VERSION ""

NS_ :

BS_:

BU_: BCM_PB ECM_PB TCM_PB Router_PB APA_PB SBSA_PB EBCM_PB IPC_PB SDM_PB EPS_PB AHL_AFL_PB ECC_PB ESCL_PB Firewall_PB CGM_PB PFAF_PB IBOOST_PB

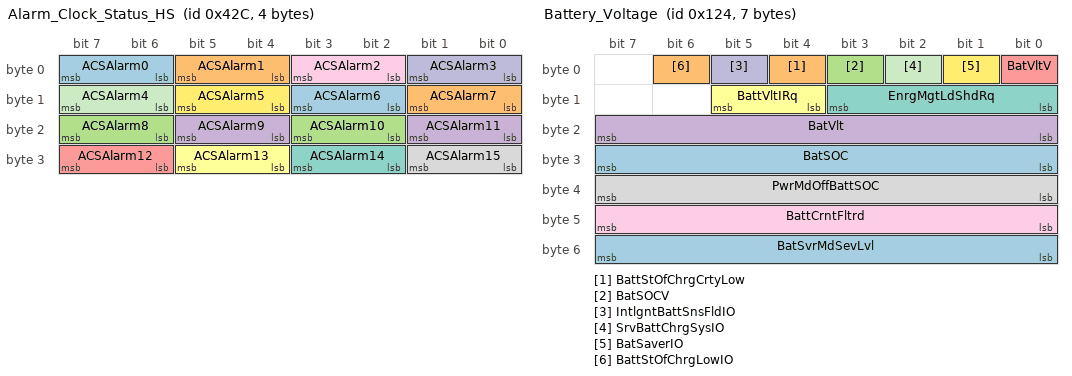
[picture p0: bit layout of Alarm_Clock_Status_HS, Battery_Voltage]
BO_ 1068 Alarm_Clock_Status_HS: 4 BCM_PB
 SG_ ACSAlarm0 : 7|2@0+ (1,0) [0|3] ""  ECC_PB
 SG_ ACSAlarm1 : 5|2@0+ (1,0) [0|3] ""  ECC_PB
 SG_ ACSAlarm10 : 19|2@0+ (1,0) [0|3] ""  ECC_PB
 SG_ ACSAlarm11 : 17|2@0+ (1,0) [0|3] ""  ECC_PB
 SG_ ACSAlarm12 : 31|2@0+ (1,0) [0|3] ""  ECC_PB
 SG_ ACSAlarm13 : 29|2@0+ (1,0) [0|3] ""  ECC_PB
 SG_ ACSAlarm14 : 27|2@0+ (1,0) [0|3] ""  ECC_PB
 SG_ ACSAlarm15 : 25|2@0+ (1,0) [0|3] ""  ECC_PB
 SG_ ACSAlarm2 : 3|2@0+ (1,0) [0|3] ""  ECC_PB
 SG_ ACSAlarm3 : 1|2@0+ (1,0) [0|3] ""  ECC_PB
 SG_ ACSAlarm4 : 15|2@0+ (1,0) [0|3] ""  ECC_PB
 SG_ ACSAlarm5 : 13|2@0+ (1,0) [0|3] ""  ECC_PB
 SG_ ACSAlarm6 : 11|2@0+ (1,0) [0|3] ""  ECC_PB
 SG_ ACSAlarm7 : 9|2@0+ (1,0) [0|3] ""  ECC_PB
 SG_ ACSAlarm8 : 23|2@0+ (1,0) [0|3] ""  ECC_PB
 SG_ ACSAlarm9 : 21|2@0+ (1,0) [0|3] ""  ECC_PB

BO_ 292 Battery_Voltage: 7 BCM_PB
 SG_ BatSOC : 31|8@0+ (0.392157,0) [0|100.000035] "%"  ECC_PB
 SG_ BattStOfChrgCrtyLow : 4|1@0+ (1,0) [0|1] ""  ECC_PB
 SG_ BatSOCV : 3|1@0+ (1,0) [0|1] ""  ECC_PB
 SG_ BatVlt : 23|8@0+ (0.1,3) [3|28.5] "volts"  ECC_PB
 SG_ BatVltV : 0|1@0+ (1,0) [0|1] ""  ECC_PB
 SG_ BattVltIRq : 13|2@0+ (1,0) [0|3] "" Vector__XXX
 SG_ EnrgMgtLdShdRq : 11|4@0+ (1,0) [0|15] ""  ECC_PB
 SG_ PwrMdOffBattSOC : 39|8@0+ (0.392157,0) [0|100.000035] "%" Vector__XXX
 SG_ BattCrntFltrd : 47|8@0- (0.5,0) [-64|63.5] "A"  ECC_PB
 SG_ IntlgntBattSnsFldIO : 5|1@0+ (1,0) [0|1] "" Vector__XXX
 SG_ SrvBattChrgSysIO : 2|1@0+ (1,0) [0|1] "" Vector__XXX
 SG_ BatSaverIO : 1|1@0+ (1,0) [0|1] "" Vector__XXX
 SG_ BatSvrMdSevLvl : 55|8@0+ (1,0) [0|255] "" Vector__XXX
 SG_ BattStOfChrgLowIO : 6|1@0+ (1,0) [0|1] "" Vector__XXX

BO_ 298 Body_Information_HS: 4 BCM_PB
 SG_ DDAjrSwAtv : 9|1@0+ (1,0) [0|1] "" Vector__XXX
 SG_ DDAjrSwAtvM : 5|1@0+ (1,0) [0|1] "" Vector__XXX
 SG_ DrId : 15|3@0+ (1,0) [0|7] ""  ECC_PB
 SG_ PDAjrSwAtv : 10|1@0+ (1,0) [0|1] "" Vector__XXX
 SG_ RLDoorAjarSwAct : 8|1@0+ (1,0) [0|1] "" Vector__XXX
 SG_ RRDoorAjarSwAct : 23|1@0+ (1,0) [0|1] "" Vector__XXX
 SG_ VhSecNImmoIndRq : 7|2@0+ (1,0) [0|3] "" Vector__XXX
 SG_ HillDesCtrlMdSwAct : 22|1@0+ (1,0) [0|1] "" Vector__XXX
 SG_ HillDesCtrlMdSwActV : 11|1@0+ (1,0) [0|1] "" Vector__XXX
 SG_ RrClosAjarSwAct : 12|1@0+ (1,0) [0|1] "" Vector__XXX
 SG_ TCSysDisSwAtv : 28|1@0+ (1,0) [0|1] "" Vector__XXX
 SG_ TCSysDisSwAtvV : 27|1@0+ (1,0) [0|1] "" Vector__XXX
 SG_ VehMovState : 26|3@0+ (1,0) [0|7] "" Vector__XXX
 SG_ WSWshSwAtv : 29|1@0+ (1,0) [0|1] "" Vector__XXX
 SG_ RrClsrSnwLdIO : 21|1@0+ (1,0) [0|1] "" Vector__XXX
 SG_ WSWprAct : 30|1@0+ (1,0) [0|1] "" Vector__XXX
 SG_ HdSt : 1|2@0+ (1,0) [0|3] "" Vector__XXX
 SG_ HdStV : 2|1@0+ (1,0) [0|1] "" Vector__XXX

BO_ 321 Exterior_Lighting_HS: 7 BCM_PB
 SG_ AdvFrntLghtSysEnbld : 3|1@0+ (1,0) [0|1] "" Vector__XXX
 SG_ AutLghtCtrl : 4|1@0+ (1,0) [0|1] "" Vector__XXX
 SG_ BrkLtsAtv : 6|1@0+ (1,0) [0|1] "" Vector__XXX
 SG_ DispNtSchmAtv : 15|1@0+ (1,0) [0|1] ""  ECC_PB
 SG_ DRLAct : 14|1@0+ (1,0) [0|1] "" Vector__XXX
 SG_ FlToPsSwAtv : 5|1@0+ (1,0) [0|1] "" Vector__XXX
 SG_ FrFogLmpsAct : 0|1@0+ (1,0) [0|1] "" Vector__XXX
 SG_ FrFgLtIO : 21|1@0+ (1,0) [0|1] "" Vector__XXX
 SG_ HazSwAtv : 22|1@0+ (1,0) [0|1] "" Vector__XXX
 SG_ HdlmpBmSelectStat : 10|2@0+ (1,0) [0|3] "" Vector__XXX
 SG_ HighBmAct : 7|1@0+ (1,0) [0|1] "" Vector__XXX
 SG_ HiBmIO : 13|1@0+ (1,0) [0|1] "" Vector__XXX
 SG_ IntDimDspLvl : 39|8@0+ (0.392157,0) [0|100.000035] "%"  ECC_PB
 SG_ IntDimLvl : 47|8@0+ (0.392157,0) [0|100.000035] "%"  ECC_PB
 SG_ LftTrnLmpAtv : 25|2@0+ (1,0) [0|3] "" Vector__XXX
 SG_ LowBmAct : 1|1@0+ (1,0) [0|1] "" Vector__XXX
 SG_ MainLghtSw : 12|2@0+ (1,0) [0|3] "" Vector__XXX
 SG_ OtsdAmbtLtLvlStat : 17|2@0+ (1,0) [0|3] "" Vector__XXX
 SG_ OtsdAmbtLtLvlStatV : 2|1@0+ (1,0) [0|1] "" Vector__XXX
 SG_ PrkLtIO : 23|1@0+ (1,0) [0|1] "" Vector__XXX
 SG_ RrFogLmpsAct : 8|1@0+ (1,0) [0|1] "" Vector__XXX
 SG_ RrFgLtIO : 20|1@0+ (1,0) [0|1] "" Vector__XXX
 SG_ RtTrnLmpAtv : 27|2@0+ (1,0) [0|3] "" Vector__XXX
 SG_ TrnSwAct : 19|2@0+ (1,0) [0|3] "" Vector__XXX
 SG_ AutoLtsActIO : 55|1@0+ (1,0) [0|1] "" Vector__XXX
 SG_ PrkLtRightIO : 52|1@0+ (1,0) [0|1] "" Vector__XXX
 SG_ PrkLtLeftIO : 51|1@0+ (1,0) [0|1] "" Vector__XXX
 SG_ IntDimNtPnlAtv : 31|1@0+ (1,0) [0|1] ""  ECC_PB
 SG_ AutoLtsInactIO : 30|1@0+ (1,0) [0|1] "" Vector__XXX
 SG_ AutoBmSlctAllwd : 50|1@0+ (1,0) [0|1] "" Vector__XXX
 SG_ HiBmReqd : 49|1@0+ (1,0) [0|1] "" Vector__XXX
 SG_ RevLmpAtv : 28|1@0+ (1,0) [0|1] "" Vector__XXX

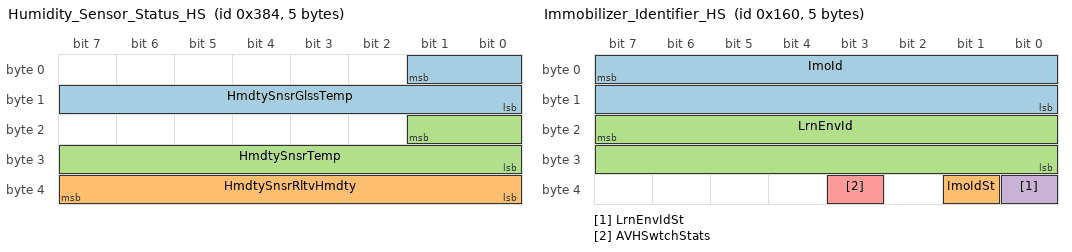
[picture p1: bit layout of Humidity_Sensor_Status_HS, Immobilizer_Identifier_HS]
BO_ 900 Humidity_Sensor_Status_HS: 5 BCM_PB
 SG_ HmdtySnsrGlssTemp : 1|10@0+ (0.146628,-50) [-50|100.000444] "degC"  ECC_PB
 SG_ HmdtySnsrRltvHmdty : 39|8@0+ (0.392157,0) [0|100.000035] "%"  ECC_PB
 SG_ HmdtySnsrTemp : 17|10@0+ (0.146628,-50) [-50|100.000444] "degC"  ECC_PB

BO_ 352 Immobilizer_Identifier_HS: 5 BCM_PB
 SG_ ImoId : 7|16@0+ (1,0) [0|65535] ""  ECC_PB
 SG_ ImoIdSt : 33|1@0+ (1,0) [0|1] ""  ECC_PB
 SG_ LrnEnvId : 23|16@0+ (1,0) [0|65535] ""  ECC_PB
 SG_ LrnEnvIdSt : 32|1@0+ (1,0) [0|1] ""  ECC_PB
 SG_ AVHSwtchStats : 35|1@0+ (1,0) [0|1] "" Vector__XXX

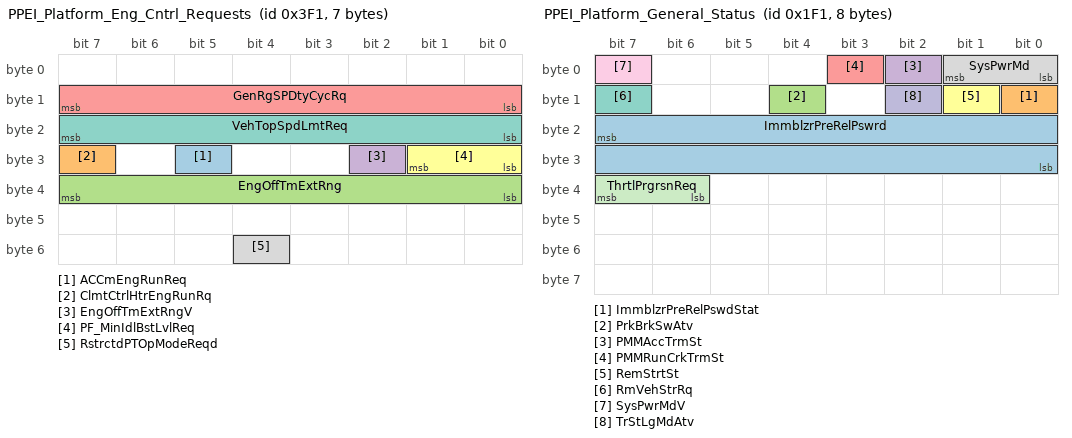
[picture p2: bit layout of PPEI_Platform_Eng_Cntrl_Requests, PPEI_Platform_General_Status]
BO_ 1009 PPEI_Platform_Eng_Cntrl_Requests: 7 BCM_PB
 SG_ ACCmEngRunReq : 29|1@0+ (1,0) [0|1] "" Vector__XXX
 SG_ ClmtCtrlHtrEngRunRq : 31|1@0+ (1,0) [0|1] "" Vector__XXX
 SG_ EngOffTmExtRng : 39|8@0+ (4,0) [0|1020] "min"  ECC_PB
 SG_ EngOffTmExtRngV : 26|1@0+ (1,0) [0|1] ""  ECC_PB
 SG_ GenRgSPDtyCycRq : 15|8@0+ (0.392157,0) [0|100.000035] "%" Vector__XXX
 SG_ PF_MinIdlBstLvlReq : 25|2@0+ (1,0) [0|3] "" Vector__XXX
 SG_ VehTopSpdLmtReq : 23|8@0+ (2,0) [0|510] "km/h" Vector__XXX
 SG_ RstrctdPTOpModeReqd : 52|1@0+ (1,0) [0|1] "" Vector__XXX

BO_ 497 PPEI_Platform_General_Status: 8 BCM_PB
 SG_ ImmblzrPreRelPswrd : 23|16@0+ (1,0) [0|65535] "passwrd" Vector__XXX
 SG_ ImmblzrPreRelPswdStat : 8|1@0+ (1,0) [0|1] "" Vector__XXX
 SG_ PrkBrkSwAtv : 12|1@0+ (1,0) [0|1] "" Vector__XXX
 SG_ PMMAccTrmSt : 2|1@0+ (1,0) [0|1] "" Vector__XXX
 SG_ PMMRunCrkTrmSt : 3|1@0+ (1,0) [0|1] "" Vector__XXX
 SG_ RemStrtSt : 9|1@0+ (1,0) [0|1] ""  ECC_PB
 SG_ RmVehStrRq : 15|1@0+ (1,0) [0|1] "" Vector__XXX
 SG_ SysPwrMd : 1|2@0+ (1,0) [0|3] ""  ECC_PB
 SG_ SysPwrMdV : 7|1@0+ (1,0) [0|1] ""  ECC_PB
 SG_ TrStLgMdAtv : 10|1@0+ (1,0) [0|1] ""  ECC_PB
 SG_ ThrtlPrgrsnReq : 39|2@0+ (1,0) [0|3] "" Vector__XXX

BO_ 1249 PPEI_VIN_Digits_10_to_17: 8 BCM_PB
 SG_ VehIdNmDig10_17 : 7|64@0+ (1,0) [0|1] ""  ECC_PB

BO_ 837 Rear_Window_Defog_Inhibit: 1 BCM_PB
 SG_ RrWndDfgInhRq : 0|1@0+ (1,0) [0|1] ""  ECC_PB
 SG_ RrWndDfgSwAtv : 1|1@0+ (1,0) [0|1] ""  ECC_PB

BO_ 1300 VIN_Digits_2_to_9_HS: 8 BCM_PB
 SG_ VehIdNmDig2_9 : 7|64@0+ (1,0) [0|1] ""  ECC_PB

BO_ 201 PPEI_Engine_General_Status_1: 8 ECM_PB
 SG_ AccActPos : 39|8@0+ (0.392157,0) [0|100.000035] "%" Vector__XXX
 SG_ AccActPosV : 31|1@0+ (1,0) [0|1] "" Vector__XXX
 SG_ CrsCntAtv : 30|1@0+ (1,0) [0|1] "" Vector__XXX
 SG_ CrsCntEnbld : 29|1@0+ (1,0) [0|1] "" Vector__XXX
 SG_ Eng12vStrtrMtrCmmdOn : 53|1@0+ (1,0) [0|1] "" Vector__XXX
 SG_ EngIdlAtv : 2|1@0+ (1,0) [0|1] "" Vector__XXX
 SG_ EngAirIntBstPr : 63|8@0- (1,0) [-128|127] "kPaG" Vector__XXX
 SG_ EngAirIntBstPrV : 51|1@0+ (1,0) [0|1] "" Vector__XXX
 SG_ EngRunAtv : 7|1@0+ (1,0) [0|1] ""  ECC_PB
 SG_ EngSpd : 15|16@0+ (0.25,0) [0|16383.75] "rpm"  ECC_PB
 SG_ EngSpdStat : 1|2@0+ (1,0) [0|3] ""  ECC_PB
 SG_ PT_BrkPedDscrtInpStat : 40|1@0+ (1,0) [0|1] "" Vector__XXX
 SG_ PT_BrkPedDscrtInpStatV : 41|1@0+ (1,0) [0|1] "" Vector__XXX
 SG_ PTCrnkAbrted : 5|1@0+ (1,0) [0|1] "" Vector__XXX
 SG_ PT_CrnkAct : 6|1@0+ (1,0) [0|1] "" Vector__XXX
 SG_ PTRunAbrt : 4|1@0+ (1,0) [0|1] "" Vector__XXX
 SG_ RmVhStrtEngRng : 55|1@0+ (1,0) [0|1] ""  ECC_PB
 SG_ SpdLmtrSpdWrngEnbld : 47|1@0+ (1,0) [0|1] "" Vector__XXX
 SG_ EngCntrlRunCrnkTrmSt : 52|1@0+ (1,0) [0|1] "" Vector__XXX

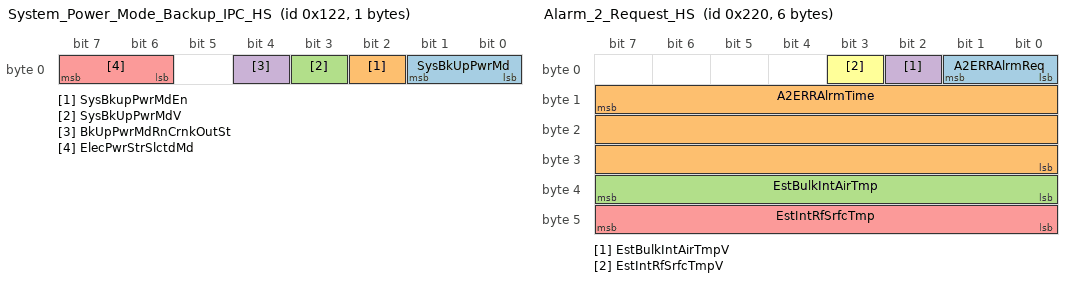
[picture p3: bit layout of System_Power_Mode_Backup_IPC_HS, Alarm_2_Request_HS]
BO_ 290 System_Power_Mode_Backup_IPC_HS: 1 IPC_PB
 SG_ SysBkUpPwrMd : 1|2@0+ (1,0) [0|3] ""  ECC_PB
 SG_ SysBkupPwrMdEn : 2|1@0+ (1,0) [0|1] ""  ECC_PB
 SG_ SysBkUpPwrMdV : 3|1@0+ (1,0) [0|1] ""  ECC_PB
 SG_ BkUpPwrMdRnCrnkOutSt : 4|1@0+ (1,0) [0|1] "" Vector__XXX
 SG_ ElecPwrStrSlctdMd : 7|2@0+ (1,0) [0|3] "" Vector__XXX

BO_ 387 Environment_Id_Resp_2_HS: 3 ECC_PB
 SG_ EnvIdRsp2 : 7|16@0+ (1,0) [0|65535] ""  BCM_PB
 SG_ EnvIdRspSt2 : 17|2@0+ (1,0) [0|3] ""  BCM_PB

BO_ 400 Airbag_Impact_Data: 8 SDM_PB
 SG_ SIRDpl : 1|1@0+ (1,0) [0|1] ""  ECC_PB
 SG_ NotDrvSeatStat : 7|2@0+ (1,0) [0|3] "" Vector__XXX
 SG_ NotiEventCount : 63|8@0+ (1,0) [0|255] "" Vector__XXX
 SG_ NEDLSDrFrSt1De : 46|1@0+ (1,0) [0|1] "" Vector__XXX
 SG_ NEDLSDrFrSt2De : 45|1@0+ (1,0) [0|1] "" Vector__XXX
 SG_ NEDLSLtSdArbgDld : 42|1@0+ (1,0) [0|1] "" Vector__XXX
 SG_ NEDLSPaFrSt1De : 44|1@0+ (1,0) [0|1] "" Vector__XXX
 SG_ NEDLSPaFrSt2De : 43|1@0+ (1,0) [0|1] "" Vector__XXX
 SG_ NEDLSRtSdArbgDld : 41|1@0+ (1,0) [0|1] "" Vector__XXX
 SG_ NEDLSSdCrtnArbgDpld : 40|1@0+ (1,0) [0|1] "" Vector__XXX
 SG_ NESSFrImpPreSevSt : 54|1@0+ (1,0) [0|1] ""  ECC_PB
 SG_ NESSFrImpSt1SevSt : 53|1@0+ (1,0) [0|1] ""  ECC_PB
 SG_ NESSFrImpSt2SevSt : 52|1@0+ (1,0) [0|1] ""  ECC_PB
 SG_ NESSLeSiSevSt : 51|1@0+ (1,0) [0|1] ""  ECC_PB
 SG_ NESSReImpSevSt : 50|1@0+ (1,0) [0|1] ""  ECC_PB
 SG_ NESSRiSiSevSt : 49|1@0+ (1,0) [0|1] ""  ECC_PB
 SG_ NESSRoSevSt : 48|1@0+ (1,0) [0|1] ""  ECC_PB
 SG_ NotEventStat : 17|2@0+ (1,0) [0|3] ""  ECC_PB
 SG_ NotiFrntPasSeatOccSta : 34|3@0+ (1,0) [0|7] "" Vector__XXX
 SG_ NotPsSeatStat : 5|2@0+ (1,0) [0|3] "" Vector__XXX
 SG_ NotSecRowCtSeaOccStat : 27|2@0+ (1,0) [0|3] "" Vector__XXX
 SG_ NotSecRowLeSeaOccStat : 25|2@0+ (1,0) [0|3] "" Vector__XXX
 SG_ NotSndRwLtSeatStat : 15|2@0+ (1,0) [0|3] "" Vector__XXX
 SG_ NotSndRwMdlSeatStat : 11|2@0+ (1,0) [0|3] "" Vector__XXX
 SG_ NotSecRowRtSeaOccStat : 9|2@0+ (1,0) [0|3] "" Vector__XXX
 SG_ NotSndRwRtSeatStat : 13|2@0+ (1,0) [0|3] "" Vector__XXX

BO_ 448 Rear_Window_Defog_Status_HS: 1 ECC_PB
 SG_ RrWndDfgOn : 0|1@0+ (1,0) [0|1] ""  BCM_PB,IPC_PB,Firewall_PB

BO_ 544 Alarm_2_Request_HS: 6 ECC_PB
 SG_ A2ERRAlrmReq : 1|2@0+ (1,0) [0|3] ""  BCM_PB,Firewall_PB
 SG_ A2ERRAlrmTime : 15|24@0+ (1,0) [0|16777215] "min"  BCM_PB,Firewall_PB
 SG_ EstBulkIntAirTmp : 39|8@0+ (0.5,-40) [-40|87.5] "degC"  Firewall_PB
 SG_ EstBulkIntAirTmpV : 2|1@0+ (1,0) [0|1] ""  Firewall_PB
 SG_ EstIntRfSrfcTmp : 47|8@0+ (0.5,-40) [-40|87.5] "degC"  Firewall_PB
 SG_ EstIntRfSrfcTmpV : 3|1@0+ (1,0) [0|1] ""  Firewall_PB

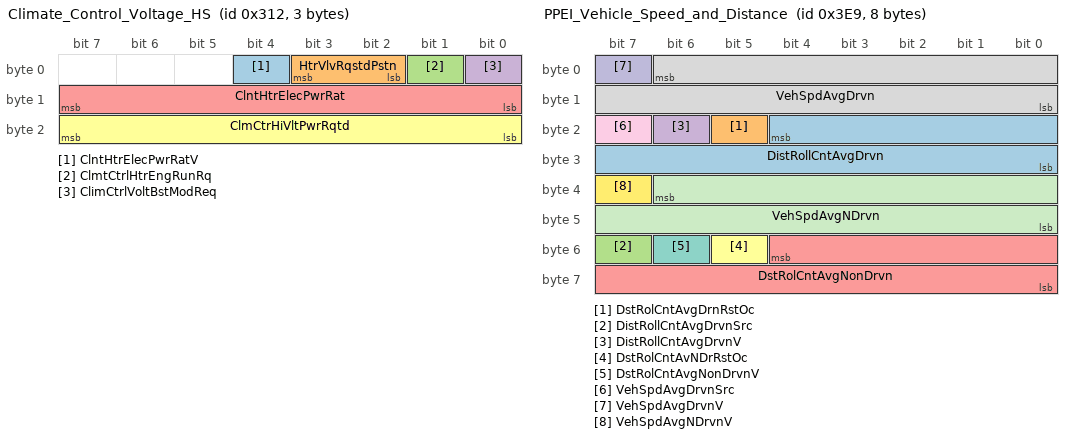
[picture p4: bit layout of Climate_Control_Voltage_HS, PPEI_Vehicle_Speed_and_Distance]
BO_ 786 Climate_Control_Voltage_HS: 3 ECC_PB
 SG_ ClntHtrElecPwrRatV : 4|1@0+ (1,0) [0|1] ""  CGM_PB
 SG_ HtrVlvRqstdPstn : 3|2@0+ (1,0) [0|3] ""  CGM_PB
 SG_ ClmtCtrlHtrEngRunRq : 1|1@0+ (1,0) [0|1] "" Vector__XXX
 SG_ ClimCtrlVoltBstModReq : 0|1@0+ (1,0) [0|1] ""  BCM_PB
 SG_ ClntHtrElecPwrRat : 15|8@0+ (0.04,0) [0|10.2] "kW"  CGM_PB
 SG_ ClmCtrHiVltPwrRqtd : 23|8@0+ (0.1,0) [0|25.5] "kW"  CGM_PB

BO_ 977 PPEI_Engine_General_Status_2: 8 ECM_PB
 SG_ ACCompCmnd : 37|1@0+ (1,0) [0|1] ""  ECC_PB
 SG_ ACCmpNrmLdGrdAld : 63|8@0+ (0.1,0) [0|25.5] "dm3/m/s"  ECC_PB
 SG_ CrsSpdLmtrDrvSelSpd : 19|12@0+ (0.0625,0) [0|255.9375] "km/h" Vector__XXX
 SG_ CrsCntlDrSelSpdAct : 39|1@0+ (1,0) [0|1] "" Vector__XXX
 SG_ EngBstPrsInd : 55|8@0+ (0.392157,0) [0|100.000035] "%" Vector__XXX
 SG_ EngBstPrsIndV : 23|1@0+ (1,0) [0|1] "" Vector__XXX
 SG_ EngCstFlCutAct : 22|1@0+ (1,0) [0|1] ""  ECC_PB
 SG_ EngEmsRelMalfIndReq : 2|3@0+ (1,0) [0|7] "" Vector__XXX
 SG_ EngNEmsnsRelMalfAct : 3|1@0+ (1,0) [0|1] "" Vector__XXX
 SG_ EngOilLifRstPerf : 36|1@0+ (1,0) [0|1] "" Vector__XXX
 SG_ EngOilStrvtnIO : 21|1@0+ (1,0) [0|1] "" Vector__XXX
 SG_ FuelFltLifRstPerf : 38|1@0+ (1,0) [0|1] "" Vector__XXX
 SG_ InstFuelConsmpRate : 35|12@0+ (0.025,0) [0|102.375] "ltrs/hr" Vector__XXX
 SG_ SpdLmtrSpdWrngAct : 4|1@0+ (1,0) [0|1] "" Vector__XXX
 SG_ ThrPos : 15|8@0+ (0.392157,0) [0|100.000035] "%" Vector__XXX
 SG_ ThrPosV : 7|1@0+ (1,0) [0|1] "" Vector__XXX
 SG_ AutoMdSpdLmtStat : 6|2@0+ (1,0) [0|3] "" Vector__XXX

BO_ 1001 PPEI_Vehicle_Speed_and_Distance: 8 ECM_PB
 SG_ DistRollCntAvgDrvn : 20|13@0+ (0.125,0) [0|1023.875] "m" Vector__XXX
 SG_ DstRolCntAvgDrnRstOc : 21|1@0+ (1,0) [0|1] "" Vector__XXX
 SG_ DistRollCntAvgDrvnSrc : 55|1@0+ (1,0) [0|1] "" Vector__XXX
 SG_ DistRollCntAvgDrvnV : 22|1@0+ (1,0) [0|1] "" Vector__XXX
 SG_ DstRolCntAvgNonDrvn : 52|13@0+ (0.125,0) [0|1023.875] "m" Vector__XXX
 SG_ DstRolCntAvNDrRstOc : 53|1@0+ (1,0) [0|1] "" Vector__XXX
 SG_ DstRolCntAvgNonDrvnV : 54|1@0+ (1,0) [0|1] "" Vector__XXX
 SG_ VehSpdAvgDrvn : 6|15@0+ (0.015625,0) [0|511.984375] "km/h"  ECC_PB
 SG_ VehSpdAvgDrvnSrc : 23|1@0+ (1,0) [0|1] "" Vector__XXX
 SG_ VehSpdAvgDrvnV : 7|1@0+ (1,0) [0|1] ""  ECC_PB
 SG_ VehSpdAvgNDrvn : 38|15@0+ (0.015625,0) [0|511.984375] "km/h" Vector__XXX
 SG_ VehSpdAvgNDrvnV : 39|1@0+ (1,0) [0|1] "" Vector__XXX

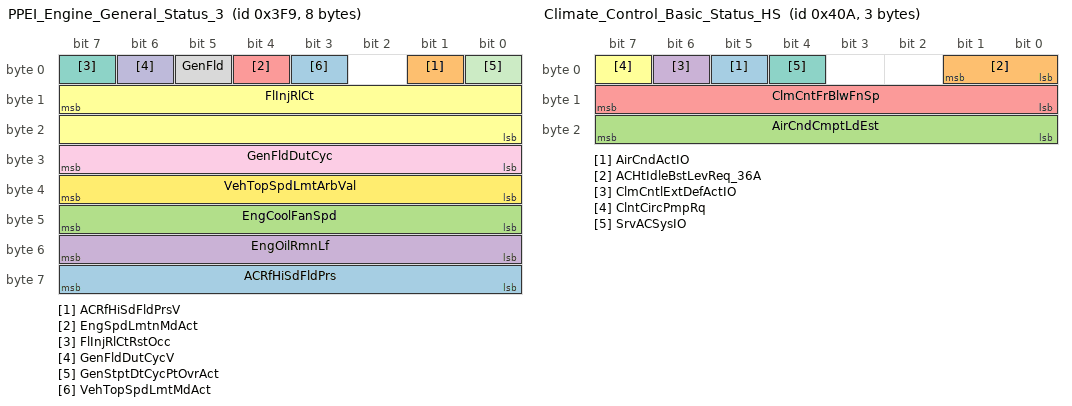
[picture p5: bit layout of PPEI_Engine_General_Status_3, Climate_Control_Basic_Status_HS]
BO_ 1017 PPEI_Engine_General_Status_3: 8 ECM_PB
 SG_ ACRfHiSdFldPrs : 63|8@0+ (14,0) [0|3570] "kPaG"  ECC_PB
 SG_ ACRfHiSdFldPrsV : 1|1@0+ (1,0) [0|1] ""  ECC_PB
 SG_ EngCoolFanSpd : 47|8@0+ (0.392157,0) [0|100.000035] "%"  ECC_PB
 SG_ EngOilRmnLf : 55|8@0+ (0.392157,0) [0|100.000035] "%" Vector__XXX
 SG_ EngSpdLmtnMdAct : 4|1@0+ (1,0) [0|1] "" Vector__XXX
 SG_ FlInjRlCt : 15|16@0+ (3.05176E-005,0) [0|1.999970916] "liters" Vector__XXX
 SG_ FlInjRlCtRstOcc : 7|1@0+ (1,0) [0|1] "" Vector__XXX
 SG_ GenFld : 5|1@0+ (1,0) [0|1] ""  ECC_PB
 SG_ GenFldDutCyc : 31|8@0+ (0.392157,0) [0|100.000035] "%"  ECC_PB
 SG_ GenFldDutCycV : 6|1@0+ (1,0) [0|1] ""  ECC_PB
 SG_ GenStptDtCycPtOvrAct : 0|1@0+ (1,0) [0|1] "" Vector__XXX
 SG_ VehTopSpdLmtArbVal : 39|8@0+ (2,0) [0|510] "km/h" Vector__XXX
 SG_ VehTopSpdLmtMdAct : 3|1@0+ (1,0) [0|1] "" Vector__XXX

BO_ 1034 Climate_Control_Basic_Status_HS: 3 ECC_PB
 SG_ AirCndActIO : 5|1@0+ (1,0) [0|1] ""  IPC_PB,Firewall_PB
 SG_ ACHtIdleBstLevReq_36A : 1|2@0+ (1,0) [0|3] ""  BCM_PB,Firewall_PB
 SG_ AirCndCmptLdEst : 23|8@0+ (0.392157,0) [0|100.000035] "%"  IPC_PB,Firewall_PB
 SG_ ClmCntlExtDefActIO : 6|1@0+ (1,0) [0|1] ""  IPC_PB,Firewall_PB
 SG_ ClmCntFrBlwFnSp : 15|8@0+ (0.392157,0) [0|100.000035] "%"  IPC_PB,Firewall_PB,CGM_PB
 SG_ ClntCircPmpRq : 7|1@0+ (1,0) [0|1] ""  BCM_PB,ECM_PB,Firewall_PB,CGM_PB
 SG_ SrvACSysIO : 4|1@0+ (1,0) [0|1] ""  IPC_PB,Firewall_PB

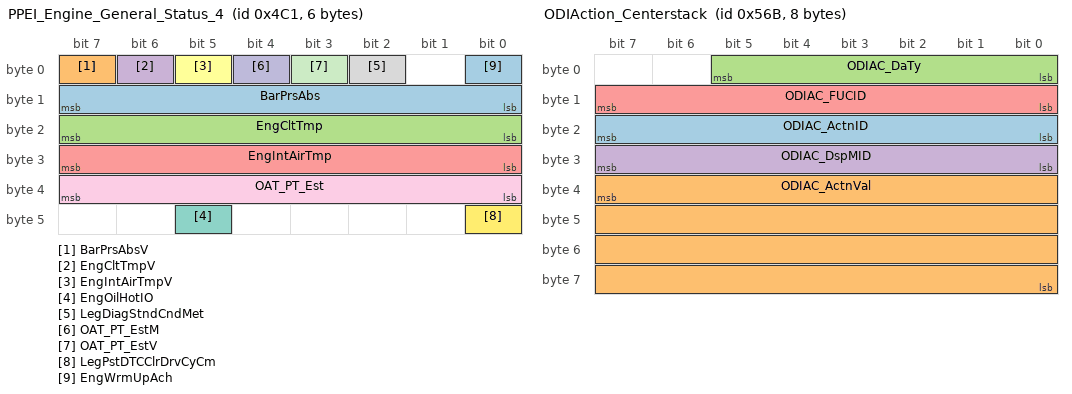
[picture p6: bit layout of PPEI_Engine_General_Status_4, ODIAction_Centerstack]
BO_ 1217 PPEI_Engine_General_Status_4: 6 ECM_PB
 SG_ BarPrsAbs : 15|8@0+ (0.5,0) [0|127.5] "kPa" Vector__XXX
 SG_ BarPrsAbsV : 7|1@0+ (1,0) [0|1] "" Vector__XXX
 SG_ EngCltTmp : 23|8@0+ (1,-40) [-40|215] "degC"  ECC_PB
 SG_ EngCltTmpV : 6|1@0+ (1,0) [0|1] ""  ECC_PB
 SG_ EngIntAirTmp : 31|8@0+ (1,-40) [-40|215] "degC"  ECC_PB
 SG_ EngIntAirTmpV : 5|1@0+ (1,0) [0|1] ""  ECC_PB
 SG_ EngOilHotIO : 45|1@0+ (1,0) [0|1] "" Vector__XXX
 SG_ LegDiagStndCndMet : 2|1@0+ (1,0) [0|1] "" Vector__XXX
 SG_ OAT_PT_Est : 39|8@0+ (0.5,-40) [-40|87.5] "degC"  ECC_PB
 SG_ OAT_PT_EstM : 4|1@0+ (1,0) [0|1] ""  ECC_PB
 SG_ OAT_PT_EstV : 3|1@0+ (1,0) [0|1] ""  ECC_PB
 SG_ LegPstDTCClrDrvCyCm : 40|1@0+ (1,0) [0|1] "" Vector__XXX
 SG_ EngWrmUpAch : 0|1@0+ (1,0) [0|1] "" Vector__XXX

BO_ 1233 PPEI_Engine_General_Status_5: 7 ECM_PB
 SG_ AirCndOffIO : 0|1@0+ (1,0) [0|1] "" Vector__XXX
 SG_ CkFlFilrCapIO : 29|1@0+ (1,0) [0|1] "" Vector__XXX
 SG_ DslGlwPlgIO : 55|1@0+ (1,0) [0|1] "" Vector__XXX
 SG_ EngHt_StpEngIO : 1|1@0+ (1,0) [0|1] "" Vector__XXX
 SG_ EngHotFuelEnrchmntIO : 2|1@0+ (1,0) [0|1] "" Vector__XXX
 SG_ EngOilChngIO : 3|1@0+ (1,0) [0|1] "" Vector__XXX
 SG_ EngOilLvlLwIO : 4|1@0+ (1,0) [0|1] "" Vector__XXX
 SG_ EngOilPrs : 23|8@0+ (4,0) [0|1020] "kPa" Vector__XXX
 SG_ EngOilPrsLwIO : 5|1@0+ (1,0) [0|1] "" Vector__XXX
 SG_ EngOilPrsV : 6|1@0+ (1,0) [0|1] "" Vector__XXX
 SG_ EngOilTmp : 15|8@0+ (1,-40) [-40|215] "degC" Vector__XXX
 SG_ EngOilTmpV : 7|1@0+ (1,0) [0|1] "" Vector__XXX
 SG_ EngShtdwnPndgIO : 49|1@0+ (1,0) [0|1] "" Vector__XXX
 SG_ EngWtrInFlIO : 54|1@0+ (1,0) [0|1] "" Vector__XXX
 SG_ FuelFltChgNwIO : 51|1@0+ (1,0) [0|1] "" Vector__XXX
 SG_ FlLvlPct : 47|8@0+ (0.392157,0) [0|100.000035] "%" Vector__XXX
 SG_ FlLvlPctV : 28|1@0+ (1,0) [0|1] "" Vector__XXX
 SG_ FuelTotCap : 27|12@0+ (0.125,0) [0|511.875] "liters" Vector__XXX
 SG_ PTExPrtclFltrWrn2IO : 50|1@0+ (1,0) [0|1] "" Vector__XXX
 SG_ PTExPrtclFltrWrnIO : 53|1@0+ (1,0) [0|1] "" Vector__XXX
 SG_ PTHiElecLdReqd : 52|1@0+ (1,0) [0|1] ""  ECC_PB
 SG_ RdcdPwrIO : 31|1@0+ (1,0) [0|1] "" Vector__XXX

BO_ 1387 ODIAction_Centerstack: 8 Firewall_PB
 SG_ ODIAC_ActnID : 23|8@0+ (1,0) [0|255] ""  ECC_PB
 SG_ ODIAC_ActnVal : 39|32@0+ (1,0) [0|4294967295] ""  ECC_PB
 SG_ ODIAC_DaTy : 5|6@0+ (1,0) [0|63] ""  ECC_PB
 SG_ ODIAC_DspMID : 31|8@0+ (1,0) [0|255] ""  ECC_PB
 SG_ ODIAC_FUCID : 15|8@0+ (1,0) [0|255] ""  ECC_PB

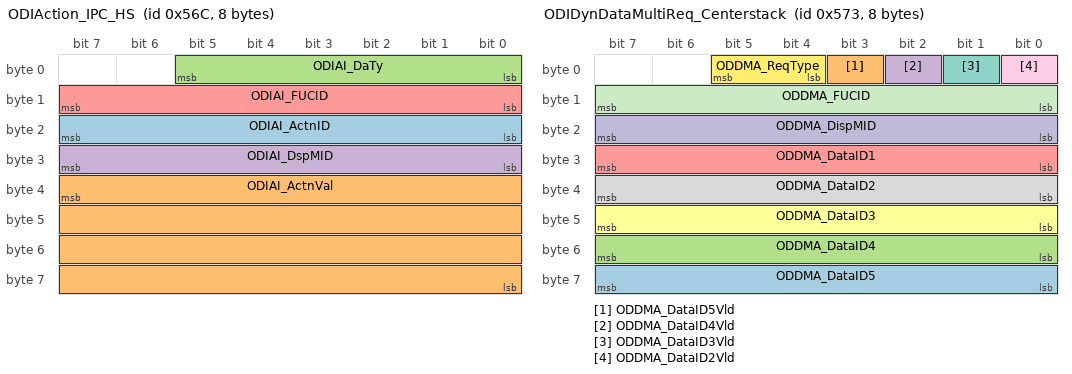
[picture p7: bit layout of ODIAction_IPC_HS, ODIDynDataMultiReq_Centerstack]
BO_ 1388 ODIAction_IPC_HS: 8 IPC_PB
 SG_ ODIAI_ActnID : 23|8@0+ (1,0) [0|255] ""  ECC_PB
 SG_ ODIAI_ActnVal : 39|32@0+ (1,0) [0|4294967295] ""  ECC_PB
 SG_ ODIAI_DaTy : 5|6@0+ (1,0) [0|63] ""  ECC_PB
 SG_ ODIAI_DspMID : 31|8@0+ (1,0) [0|255] ""  ECC_PB
 SG_ ODIAI_FUCID : 15|8@0+ (1,0) [0|255] ""  ECC_PB

BO_ 1395 ODIDynDataMultiReq_Centerstack: 8 Firewall_PB
 SG_ ODDMA_DataID5 : 63|8@0+ (1,0) [0|255] ""  ECC_PB
 SG_ ODDMA_DataID5Vld : 3|1@0+ (1,0) [0|1] ""  ECC_PB
 SG_ ODDMA_DataID4 : 55|8@0+ (1,0) [0|255] ""  ECC_PB
 SG_ ODDMA_DataID4Vld : 2|1@0+ (1,0) [0|1] ""  ECC_PB
 SG_ ODDMA_DataID1 : 31|8@0+ (1,0) [0|255] ""  ECC_PB
 SG_ ODDMA_DataID3 : 47|8@0+ (1,0) [0|255] ""  ECC_PB
 SG_ ODDMA_DataID3Vld : 1|1@0+ (1,0) [0|1] ""  ECC_PB
 SG_ ODDMA_DataID2 : 39|8@0+ (1,0) [0|255] ""  ECC_PB
 SG_ ODDMA_DataID2Vld : 0|1@0+ (1,0) [0|1] ""  ECC_PB
 SG_ ODDMA_DispMID : 23|8@0+ (1,0) [0|255] ""  ECC_PB
 SG_ ODDMA_FUCID : 15|8@0+ (1,0) [0|255] ""  ECC_PB
 SG_ ODDMA_ReqType : 5|2@0+ (1,0) [0|3] ""  ECC_PB

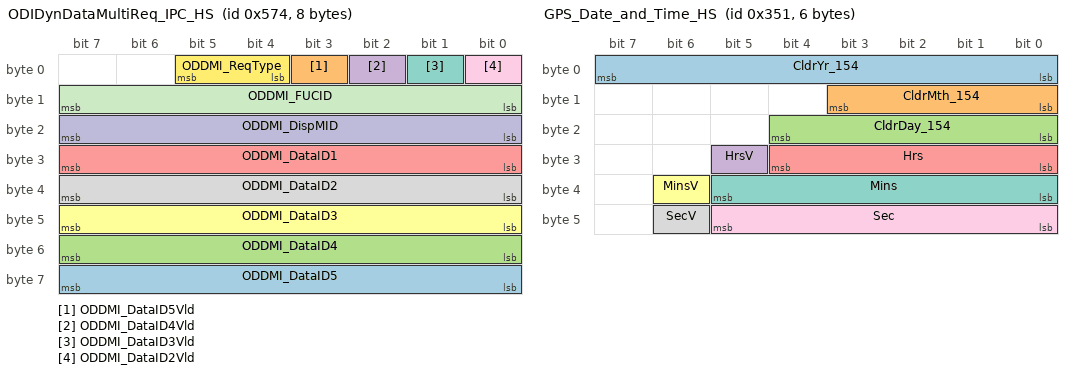
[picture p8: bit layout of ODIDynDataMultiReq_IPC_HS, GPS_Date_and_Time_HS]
BO_ 1396 ODIDynDataMultiReq_IPC_HS: 8 IPC_PB
 SG_ ODDMI_DataID5 : 63|8@0+ (1,0) [0|255] ""  ECC_PB
 SG_ ODDMI_DataID5Vld : 3|1@0+ (1,0) [0|1] ""  ECC_PB
 SG_ ODDMI_DataID4 : 55|8@0+ (1,0) [0|255] ""  ECC_PB
 SG_ ODDMI_DataID4Vld : 2|1@0+ (1,0) [0|1] ""  ECC_PB
 SG_ ODDMI_DataID1 : 31|8@0+ (1,0) [0|255] ""  ECC_PB
 SG_ ODDMI_DataID3 : 47|8@0+ (1,0) [0|255] ""  ECC_PB
 SG_ ODDMI_DataID3Vld : 1|1@0+ (1,0) [0|1] ""  ECC_PB
 SG_ ODDMI_DataID2 : 39|8@0+ (1,0) [0|255] ""  ECC_PB
 SG_ ODDMI_DataID2Vld : 0|1@0+ (1,0) [0|1] ""  ECC_PB
 SG_ ODDMI_DispMID : 23|8@0+ (1,0) [0|255] ""  ECC_PB
 SG_ ODDMI_FUCID : 15|8@0+ (1,0) [0|255] ""  ECC_PB
 SG_ ODDMI_ReqType : 5|2@0+ (1,0) [0|3] ""  ECC_PB

BO_ 849 GPS_Date_and_Time_HS: 6 Firewall_PB
 SG_ CldrYr_154 : 7|8@0+ (1,2000) [2000|2255] "year" Vector__XXX
 SG_ CldrMth_154 : 11|4@0+ (1,0) [0|15] ""  ECC_PB
 SG_ CldrDay_154 : 20|5@0+ (1,0) [0|31] "days"  ECC_PB
 SG_ HrsV : 29|1@0+ (1,0) [0|1] ""  ECC_PB
 SG_ Hrs : 28|5@0+ (1,0) [0|31] "h"  ECC_PB
 SG_ MinsV : 38|1@0+ (1,0) [0|1] ""  ECC_PB
 SG_ Mins : 37|6@0+ (1,0) [0|63] "min"  ECC_PB
 SG_ SecV : 46|1@0+ (1,0) [0|1] "" Vector__XXX
 SG_ Sec : 45|6@0+ (1,0) [0|63] "s" Vector__XXX

BO_ 500 PPEI_Drv_Pref_Mode_Switch_Status: 5 ECM_PB
 SG_ DrvSelMd1Stat : 15|1@0+ (1,0) [0|1] ""  ECC_PB
 SG_ DrvSelMd1ReqDnd : 14|1@0+ (1,0) [0|1] "" Vector__XXX
 SG_ DrvSelMd2Stat : 13|1@0+ (1,0) [0|1] ""  ECC_PB
 SG_ DrvSelMd2ReqDnd : 12|1@0+ (1,0) [0|1] "" Vector__XXX
 SG_ DrvSelMd3Stat : 11|1@0+ (1,0) [0|1] ""  ECC_PB
 SG_ DrvSelMd3ReqDnd : 10|1@0+ (1,0) [0|1] "" Vector__XXX
 SG_ DrvSelMd4Stat : 9|1@0+ (1,0) [0|1] ""  ECC_PB
 SG_ DrvSelMd4ReqDnd : 8|1@0+ (1,0) [0|1] "" Vector__XXX
 SG_ DrvSelMd5Stat : 23|1@0+ (1,0) [0|1] ""  ECC_PB
 SG_ DrvSelMd5ReqDnd : 22|1@0+ (1,0) [0|1] "" Vector__XXX
 SG_ DrvSelMd6Stat : 21|1@0+ (1,0) [0|1] ""  ECC_PB
 SG_ DrvSelMd6ReqDnd : 20|1@0+ (1,0) [0|1] "" Vector__XXX
 SG_ DrvSelMd7Stat : 19|1@0+ (1,0) [0|1] ""  ECC_PB
 SG_ DrvSelMd7ReqDnd : 18|1@0+ (1,0) [0|1] "" Vector__XXX
 SG_ DrvSelMd8Stat : 17|1@0+ (1,0) [0|1] ""  ECC_PB
 SG_ DrvSelMd8ReqDnd : 16|1@0+ (1,0) [0|1] "" Vector__XXX
 SG_ DSMSS_DrvSelMd1Un : 31|1@0+ (1,0) [0|1] "" Vector__XXX
 SG_ DSMSS_DrvSelMd2Un : 30|1@0+ (1,0) [0|1] "" Vector__XXX
 SG_ DSMSS_DrvSelMd3Un : 29|1@0+ (1,0) [0|1] "" Vector__XXX
 SG_ DSMSS_DrvSelMd4Un : 28|1@0+ (1,0) [0|1] "" Vector__XXX
 SG_ DSMSS_DrvSelMd5Un : 27|1@0+ (1,0) [0|1] "" Vector__XXX
 SG_ DSMSS_DrvSelMd6Un : 26|1@0+ (1,0) [0|1] "" Vector__XXX
 SG_ DSMSS_DrvSelMd7Un : 25|1@0+ (1,0) [0|1] "" Vector__XXX
 SG_ DSMSS_DrvSelMd8Un : 24|1@0+ (1,0) [0|1] "" Vector__XXX
 SG_ DSMSS_DrvSelMd1Pn : 39|1@0+ (1,0) [0|1] "" Vector__XXX
 SG_ DSMSS_DrvSelMd2Pn : 38|1@0+ (1,0) [0|1] "" Vector__XXX
 SG_ DSMSS_DrvSelMd3Pn : 37|1@0+ (1,0) [0|1] "" Vector__XXX
 SG_ DSMSS_DrvSelMd4Pn : 36|1@0+ (1,0) [0|1] "" Vector__XXX
 SG_ DSMSS_DrvSelMd5Pn : 35|1@0+ (1,0) [0|1] "" Vector__XXX
 SG_ DSMSS_DrvSelMd6Pn : 34|1@0+ (1,0) [0|1] "" Vector__XXX
 SG_ DSMSS_DrvSelMd7Pn : 33|1@0+ (1,0) [0|1] "" Vector__XXX
 SG_ DSMSS_DrvSelMd8Pn : 32|1@0+ (1,0) [0|1] "" Vector__XXX
 SG_ DSMSS_DrvSelMd0Pn : 7|1@0+ (1,0) [0|1] "" Vector__XXX

BO_ 1569 Network_Management_BCM: 8 BCM_PB
 SG_ SrcNodeID : 7|8@0+ (1,0) [0|255] ""  ECC_PB
 SG_ UDat : 23|48@0+ (1,0) [0|281474976710655] ""  ECC_PB

BO_ 1580 Network_Management_IPC: 8 IPC_PB
 SG_ SrcNodeID : 7|8@0+ (1,0) [0|255] ""  ECC_PB
 SG_ UDat : 23|48@0+ (1,0) [0|281474976710655] ""  ECC_PB

BO_ 1584 Network_Management_AHL_AFL: 8 AHL_AFL_PB
 SG_ SrcNodeID : 7|8@0+ (1,0) [0|255] ""  ECC_PB
 SG_ UDat : 23|48@0+ (1,0) [0|281474976710655] ""  ECC_PB

BO_ 1586 Network_Management_APA: 8 APA_PB
 SG_ SrcNodeID : 7|8@0+ (1,0) [0|255] ""  ECC_PB
 SG_ UDat : 23|48@0+ (1,0) [0|281474976710655] ""  ECC_PB

BO_ 1594 Network_Management_EBCM: 8 EBCM_PB
 SG_ SrcNodeID : 7|8@0+ (1,0) [0|255] ""  ECC_PB
 SG_ UDat : 23|48@0+ (1,0) [0|281474976710655] ""  ECC_PB

BO_ 1585 Network_Management_ECC: 8 ECC_PB
 SG_ SrcNodeID : 7|8@0+ (1,0) [0|255] ""  BCM_PB,IPC_PB,AHL_AFL_PB,APA_PB,SBSA_PB,EBCM_PB,ECM_PB,EPS_PB,ESCL_PB,Firewall_PB,SDM_PB,TCM_PB,CGM_PB,PFAF_PB,IBOOST_PB
 SG_ UDat : 23|48@0+ (1,0) [0|281474976710655] ""  BCM_PB,IPC_PB,AHL_AFL_PB,APA_PB,SBSA_PB,EBCM_PB,ECM_PB,EPS_PB,ESCL_PB,Firewall_PB,SDM_PB,TCM_PB,CGM_PB,PFAF_PB,IBOOST_PB

BO_ 1600 Network_Management_ECM: 8 ECM_PB
 SG_ SrcNodeID : 7|8@0+ (1,0) [0|255] ""  ECC_PB
 SG_ UDat : 23|48@0+ (1,0) [0|281474976710655] ""  ECC_PB

BO_ 1595 Network_Management_EPS: 8 EPS_PB
 SG_ SrcNodeID : 7|8@0+ (1,0) [0|255] ""  ECC_PB
 SG_ UDat : 23|48@0+ (1,0) [0|281474976710655] ""  ECC_PB

BO_ 1596 Network_Management_ESCL: 8 ESCL_PB
 SG_ SrcNodeID : 7|8@0+ (1,0) [0|255] ""  ECC_PB
 SG_ UDat : 23|48@0+ (1,0) [0|281474976710655] ""  ECC_PB

BO_ 1589 Network_Management_FCM: 8 Firewall_PB
 SG_ SrcNodeID : 7|8@0+ (1,0) [0|255] ""  ECC_PB
 SG_ UDat : 23|48@0+ (1,0) [0|281474976710655] ""  ECC_PB

BO_ 1598 Network_Management_ONSTAR: 8 Firewall_PB
 SG_ SrcNodeID : 7|8@0+ (1,0) [0|255] ""  ECC_PB
 SG_ UDat : 23|48@0+ (1,0) [0|281474976710655] ""  ECC_PB

BO_ 1572 Network_Management_RadioHead: 8 Firewall_PB
 SG_ SrcNodeID : 7|8@0+ (1,0) [0|255] ""  ECC_PB
 SG_ UDat : 23|48@0+ (1,0) [0|281474976710655] ""  ECC_PB

BO_ 1593 Network_Management_SDM: 8 SDM_PB
 SG_ SrcNodeID : 7|8@0+ (1,0) [0|255] ""  ECC_PB
 SG_ UDat : 23|48@0+ (1,0) [0|281474976710655] ""  ECC_PB

BO_ 1576 Network_Management_Firewall: 8 Firewall_PB
 SG_ SrcNodeID : 7|8@0+ (1,0) [0|255] ""  ECC_PB
 SG_ UDat : 23|48@0+ (1,0) [0|281474976710655] ""  ECC_PB

BO_ 1599 Network_Management_TCM: 8 TCM_PB
 SG_ SrcNodeID : 7|8@0+ (1,0) [0|255] ""  ECC_PB
 SG_ UDat : 23|48@0+ (1,0) [0|281474976710655] ""  ECC_PB

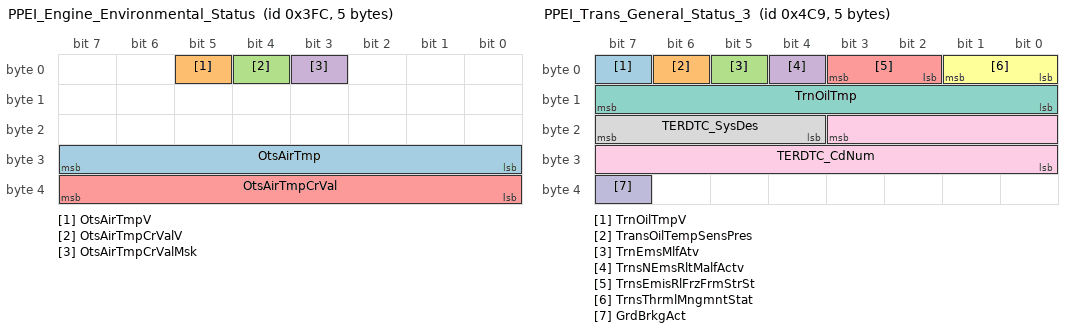
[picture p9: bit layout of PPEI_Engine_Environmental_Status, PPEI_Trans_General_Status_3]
BO_ 1020 PPEI_Engine_Environmental_Status: 5 ECM_PB
 SG_ OtsAirTmp : 31|8@0+ (0.5,-40) [-40|87.5] "degC"  ECC_PB
 SG_ OtsAirTmpV : 5|1@0+ (1,0) [0|1] ""  ECC_PB
 SG_ OtsAirTmpCrValV : 4|1@0+ (1,0) [0|1] ""  ECC_PB
 SG_ OtsAirTmpCrValMsk : 3|1@0+ (1,0) [0|1] ""  ECC_PB
 SG_ OtsAirTmpCrVal : 39|8@0+ (0.5,-40) [-40|87.5] "degC"  ECC_PB

BO_ 1225 PPEI_Trans_General_Status_3: 5 TCM_PB
 SG_ TrnOilTmpV : 7|1@0+ (1,0) [0|1] ""  ECC_PB
 SG_ TransOilTempSensPres : 6|1@0+ (1,0) [0|1] "" Vector__XXX
 SG_ TrnEmsMlfAtv : 5|1@0+ (1,0) [0|1] "" Vector__XXX
 SG_ TrnsNEmsRltMalfActv : 4|1@0+ (1,0) [0|1] "" Vector__XXX
 SG_ TrnsEmisRlFrzFrmStrSt : 3|2@0+ (1,0) [0|3] "" Vector__XXX
 SG_ TrnsThrmlMngmntStat : 1|2@0+ (1,0) [0|3] "" Vector__XXX
 SG_ TrnOilTmp : 15|8@0+ (1,-40) [-40|215] "degC"  ECC_PB
 SG_ TERDTC_SysDes : 23|4@0+ (1,0) [0|15] "" Vector__XXX
 SG_ TERDTC_CdNum : 19|12@0+ (1,0) [0|4095] "" Vector__XXX
 SG_ GrdBrkgAct : 39|1@0+ (1,0) [0|1] "" Vector__XXX

BO_ 917 Air_Conditioning_Comp_Type_HS: 1 ECC_PB
 SG_ HVHtrFldIO : 4|1@0+ (1,0) [0|1] ""  IPC_PB
 SG_ HVHtrOvrTmpIndOn : 3|1@0+ (1,0) [0|1] ""  IPC_PB

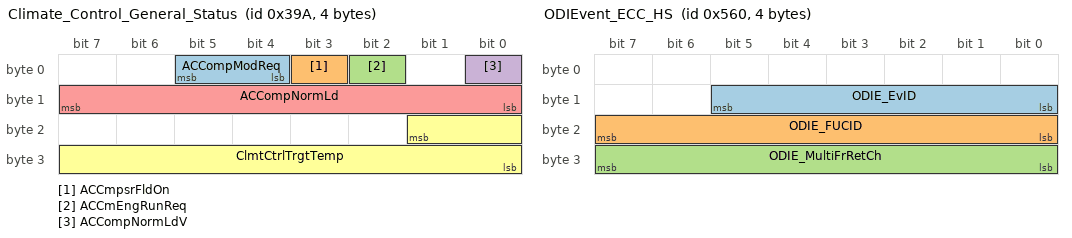
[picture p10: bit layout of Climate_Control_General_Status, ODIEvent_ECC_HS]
BO_ 922 Climate_Control_General_Status: 4 ECC_PB
 SG_ ACCompModReq : 5|2@0+ (1,0) [0|3] ""  ECM_PB,Firewall_PB,CGM_PB
 SG_ ACCmpsrFldOn : 3|1@0+ (1,0) [0|1] ""  ECM_PB,Firewall_PB,CGM_PB
 SG_ ACCmEngRunReq : 2|1@0+ (1,0) [0|1] ""  Firewall_PB
 SG_ ACCompNormLdV : 0|1@0+ (1,0) [0|1] ""  ECM_PB,Firewall_PB,CGM_PB
 SG_ ACCompNormLd : 15|8@0+ (0.1,0) [0|25.5] "l/min"  ECM_PB,Firewall_PB,CGM_PB
 SG_ ClmtCtrlTrgtTemp : 17|10@0+ (0.1,-10) [-10|92.3] "degC"  CGM_PB

BO_ 1036 HVAC_PowerManager_Status_HS: 1 ECC_PB
 SG_ ClmCntBatSaverIO : 5|1@0+ (1,0) [0|1] ""  IPC_PB

BO_ 1376 ODIEvent_ECC_HS: 4 ECC_PB
 SG_ ODIE_EvID : 13|6@0+ (1,0) [0|0] ""  IPC_PB,Firewall_PB
 SG_ ODIE_FUCID : 23|8@0+ (1,0) [0|0] ""  IPC_PB,Firewall_PB
 SG_ ODIE_MultiFrRetCh : 31|8@0+ (1,0) [0|0] ""  IPC_PB,Firewall_PB

BO_ 1384 ODIIndication_ECC_HS: 8 ECC_PB
 SG_ ODII_FUCID : 7|8@0+ (1,0) [0|0] ""  IPC_PB,Firewall_PB
 SG_ ODII_ODIInd1 : 15|1@0+ (1,0) [0|1] ""  IPC_PB,Firewall_PB
 SG_ ODII_ODIInd2 : 14|1@0+ (1,0) [0|1] ""  IPC_PB,Firewall_PB
 SG_ ODII_ODIInd3 : 13|1@0+ (1,0) [0|1] ""  IPC_PB,Firewall_PB
 SG_ ODII_ODIInd4 : 12|1@0+ (1,0) [0|1] ""  IPC_PB,Firewall_PB
 SG_ ODII_ODIInd5 : 11|1@0+ (1,0) [0|1] ""  IPC_PB,Firewall_PB
 SG_ ODII_ODIInd6 : 10|1@0+ (1,0) [0|1] ""  IPC_PB,Firewall_PB
 SG_ ODII_ODIInd7 : 9|1@0+ (1,0) [0|1] ""  IPC_PB,Firewall_PB
 SG_ ODII_ODIInd8 : 8|1@0+ (1,0) [0|1] ""  IPC_PB,Firewall_PB
 SG_ ODII_ODIInd9 : 23|1@0+ (1,0) [0|1] ""  IPC_PB,Firewall_PB
 SG_ ODII_ODIInd10 : 22|1@0+ (1,0) [0|1] ""  IPC_PB,Firewall_PB
 SG_ ODII_ODIInd11 : 21|1@0+ (1,0) [0|1] ""  IPC_PB,Firewall_PB
 SG_ ODII_ODIInd12 : 20|1@0+ (1,0) [0|1] ""  IPC_PB,Firewall_PB
 SG_ ODII_ODIInd13 : 19|1@0+ (1,0) [0|1] ""  IPC_PB,Firewall_PB
 SG_ ODII_ODIInd14 : 18|1@0+ (1,0) [0|1] ""  IPC_PB,Firewall_PB
 SG_ ODII_ODIInd15 : 17|1@0+ (1,0) [0|1] ""  IPC_PB,Firewall_PB
 SG_ ODII_ODIInd16 : 16|1@0+ (1,0) [0|1] ""  IPC_PB,Firewall_PB
 SG_ ODII_ODIInd17 : 31|1@0+ (1,0) [0|1] ""  IPC_PB,Firewall_PB
 SG_ ODII_ODIInd18 : 30|1@0+ (1,0) [0|1] ""  IPC_PB,Firewall_PB
 SG_ ODII_ODIInd19 : 29|1@0+ (1,0) [0|1] ""  IPC_PB,Firewall_PB
 SG_ ODII_ODIInd20 : 28|1@0+ (1,0) [0|1] ""  IPC_PB,Firewall_PB
 SG_ ODII_ODIInd21 : 27|1@0+ (1,0) [0|1] ""  IPC_PB,Firewall_PB
 SG_ ODII_ODIInd22 : 26|1@0+ (1,0) [0|1] ""  IPC_PB,Firewall_PB
 SG_ ODII_ODIInd23 : 25|1@0+ (1,0) [0|1] ""  IPC_PB,Firewall_PB
 SG_ ODII_ODIInd24 : 24|1@0+ (1,0) [0|1] ""  IPC_PB,Firewall_PB
 SG_ ODII_ODIInd25 : 39|1@0+ (1,0) [0|1] ""  IPC_PB,Firewall_PB
 SG_ ODII_ODIInd26 : 38|1@0+ (1,0) [0|1] ""  IPC_PB,Firewall_PB
 SG_ ODII_ODIInd27 : 37|1@0+ (1,0) [0|1] ""  IPC_PB,Firewall_PB
 SG_ ODII_ODIInd28 : 36|1@0+ (1,0) [0|1] ""  IPC_PB,Firewall_PB
 SG_ ODII_ODIInd29 : 35|1@0+ (1,0) [0|1] ""  IPC_PB,Firewall_PB
 SG_ ODII_ODIInd30 : 34|1@0+ (1,0) [0|1] ""  IPC_PB,Firewall_PB
 SG_ ODII_ODIInd31 : 33|1@0+ (1,0) [0|1] ""  IPC_PB,Firewall_PB
 SG_ ODII_ODIInd32 : 32|1@0+ (1,0) [0|1] ""  IPC_PB,Firewall_PB
 SG_ ODII_ODIInd33 : 47|1@0+ (1,0) [0|1] ""  IPC_PB,Firewall_PB
 SG_ ODII_ODIInd34 : 46|1@0+ (1,0) [0|1] ""  IPC_PB,Firewall_PB
 SG_ ODII_ODIInd35 : 45|1@0+ (1,0) [0|1] ""  IPC_PB,Firewall_PB
 SG_ ODII_ODIInd36 : 44|1@0+ (1,0) [0|1] ""  IPC_PB,Firewall_PB
 SG_ ODII_ODIInd37 : 43|1@0+ (1,0) [0|1] ""  IPC_PB,Firewall_PB
 SG_ ODII_ODIInd38 : 42|1@0+ (1,0) [0|1] ""  IPC_PB,Firewall_PB
 SG_ ODII_ODIInd39 : 41|1@0+ (1,0) [0|1] ""  IPC_PB,Firewall_PB
 SG_ ODII_ODIInd40 : 40|1@0+ (1,0) [0|1] ""  IPC_PB,Firewall_PB
 SG_ ODII_ODIInd41 : 55|1@0+ (1,0) [0|1] ""  IPC_PB,Firewall_PB
 SG_ ODII_ODIInd42 : 54|1@0+ (1,0) [0|1] ""  IPC_PB,Firewall_PB
 SG_ ODII_ODIInd43 : 53|1@0+ (1,0) [0|1] ""  IPC_PB,Firewall_PB
 SG_ ODII_ODIInd44 : 52|1@0+ (1,0) [0|1] ""  IPC_PB,Firewall_PB
 SG_ ODII_ODIInd45 : 51|1@0+ (1,0) [0|1] ""  IPC_PB,Firewall_PB
 SG_ ODII_ODIInd46 : 50|1@0+ (1,0) [0|1] ""  IPC_PB,Firewall_PB
 SG_ ODII_ODIInd47 : 49|1@0+ (1,0) [0|1] ""  IPC_PB,Firewall_PB
 SG_ ODII_ODIInd48 : 48|1@0+ (1,0) [0|1] ""  IPC_PB,Firewall_PB
 SG_ ODII_ODIInd49 : 63|1@0+ (1,0) [0|1] ""  IPC_PB,Firewall_PB
 SG_ ODII_ODIInd50 : 62|1@0+ (1,0) [0|1] ""  IPC_PB,Firewall_PB
 SG_ ODII_ODIInd51 : 61|1@0+ (1,0) [0|1] ""  IPC_PB,Firewall_PB
 SG_ ODII_ODIInd52 : 60|1@0+ (1,0) [0|1] ""  IPC_PB,Firewall_PB
 SG_ ODII_ODIInd53 : 59|1@0+ (1,0) [0|1] ""  IPC_PB,Firewall_PB
 SG_ ODII_ODIInd54 : 58|1@0+ (1,0) [0|1] ""  IPC_PB,Firewall_PB
 SG_ ODII_ODIInd55 : 57|1@0+ (1,0) [0|1] ""  IPC_PB,Firewall_PB
 SG_ ODII_ODIInd56 : 56|1@0+ (1,0) [0|1] ""  IPC_PB,Firewall_PB

BO_ 1419 ODIEnumDynamicData_ECC_HS: 8 ECC_PB
 SG_ ODIEDD_Data1Value : 5|3@0+ (1,0) [0|7] ""  IPC_PB,Firewall_PB
 SG_ ODIEDD_Data2Value : 2|3@0+ (1,0) [0|7] ""  IPC_PB,Firewall_PB
 SG_ ODIEDD_Data3Value : 15|3@0+ (1,0) [0|7] ""  IPC_PB,Firewall_PB
 SG_ ODIEDD_Data4Value : 12|3@0+ (1,0) [0|7] ""  IPC_PB,Firewall_PB
 SG_ ODIEDD_Data5Value : 9|3@0+ (1,0) [0|7] ""  IPC_PB,Firewall_PB
 SG_ ODIEDD_Data6Value : 22|3@0+ (1,0) [0|7] ""  IPC_PB,Firewall_PB
 SG_ ODIEDD_Data7Value : 19|3@0+ (1,0) [0|7] ""  IPC_PB,Firewall_PB
 SG_ ODIEDD_Data8Value : 16|3@0+ (1,0) [0|7] ""  IPC_PB,Firewall_PB
 SG_ ODIEDD_Data9Value : 29|3@0+ (1,0) [0|7] ""  IPC_PB,Firewall_PB
 SG_ ODIEDD_Data10Value : 26|3@0+ (1,0) [0|7] ""  IPC_PB,Firewall_PB
 SG_ ODIEDD_Data11Value : 39|3@0+ (1,0) [0|7] ""  IPC_PB,Firewall_PB
 SG_ ODIEDD_Data12Value : 36|3@0+ (1,0) [0|7] ""  IPC_PB,Firewall_PB
 SG_ ODIEDD_Data13Value : 33|3@0+ (1,0) [0|7] ""  IPC_PB,Firewall_PB
 SG_ ODIEDD_Data14Value : 46|3@0+ (1,0) [0|7] ""  IPC_PB,Firewall_PB
 SG_ ODIEDD_Data15Value : 43|3@0+ (1,0) [0|7] ""  IPC_PB,Firewall_PB
 SG_ ODIEDD_Data16Value : 40|3@0+ (1,0) [0|7] ""  IPC_PB,Firewall_PB
 SG_ ODIEDD_Data17Value : 53|3@0+ (1,0) [0|7] ""  IPC_PB,Firewall_PB
 SG_ ODIEDD_Data18Value : 50|3@0+ (1,0) [0|7] ""  IPC_PB,Firewall_PB
 SG_ ODIEDD_FUCID : 63|8@0+ (1,0) [0|255] ""  IPC_PB,Firewall_PB

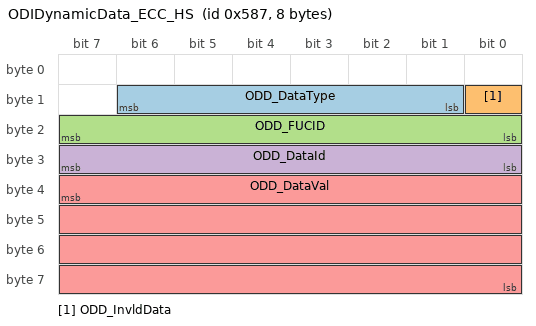
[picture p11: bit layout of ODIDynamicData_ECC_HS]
BO_ 1415 ODIDynamicData_ECC_HS: 8 ECC_PB
 SG_ ODD_DataType : 14|6@0+ (1,0) [0|63] ""  IPC_PB,Firewall_PB
 SG_ ODD_InvldData : 8|1@0+ (1,0) [0|1] ""  IPC_PB,Firewall_PB
 SG_ ODD_FUCID : 23|8@0+ (1,0) [0|0] ""  IPC_PB,Firewall_PB
 SG_ ODD_DataId : 31|8@0+ (1,0) [0|0] ""  IPC_PB,Firewall_PB
 SG_ ODD_DataVal : 39|32@0+ (1,0) [0|0] ""  IPC_PB,Firewall_PB

BO_TX_BU_ 201 : ECM_PB,CGM_PB;
BO_TX_BU_ 977 : ECM_PB,CGM_PB;
BO_TX_BU_ 1001 : ECM_PB,CGM_PB;
BO_TX_BU_ 1017 : ECM_PB,CGM_PB;
BO_TX_BU_ 1217 : ECM_PB,CGM_PB;
BO_TX_BU_ 1233 : ECM_PB,CGM_PB;
BO_TX_BU_ 500 : ECM_PB,CGM_PB;
BO_TX_BU_ 1586 : APA_PB,SBSA_PB;
BO_TX_BU_ 1020 : ECM_PB,CGM_PB;
BO_TX_BU_ 1225 : TCM_PB,Router_PB,ECM_PB,CGM_PB;

BA_DEF_ BO_  "DiagConnection" INT 0 100;
BA_DEF_ BU_  "ECU_Id" HEX 0 255;
BA_DEF_ BU_  "ILUsed" ENUM  "No","Yes";
BA_DEF_ BU_  "SourceId" HEX 0 255;
BA_DEF_  "NmType" STRING ;
BA_DEF_  "DBName" STRING ;
BA_DEF_  "Baudrate" INT 0 1000000;
BA_DEF_  "BusOffRecoveryTime" INT 0 65535;
BA_DEF_  "Manufacturer" STRING ;
BA_DEF_  "VersionNumber" INT 0 65535;
BA_DEF_  "SamplePointMin" FLOAT 0 100;
BA_DEF_  "SamplePointMax" FLOAT 0 100;
BA_DEF_  "SyncJumpWidthMin" INT 0 255;
BA_DEF_  "SyncJumpWidthMax" INT 0 255;
BA_DEF_  "BusType" STRING ;
BA_DEF_ BO_  "GenMsgILSupport" ENUM  "No","Yes";
BA_DEF_ BO_  "GenMsgCycleTime" INT 0 100000;
BA_DEF_ BO_  "GenMsgDelayTime" INT 0 100000;
BA_DEF_ BO_  "DiagRequest" ENUM  "No","Yes";
BA_DEF_ BO_  "DiagResponse" ENUM  "No","Yes";
BA_DEF_ BO_  "DiagState" ENUM  "No","Yes";
BA_DEF_ BO_  "MessageSubnet" ENUM  "BB","PB","CB","Body","HS","Powertrain","Chassis","Spare","PE","CC";
BA_DEF_ BO_  "TpTxIndex" INT 0 99;
BA_DEF_ BO_  "GenMsgStartDelayTime" INT 0 100000;
BA_DEF_ SG_  "GenSigStartValue" INT 0 65535;
BA_DEF_ SG_  "SignalLongName" STRING ;
BA_DEF_ SG_  "SignalType" STRING ;
BA_DEF_ SG_  "GenSigDeltaValue" INT 0 65535;
BA_DEF_ SG_  "GenSigSendOnInit" ENUM  "Not Initialized","Application","Handler";
BA_DEF_ BU_  "NmAsrNode" ENUM  "No","Yes";
BA_DEF_ BU_  "NmAsrNodeIdentifier" HEX 0 255;
BA_DEF_ BU_  "NmAsrCanMsgCycleOffset" INT 0 65535;
BA_DEF_ BU_  "NmAsrCanMsgReducedTime" INT 0 65535;
BA_DEF_  "NmAsrMessageCount" INT 0 256;
BA_DEF_  "NmAsrBaseAddress" HEX 0 2032;
BA_DEF_  "NmAsrTimeoutTime" INT 0 65535;
BA_DEF_  "NmAsrWaitBusSleepTime" INT 0 65535;
BA_DEF_  "NmAsrRepeatMessageTime" INT 0 65525;
BA_DEF_  "NmAsrCanMsgCycleTime" INT 0 65535;
BA_DEF_ BO_  "GenMsgSendType" ENUM  "Cyclic","NotUsed","NotUsed","NotUsed","NotUsed","NotUsed","NotUsed","NotUsed","NoMsgSendType";
BA_DEF_ BO_  "NmAsrMessage" ENUM  "No","Yes";
BA_DEF_ BO_  "DiagUUDTResponse" ENUM  "No","Yes";
BA_DEF_ SG_  "GenSigSendType" ENUM  "NotUsed","OnWrite","OnWriteWithRepetition","OnChange","OnChangeWithRepetition","IfActive","IfActiveWithRepeition","NoSigSendType";
BA_DEF_ BO_  "SystemMessageLongSymbol" STRING ;
BA_DEF_REL_ BU_SG_REL_  "GenSigTimeoutMsg" HEX 0 2032;
BA_DEF_REL_ BU_SG_REL_  "GenSigTimeoutTime" INT 0 15000;
BA_DEF_REL_ BU_SG_REL_  "GenSigSuprvResp" ENUM  "None","Notify App","Substitute Default";
BA_DEF_REL_ BU_SG_REL_  "GenSigSuprvRespSubValue" INT 0 65535;
BA_DEF_REL_ BU_SG_REL_  "GenSigVBitResp" ENUM  "No","Yes";
BA_DEF_REL_ BU_SG_REL_  "GenSigVBitRespComment" STRING ;
BA_DEF_REL_ BU_SG_REL_  "GenSigVDAFailResp" ENUM  "No","Yes";
BA_DEF_REL_ BU_SG_REL_  "GenSigRxStartValue" STRING ;
BA_DEF_REL_ BU_SG_REL_  "GenSigVDAFailComment" STRING ;
BA_DEF_DEF_  "DiagConnection" 0;
BA_DEF_DEF_  "ECU_Id" 0;
BA_DEF_DEF_  "ILUsed" "Yes";
BA_DEF_DEF_  "SourceId" 0;
BA_DEF_DEF_  "NmType" "HSCAN";
BA_DEF_DEF_  "DBName" "";
BA_DEF_DEF_  "Baudrate" 500000;
BA_DEF_DEF_  "BusOffRecoveryTime" 160;
BA_DEF_DEF_  "Manufacturer" "GM";
BA_DEF_DEF_  "VersionNumber" 0;
BA_DEF_DEF_  "SamplePointMin" 81.25;
BA_DEF_DEF_  "SamplePointMax" 80;
BA_DEF_DEF_  "SyncJumpWidthMin" 4;
BA_DEF_DEF_  "SyncJumpWidthMax" 3;
BA_DEF_DEF_  "BusType" "CAN";
BA_DEF_DEF_  "GenMsgILSupport" "Yes";
BA_DEF_DEF_  "GenMsgCycleTime" 0;
BA_DEF_DEF_  "GenMsgDelayTime" 0;
BA_DEF_DEF_  "DiagRequest" "No";
BA_DEF_DEF_  "DiagResponse" "No";
BA_DEF_DEF_  "DiagState" "No";
BA_DEF_DEF_  "MessageSubnet" "Body";
BA_DEF_DEF_  "TpTxIndex" 0;
BA_DEF_DEF_  "GenMsgStartDelayTime" 0;
BA_DEF_DEF_  "GenSigStartValue" 0;
BA_DEF_DEF_  "SignalLongName" "";
BA_DEF_DEF_  "SignalType" "";
BA_DEF_DEF_  "GenSigDeltaValue" 0;
BA_DEF_DEF_  "GenSigSendOnInit" "Not Initialized";
BA_DEF_DEF_  "NmAsrNode" "Yes";
BA_DEF_DEF_  "NmAsrNodeIdentifier" 0;
BA_DEF_DEF_  "NmAsrCanMsgCycleOffset" 0;
BA_DEF_DEF_  "NmAsrCanMsgReducedTime" 0;
BA_DEF_DEF_  "NmAsrMessageCount" 22;
BA_DEF_DEF_  "NmAsrBaseAddress" 0;
BA_DEF_DEF_  "NmAsrTimeoutTime" 0;
BA_DEF_DEF_  "NmAsrWaitBusSleepTime" 0;
BA_DEF_DEF_  "NmAsrRepeatMessageTime" 0;
BA_DEF_DEF_  "NmAsrCanMsgCycleTime" 0;
BA_DEF_DEF_  "GenMsgSendType" "NoMsgSendType";
BA_DEF_DEF_  "NmAsrMessage" "No";
BA_DEF_DEF_  "DiagUUDTResponse" "No";
BA_DEF_DEF_  "GenSigSendType" "NoSigSendType";
BA_DEF_DEF_REL_ "GenSigTimeoutMsg" 0;
BA_DEF_DEF_REL_ "GenSigTimeoutTime" 0;
BA_DEF_DEF_REL_ "GenSigSuprvResp" "None";
BA_DEF_DEF_REL_ "GenSigSuprvRespSubValue" 0;
BA_DEF_DEF_REL_ "GenSigVBitResp" "No";
BA_DEF_DEF_REL_ "GenSigVBitRespComment" "";
BA_DEF_DEF_REL_ "GenSigVDAFailResp" "No";
BA_DEF_DEF_REL_ "GenSigRxStartValue" "";
BA_DEF_DEF_REL_ "GenSigVDAFailComment" "";
BA_DEF_DEF_  "SystemMessageLongSymbol" "";
BA_ "NmType" "NmAsr";
BA_ "NmAsrMessageCount" 128;
BA_ "NmAsrBaseAddress" 1568;
BA_ "NmAsrTimeoutTime" 4000;
BA_ "NmAsrWaitBusSleepTime" 4000;
BA_ "NmAsrRepeatMessageTime" 1500;
BA_ "NmAsrCanMsgCycleTime" 640;
BA_ "Manufacturer" "Vector";
BA_ "VersionNumber" 1;
BA_ "SamplePointMin" 78.5;
BA_ "SamplePointMax" 83.4;
BA_ "SyncJumpWidthMin" 3;
BA_ "SyncJumpWidthMax" 4;
BA_ "DBName" "PB";
BA_ "ECU_Id" BU_ BCM_PB 64;
BA_ "NmAsrNodeIdentifier" BU_ BCM_PB 64;
BA_ "NmAsrCanMsgReducedTime" BU_ BCM_PB 320;
BA_ "SourceId" BU_ BCM_PB 64;
BA_ "ECU_Id" BU_ ECM_PB 17;
BA_ "NmAsrNodeIdentifier" BU_ ECM_PB 17;
BA_ "NmAsrCanMsgCycleOffset" BU_ ECM_PB 10;
BA_ "NmAsrCanMsgReducedTime" BU_ ECM_PB 330;
BA_ "SourceId" BU_ ECM_PB 17;
BA_ "ECU_Id" BU_ TCM_PB 24;
BA_ "NmAsrNodeIdentifier" BU_ TCM_PB 24;
BA_ "NmAsrCanMsgCycleOffset" BU_ TCM_PB 20;
BA_ "NmAsrCanMsgReducedTime" BU_ TCM_PB 340;
BA_ "SourceId" BU_ TCM_PB 24;
BA_ "ECU_Id" BU_ Router_PB 70;
BA_ "NmAsrNodeIdentifier" BU_ Router_PB 70;
BA_ "NmAsrCanMsgCycleOffset" BU_ Router_PB 20;
BA_ "NmAsrCanMsgReducedTime" BU_ Router_PB 340;
BA_ "SourceId" BU_ Router_PB 70;
BA_ "ECU_Id" BU_ APA_PB 187;
BA_ "NmAsrNodeIdentifier" BU_ APA_PB 187;
BA_ "NmAsrCanMsgCycleOffset" BU_ APA_PB 30;
BA_ "NmAsrCanMsgReducedTime" BU_ APA_PB 350;
BA_ "SourceId" BU_ APA_PB 187;
BA_ "ECU_Id" BU_ SBSA_PB 187;
BA_ "NmAsrNodeIdentifier" BU_ SBSA_PB 187;
BA_ "NmAsrCanMsgCycleOffset" BU_ SBSA_PB 30;
BA_ "NmAsrCanMsgReducedTime" BU_ SBSA_PB 350;
BA_ "SourceId" BU_ SBSA_PB 187;
BA_ "ECU_Id" BU_ EBCM_PB 40;
BA_ "NmAsrNodeIdentifier" BU_ EBCM_PB 40;
BA_ "NmAsrCanMsgCycleOffset" BU_ EBCM_PB 40;
BA_ "NmAsrCanMsgReducedTime" BU_ EBCM_PB 360;
BA_ "SourceId" BU_ EBCM_PB 40;
BA_ "ECU_Id" BU_ IPC_PB 96;
BA_ "NmAsrNodeIdentifier" BU_ IPC_PB 96;
BA_ "NmAsrCanMsgCycleOffset" BU_ IPC_PB 50;
BA_ "NmAsrCanMsgReducedTime" BU_ IPC_PB 370;
BA_ "SourceId" BU_ IPC_PB 96;
BA_ "ECU_Id" BU_ SDM_PB 88;
BA_ "NmAsrNodeIdentifier" BU_ SDM_PB 88;
BA_ "NmAsrCanMsgCycleOffset" BU_ SDM_PB 60;
BA_ "NmAsrCanMsgReducedTime" BU_ SDM_PB 380;
BA_ "SourceId" BU_ SDM_PB 88;
BA_ "ECU_Id" BU_ EPS_PB 49;
BA_ "NmAsrNodeIdentifier" BU_ EPS_PB 49;
BA_ "NmAsrCanMsgCycleOffset" BU_ EPS_PB 70;
BA_ "NmAsrCanMsgReducedTime" BU_ EPS_PB 390;
BA_ "SourceId" BU_ EPS_PB 49;
BA_ "ECU_Id" BU_ AHL_AFL_PB 114;
BA_ "NmAsrNodeIdentifier" BU_ AHL_AFL_PB 114;
BA_ "NmAsrCanMsgCycleOffset" BU_ AHL_AFL_PB 80;
BA_ "NmAsrCanMsgReducedTime" BU_ AHL_AFL_PB 400;
BA_ "SourceId" BU_ AHL_AFL_PB 114;
BA_ "ECU_Id" BU_ ECC_PB 153;
BA_ "NmAsrNodeIdentifier" BU_ ECC_PB 153;
BA_ "NmAsrCanMsgCycleOffset" BU_ ECC_PB 90;
BA_ "NmAsrCanMsgReducedTime" BU_ ECC_PB 410;
BA_ "SourceId" BU_ ECC_PB 153;
BA_ "ECU_Id" BU_ ESCL_PB 194;
BA_ "NmAsrNodeIdentifier" BU_ ESCL_PB 194;
BA_ "NmAsrCanMsgCycleOffset" BU_ ESCL_PB 100;
BA_ "NmAsrCanMsgReducedTime" BU_ ESCL_PB 420;
BA_ "SourceId" BU_ ESCL_PB 194;
BA_ "ECU_Id" BU_ Firewall_PB 225;
BA_ "NmAsrNodeIdentifier" BU_ Firewall_PB 225;
BA_ "NmAsrCanMsgCycleOffset" BU_ Firewall_PB 110;
BA_ "NmAsrCanMsgReducedTime" BU_ Firewall_PB 430;
BA_ "SourceId" BU_ Firewall_PB 225;
BA_ "ECU_Id" BU_ CGM_PB 69;
BA_ "NmAsrNodeIdentifier" BU_ CGM_PB 69;
BA_ "NmAsrCanMsgCycleOffset" BU_ CGM_PB 120;
BA_ "NmAsrCanMsgReducedTime" BU_ CGM_PB 440;
BA_ "SourceId" BU_ CGM_PB 69;
BA_ "ECU_Id" BU_ PFAF_PB 87;
BA_ "NmAsrNodeIdentifier" BU_ PFAF_PB 87;
BA_ "NmAsrCanMsgCycleOffset" BU_ PFAF_PB 130;
BA_ "NmAsrCanMsgReducedTime" BU_ PFAF_PB 450;
BA_ "SourceId" BU_ PFAF_PB 87;
BA_ "ECU_Id" BU_ IBOOST_PB 43;
BA_ "NmAsrNodeIdentifier" BU_ IBOOST_PB 43;
BA_ "NmAsrCanMsgCycleOffset" BU_ IBOOST_PB 140;
BA_ "NmAsrCanMsgReducedTime" BU_ IBOOST_PB 460;
BA_ "SourceId" BU_ IBOOST_PB 43;
BA_ "MessageSubnet" BO_ 1068 1;
BA_ "GenMsgDelayTime" BO_ 1068 100;
BA_ "MessageSubnet" BO_ 292 1;
BA_ "GenMsgCycleTime" BO_ 292 100;
BA_ "GenMsgSendType" BO_ 292 0;
BA_ "MessageSubnet" BO_ 298 1;
BA_ "GenMsgCycleTime" BO_ 298 100;
BA_ "GenMsgStartDelayTime" BO_ 298 40;
BA_ "GenMsgSendType" BO_ 298 0;
BA_ "MessageSubnet" BO_ 321 1;
BA_ "GenMsgDelayTime" BO_ 321 10;
BA_ "GenMsgCycleTime" BO_ 321 1000;
BA_ "GenMsgStartDelayTime" BO_ 321 30;
BA_ "GenMsgSendType" BO_ 321 0;
BA_ "MessageSubnet" BO_ 900 1;
BA_ "GenMsgDelayTime" BO_ 900 100;
BA_ "GenMsgCycleTime" BO_ 900 1000;
BA_ "GenMsgSendType" BO_ 900 0;
BA_ "MessageSubnet" BO_ 352 1;
BA_ "GenMsgCycleTime" BO_ 352 100;
BA_ "GenMsgSendType" BO_ 352 0;
BA_ "MessageSubnet" BO_ 1009 1;
BA_ "GenMsgCycleTime" BO_ 1009 250;
BA_ "GenMsgStartDelayTime" BO_ 1009 10;
BA_ "GenMsgSendType" BO_ 1009 0;
BA_ "MessageSubnet" BO_ 497 1;
BA_ "GenMsgDelayTime" BO_ 497 30;
BA_ "GenMsgCycleTime" BO_ 497 100;
BA_ "GenMsgStartDelayTime" BO_ 497 10;
BA_ "GenMsgSendType" BO_ 497 0;
BA_ "MessageSubnet" BO_ 1249 1;
BA_ "GenMsgCycleTime" BO_ 1249 1000;
BA_ "GenMsgStartDelayTime" BO_ 1249 60;
BA_ "GenMsgSendType" BO_ 1249 0;
BA_ "MessageSubnet" BO_ 837 1;
BA_ "GenMsgDelayTime" BO_ 837 100;
BA_ "GenMsgCycleTime" BO_ 837 1000;
BA_ "GenMsgSendType" BO_ 837 0;
BA_ "MessageSubnet" BO_ 1300 1;
BA_ "GenMsgCycleTime" BO_ 1300 1000;
BA_ "GenMsgSendType" BO_ 1300 0;
BA_ "MessageSubnet" BO_ 201 1;
BA_ "GenMsgCycleTime" BO_ 201 12;
BA_ "GenMsgSendType" BO_ 201 0;
BA_ "MessageSubnet" BO_ 290 1;
BA_ "GenMsgCycleTime" BO_ 290 100;
BA_ "GenMsgSendType" BO_ 290 0;
BA_ "MessageSubnet" BO_ 387 1;
BA_ "GenMsgDelayTime" BO_ 387 100;
BA_ "MessageSubnet" BO_ 400 1;
BA_ "GenMsgDelayTime" BO_ 400 10;
BA_ "GenMsgCycleTime" BO_ 400 1000;
BA_ "GenMsgSendType" BO_ 400 0;
BA_ "MessageSubnet" BO_ 448 1;
BA_ "GenMsgDelayTime" BO_ 448 100;
BA_ "GenMsgCycleTime" BO_ 448 1000;
BA_ "GenMsgSendType" BO_ 448 0;
BA_ "MessageSubnet" BO_ 544 1;
BA_ "GenMsgDelayTime" BO_ 544 100;
BA_ "MessageSubnet" BO_ 786 1;
BA_ "GenMsgDelayTime" BO_ 786 100;
BA_ "GenMsgCycleTime" BO_ 786 100;
BA_ "GenMsgSendType" BO_ 786 0;
BA_ "MessageSubnet" BO_ 977 1;
BA_ "GenMsgCycleTime" BO_ 977 100;
BA_ "GenMsgSendType" BO_ 977 0;
BA_ "MessageSubnet" BO_ 1001 1;
BA_ "GenMsgCycleTime" BO_ 1001 100;
BA_ "GenMsgSendType" BO_ 1001 0;
BA_ "MessageSubnet" BO_ 1017 1;
BA_ "GenMsgCycleTime" BO_ 1017 250;
BA_ "GenMsgSendType" BO_ 1017 0;
BA_ "MessageSubnet" BO_ 1034 1;
BA_ "GenMsgDelayTime" BO_ 1034 100;
BA_ "GenMsgCycleTime" BO_ 1034 2500;
BA_ "GenMsgSendType" BO_ 1034 0;
BA_ "MessageSubnet" BO_ 1217 1;
BA_ "GenMsgCycleTime" BO_ 1217 500;
BA_ "GenMsgSendType" BO_ 1217 0;
BA_ "MessageSubnet" BO_ 1233 1;
BA_ "GenMsgCycleTime" BO_ 1233 500;
BA_ "GenMsgSendType" BO_ 1233 0;
BA_ "MessageSubnet" BO_ 1387 1;
BA_ "GenMsgDelayTime" BO_ 1387 20;
BA_ "MessageSubnet" BO_ 1388 1;
BA_ "GenMsgDelayTime" BO_ 1388 20;
BA_ "MessageSubnet" BO_ 1395 1;
BA_ "GenMsgDelayTime" BO_ 1395 20;
BA_ "MessageSubnet" BO_ 1396 1;
BA_ "GenMsgDelayTime" BO_ 1396 20;
BA_ "MessageSubnet" BO_ 849 1;
BA_ "GenMsgDelayTime" BO_ 849 100;
BA_ "MessageSubnet" BO_ 500 1;
BA_ "GenMsgCycleTime" BO_ 500 25;
BA_ "GenMsgSendType" BO_ 500 0;
BA_ "MessageSubnet" BO_ 1569 1;
BA_ "NmAsrMessage" BO_ 1569 1;
BA_ "GenMsgCycleTime" BO_ 1569 640;
BA_ "GenMsgSendType" BO_ 1569 0;
BA_ "MessageSubnet" BO_ 1580 1;
BA_ "NmAsrMessage" BO_ 1580 1;
BA_ "GenMsgCycleTime" BO_ 1580 640;
BA_ "GenMsgSendType" BO_ 1580 0;
BA_ "MessageSubnet" BO_ 1584 1;
BA_ "NmAsrMessage" BO_ 1584 1;
BA_ "GenMsgCycleTime" BO_ 1584 640;
BA_ "GenMsgSendType" BO_ 1584 0;
BA_ "MessageSubnet" BO_ 1586 1;
BA_ "NmAsrMessage" BO_ 1586 1;
BA_ "GenMsgCycleTime" BO_ 1586 640;
BA_ "GenMsgSendType" BO_ 1586 0;
BA_ "MessageSubnet" BO_ 1594 1;
BA_ "NmAsrMessage" BO_ 1594 1;
BA_ "GenMsgCycleTime" BO_ 1594 640;
BA_ "GenMsgSendType" BO_ 1594 0;
BA_ "MessageSubnet" BO_ 1585 1;
BA_ "NmAsrMessage" BO_ 1585 1;
BA_ "GenMsgCycleTime" BO_ 1585 640;
BA_ "GenMsgSendType" BO_ 1585 0;
BA_ "MessageSubnet" BO_ 1600 1;
BA_ "NmAsrMessage" BO_ 1600 1;
BA_ "GenMsgCycleTime" BO_ 1600 640;
BA_ "GenMsgSendType" BO_ 1600 0;
BA_ "MessageSubnet" BO_ 1595 1;
BA_ "NmAsrMessage" BO_ 1595 1;
BA_ "GenMsgCycleTime" BO_ 1595 640;
BA_ "GenMsgSendType" BO_ 1595 0;
BA_ "MessageSubnet" BO_ 1596 1;
BA_ "NmAsrMessage" BO_ 1596 1;
BA_ "GenMsgCycleTime" BO_ 1596 640;
BA_ "GenMsgSendType" BO_ 1596 0;
BA_ "MessageSubnet" BO_ 1589 1;
BA_ "NmAsrMessage" BO_ 1589 1;
BA_ "GenMsgCycleTime" BO_ 1589 640;
BA_ "GenMsgSendType" BO_ 1589 0;
BA_ "MessageSubnet" BO_ 1598 1;
BA_ "NmAsrMessage" BO_ 1598 1;
BA_ "GenMsgCycleTime" BO_ 1598 640;
BA_ "GenMsgSendType" BO_ 1598 0;
BA_ "MessageSubnet" BO_ 1572 1;
BA_ "NmAsrMessage" BO_ 1572 1;
BA_ "GenMsgCycleTime" BO_ 1572 640;
BA_ "GenMsgSendType" BO_ 1572 0;
BA_ "MessageSubnet" BO_ 1593 1;
BA_ "NmAsrMessage" BO_ 1593 1;
BA_ "GenMsgCycleTime" BO_ 1593 640;
BA_ "GenMsgSendType" BO_ 1593 0;
BA_ "MessageSubnet" BO_ 1576 1;
BA_ "NmAsrMessage" BO_ 1576 1;
BA_ "GenMsgCycleTime" BO_ 1576 640;
BA_ "GenMsgSendType" BO_ 1576 0;
BA_ "MessageSubnet" BO_ 1599 1;
BA_ "NmAsrMessage" BO_ 1599 1;
BA_ "GenMsgCycleTime" BO_ 1599 640;
BA_ "GenMsgSendType" BO_ 1599 0;
BA_ "MessageSubnet" BO_ 1020 1;
BA_ "GenMsgCycleTime" BO_ 1020 250;
BA_ "GenMsgSendType" BO_ 1020 0;
BA_ "MessageSubnet" BO_ 1225 1;
BA_ "GenMsgCycleTime" BO_ 1225 500;
BA_ "GenMsgSendType" BO_ 1225 0;
BA_ "MessageSubnet" BO_ 917 1;
BA_ "GenMsgDelayTime" BO_ 917 100;
BA_ "GenMsgCycleTime" BO_ 917 1000;
BA_ "GenMsgSendType" BO_ 917 0;
BA_ "MessageSubnet" BO_ 922 1;
BA_ "GenMsgDelayTime" BO_ 922 100;
BA_ "GenMsgCycleTime" BO_ 922 500;
BA_ "GenMsgSendType" BO_ 922 0;
BA_ "MessageSubnet" BO_ 1036 1;
BA_ "GenMsgDelayTime" BO_ 1036 100;
BA_ "MessageSubnet" BO_ 1376 1;
BA_ "GenMsgDelayTime" BO_ 1376 100;
BA_ "MessageSubnet" BO_ 1384 1;
BA_ "GenMsgDelayTime" BO_ 1384 100;
BA_ "MessageSubnet" BO_ 1419 1;
BA_ "GenMsgDelayTime" BO_ 1419 100;
BA_ "MessageSubnet" BO_ 1415 1;
BA_ "GenMsgDelayTime" BO_ 1415 10;
BA_ "SignalLongName" SG_ 1068 ACSAlarm0 "Alarm Clock Status : Alarm 0";
BA_ "SignalType" SG_ 1068 ACSAlarm0 "ENM";
BA_ "GenSigSendType" SG_ 1068 ACSAlarm0 1;
BA_ "SignalLongName" SG_ 1068 ACSAlarm1 "Alarm Clock Status : Alarm 1";
BA_ "SignalType" SG_ 1068 ACSAlarm1 "ENM";
BA_ "GenSigSendType" SG_ 1068 ACSAlarm1 1;
BA_ "SignalLongName" SG_ 1068 ACSAlarm10 "Alarm Clock Status : Alarm 10";
BA_ "SignalType" SG_ 1068 ACSAlarm10 "ENM";
BA_ "GenSigSendType" SG_ 1068 ACSAlarm10 1;
BA_ "SignalLongName" SG_ 1068 ACSAlarm11 "Alarm Clock Status : Alarm 11";
BA_ "SignalType" SG_ 1068 ACSAlarm11 "ENM";
BA_ "GenSigSendType" SG_ 1068 ACSAlarm11 1;
BA_ "SignalLongName" SG_ 1068 ACSAlarm12 "Alarm Clock Status : Alarm 12";
BA_ "SignalType" SG_ 1068 ACSAlarm12 "ENM";
BA_ "GenSigSendType" SG_ 1068 ACSAlarm12 1;
BA_ "SignalLongName" SG_ 1068 ACSAlarm13 "Alarm Clock Status : Alarm 13";
BA_ "SignalType" SG_ 1068 ACSAlarm13 "ENM";
BA_ "GenSigSendType" SG_ 1068 ACSAlarm13 1;
BA_ "SignalLongName" SG_ 1068 ACSAlarm14 "Alarm Clock Status : Alarm 14";
BA_ "SignalType" SG_ 1068 ACSAlarm14 "ENM";
BA_ "GenSigSendType" SG_ 1068 ACSAlarm14 1;
BA_ "SignalLongName" SG_ 1068 ACSAlarm15 "Alarm Clock Status : Alarm 15";
BA_ "SignalType" SG_ 1068 ACSAlarm15 "ENM";
BA_ "GenSigSendType" SG_ 1068 ACSAlarm15 1;
BA_ "SignalLongName" SG_ 1068 ACSAlarm2 "Alarm Clock Status : Alarm 2";
BA_ "SignalType" SG_ 1068 ACSAlarm2 "ENM";
BA_ "GenSigSendType" SG_ 1068 ACSAlarm2 1;
BA_ "SignalLongName" SG_ 1068 ACSAlarm3 "Alarm Clock Status : Alarm 3";
BA_ "SignalType" SG_ 1068 ACSAlarm3 "ENM";
BA_ "GenSigSendType" SG_ 1068 ACSAlarm3 1;
BA_ "SignalLongName" SG_ 1068 ACSAlarm4 "Alarm Clock Status : Alarm 4";
BA_ "SignalType" SG_ 1068 ACSAlarm4 "ENM";
BA_ "GenSigSendType" SG_ 1068 ACSAlarm4 1;
BA_ "SignalLongName" SG_ 1068 ACSAlarm5 "Alarm Clock Status : Alarm 5";
BA_ "SignalType" SG_ 1068 ACSAlarm5 "ENM";
BA_ "GenSigSendType" SG_ 1068 ACSAlarm5 1;
BA_ "SignalLongName" SG_ 1068 ACSAlarm6 "Alarm Clock Status : Alarm 6";
BA_ "SignalType" SG_ 1068 ACSAlarm6 "ENM";
BA_ "GenSigSendType" SG_ 1068 ACSAlarm6 1;
BA_ "SignalLongName" SG_ 1068 ACSAlarm7 "Alarm Clock Status : Alarm 7";
BA_ "SignalType" SG_ 1068 ACSAlarm7 "ENM";
BA_ "GenSigSendType" SG_ 1068 ACSAlarm7 1;
BA_ "SignalLongName" SG_ 1068 ACSAlarm8 "Alarm Clock Status : Alarm 8";
BA_ "SignalType" SG_ 1068 ACSAlarm8 "ENM";
BA_ "GenSigSendType" SG_ 1068 ACSAlarm8 1;
BA_ "SignalLongName" SG_ 1068 ACSAlarm9 "Alarm Clock Status : Alarm 9";
BA_ "SignalType" SG_ 1068 ACSAlarm9 "ENM";
BA_ "GenSigSendType" SG_ 1068 ACSAlarm9 1;
BA_ "SignalLongName" SG_ 292 BatSOC "Battery State of Charge";
BA_ "SignalType" SG_ 292 BatSOC "UNM";
BA_ "SignalLongName" SG_ 292 BattStOfChrgCrtyLow "Battery State of Charge Critically Low";
BA_ "SignalType" SG_ 292 BattStOfChrgCrtyLow "BLN";
BA_ "SignalLongName" SG_ 292 BatSOCV "Battery State of Charge Validity";
BA_ "SignalType" SG_ 292 BatSOCV "ENM";
BA_ "SignalLongName" SG_ 292 BatVlt "Battery Voltage";
BA_ "SignalType" SG_ 292 BatVlt "UNM";
BA_ "SignalLongName" SG_ 292 BatVltV "Battery Voltage Validity";
BA_ "SignalType" SG_ 292 BatVltV "ENM";
BA_ "SignalLongName" SG_ 292 BattVltIRq "Battery Voltage Indication Request";
BA_ "SignalType" SG_ 292 BattVltIRq "ENM";
BA_ "SignalLongName" SG_ 292 EnrgMgtLdShdRq "Energy Management Load Shedding Request";
BA_ "SignalType" SG_ 292 EnrgMgtLdShdRq "ENM";
BA_ "SignalLongName" SG_ 292 PwrMdOffBattSOC "Power Mode Off Battery State Of Charge";
BA_ "SignalType" SG_ 292 PwrMdOffBattSOC "UNM";
BA_ "SignalLongName" SG_ 292 BattCrntFltrd "Battery Current Filtered";
BA_ "SignalType" SG_ 292 BattCrntFltrd "SNM";
BA_ "SignalLongName" SG_ 292 IntlgntBattSnsFldIO "Intelligent Battery Sensor Failed Indication On";
BA_ "SignalType" SG_ 292 IntlgntBattSnsFldIO "BLN";
BA_ "SignalLongName" SG_ 292 SrvBattChrgSysIO "Service Battery Charging System Indication On";
BA_ "SignalType" SG_ 292 SrvBattChrgSysIO "BLN";
BA_ "SignalLongName" SG_ 292 BatSaverIO "Battery Saver Indication On";
BA_ "SignalType" SG_ 292 BatSaverIO "BLN";
BA_ "SignalLongName" SG_ 292 BatSvrMdSevLvl "Battery Saver Mode Severity Level";
BA_ "SignalType" SG_ 292 BatSvrMdSevLvl "UNM";
BA_ "SignalLongName" SG_ 292 BattStOfChrgLowIO "Battery State of Charge Low Indication On";
BA_ "SignalType" SG_ 292 BattStOfChrgLowIO "BLN";
BA_ "SignalLongName" SG_ 298 DDAjrSwAtv "Driver Door Ajar Switch Active";
BA_ "SignalType" SG_ 298 DDAjrSwAtv "BLN";
BA_ "SignalLongName" SG_ 298 DDAjrSwAtvM "Driver Door Ajar Switch Active Mask";
BA_ "SignalType" SG_ 298 DDAjrSwAtvM "ENM";
BA_ "SignalLongName" SG_ 298 DrId "Driver Identifier";
BA_ "SignalType" SG_ 298 DrId "ENM";
BA_ "GenSigStartValue" SG_ 298 DrId 7;
BA_ "SignalLongName" SG_ 298 PDAjrSwAtv "Passenger Door Ajar Switch Active";
BA_ "SignalType" SG_ 298 PDAjrSwAtv "BLN";
BA_ "SignalLongName" SG_ 298 RLDoorAjarSwAct "Rear Left Door Ajar Switch Active";
BA_ "SignalType" SG_ 298 RLDoorAjarSwAct "BLN";
BA_ "SignalLongName" SG_ 298 RRDoorAjarSwAct "Rear Right Door Ajar Switch Active";
BA_ "SignalType" SG_ 298 RRDoorAjarSwAct "BLN";
BA_ "SignalLongName" SG_ 298 VhSecNImmoIndRq "Vehicle Security Non Immobilizer Indication Request";
BA_ "SignalType" SG_ 298 VhSecNImmoIndRq "ENM";
BA_ "GenSigSendOnInit" SG_ 298 VhSecNImmoIndRq 1;
BA_ "SignalLongName" SG_ 298 HillDesCtrlMdSwAct "Hill Descent Control Mode Switch Active";
BA_ "SignalType" SG_ 298 HillDesCtrlMdSwAct "BLN";
BA_ "SignalLongName" SG_ 298 HillDesCtrlMdSwActV "Hill Descent Control Mode Switch Active Validity";
BA_ "SignalType" SG_ 298 HillDesCtrlMdSwActV "ENM";
BA_ "SignalLongName" SG_ 298 RrClosAjarSwAct "Rear Closure Ajar Switch Active";
BA_ "SignalType" SG_ 298 RrClosAjarSwAct "BLN";
BA_ "SignalLongName" SG_ 298 TCSysDisSwAtv "Traction Control System Disable Switch Active";
BA_ "SignalType" SG_ 298 TCSysDisSwAtv "BLN";
BA_ "SignalLongName" SG_ 298 TCSysDisSwAtvV "Traction Control System Disable Switch Active Validity";
BA_ "SignalType" SG_ 298 TCSysDisSwAtvV "ENM";
BA_ "SignalLongName" SG_ 298 VehMovState "Vehicle Movement State";
BA_ "SignalType" SG_ 298 VehMovState "ENM";
BA_ "SignalLongName" SG_ 298 WSWshSwAtv "Windshield Washer Switch Active";
BA_ "SignalType" SG_ 298 WSWshSwAtv "BLN";
BA_ "SignalLongName" SG_ 298 RrClsrSnwLdIO "Rear Closure Snow Load Indication On";
BA_ "SignalType" SG_ 298 RrClsrSnwLdIO "BLN";
BA_ "GenSigSendType" SG_ 298 RrClsrSnwLdIO 1;
BA_ "SignalLongName" SG_ 298 WSWprAct "Windshield Wiper Active";
BA_ "SignalType" SG_ 298 WSWprAct "BLN";
BA_ "SignalLongName" SG_ 298 HdSt "Hood Status";
BA_ "SignalType" SG_ 298 HdSt "ENM";
BA_ "GenSigSendType" SG_ 298 HdSt 1;
BA_ "GenSigSendOnInit" SG_ 298 HdSt 1;
BA_ "SignalLongName" SG_ 298 HdStV "Hood Status Validity";
BA_ "SignalType" SG_ 298 HdStV "ENM";
BA_ "GenSigSendType" SG_ 298 HdStV 1;
BA_ "SignalLongName" SG_ 321 AdvFrntLghtSysEnbld "Advanced Front Lighting System Enabled";
BA_ "SignalType" SG_ 321 AdvFrntLghtSysEnbld "BLN";
BA_ "GenSigSendType" SG_ 321 AdvFrntLghtSysEnbld 1;
BA_ "SignalLongName" SG_ 321 AutLghtCtrl "Auto Light Control";
BA_ "SignalType" SG_ 321 AutLghtCtrl "BLN";
BA_ "GenSigSendType" SG_ 321 AutLghtCtrl 1;
BA_ "SignalLongName" SG_ 321 BrkLtsAtv "Brake Lights Active";
BA_ "SignalType" SG_ 321 BrkLtsAtv "BLN";
BA_ "GenSigSendType" SG_ 321 BrkLtsAtv 1;
BA_ "SignalLongName" SG_ 321 DispNtSchmAtv "Display Night Scheme Active";
BA_ "SignalType" SG_ 321 DispNtSchmAtv "BLN";
BA_ "GenSigSendType" SG_ 321 DispNtSchmAtv 1;
BA_ "GenSigSendOnInit" SG_ 321 DispNtSchmAtv 1;
BA_ "SignalLongName" SG_ 321 DRLAct "Daytime Running Lamps Active";
BA_ "SignalType" SG_ 321 DRLAct "BLN";
BA_ "GenSigSendType" SG_ 321 DRLAct 1;
BA_ "SignalLongName" SG_ 321 FlToPsSwAtv "Flash To Pass Switch Active";
BA_ "SignalType" SG_ 321 FlToPsSwAtv "BLN";
BA_ "GenSigSendType" SG_ 321 FlToPsSwAtv 1;
BA_ "SignalLongName" SG_ 321 FrFogLmpsAct "Front Fog Lamps Active";
BA_ "SignalType" SG_ 321 FrFogLmpsAct "BLN";
BA_ "GenSigSendType" SG_ 321 FrFogLmpsAct 1;
BA_ "SignalLongName" SG_ 321 FrFgLtIO "Front Fog Light Indication On";
BA_ "SignalType" SG_ 321 FrFgLtIO "BLN";
BA_ "GenSigSendType" SG_ 321 FrFgLtIO 1;
BA_ "GenSigSendOnInit" SG_ 321 FrFgLtIO 1;
BA_ "SignalLongName" SG_ 321 HazSwAtv "Hazard Switch Active";
BA_ "SignalType" SG_ 321 HazSwAtv "BLN";
BA_ "GenSigSendType" SG_ 321 HazSwAtv 1;
BA_ "GenSigSendOnInit" SG_ 321 HazSwAtv 1;
BA_ "SignalLongName" SG_ 321 HdlmpBmSelectStat "Headlamp Beam Select Status";
BA_ "SignalType" SG_ 321 HdlmpBmSelectStat "ENM";
BA_ "GenSigSendType" SG_ 321 HdlmpBmSelectStat 1;
BA_ "SignalLongName" SG_ 321 HighBmAct "High Beam Active";
BA_ "SignalType" SG_ 321 HighBmAct "BLN";
BA_ "GenSigSendType" SG_ 321 HighBmAct 1;
BA_ "SignalLongName" SG_ 321 HiBmIO "High Beam Indication On";
BA_ "SignalType" SG_ 321 HiBmIO "BLN";
BA_ "GenSigSendType" SG_ 321 HiBmIO 1;
BA_ "GenSigSendOnInit" SG_ 321 HiBmIO 1;
BA_ "SignalLongName" SG_ 321 IntDimDspLvl "Interior Dimming Display Level";
BA_ "SignalType" SG_ 321 IntDimDspLvl "UNM";
BA_ "GenSigDeltaValue" SG_ 321 IntDimDspLvl 1;
BA_ "GenSigSendType" SG_ 321 IntDimDspLvl 1;
BA_ "GenSigSendOnInit" SG_ 321 IntDimDspLvl 1;
BA_ "SignalLongName" SG_ 321 IntDimLvl "Interior Dimming Level";
BA_ "SignalType" SG_ 321 IntDimLvl "UNM";
BA_ "GenSigDeltaValue" SG_ 321 IntDimLvl 1;
BA_ "GenSigSendType" SG_ 321 IntDimLvl 1;
BA_ "GenSigSendOnInit" SG_ 321 IntDimLvl 1;
BA_ "SignalLongName" SG_ 321 LftTrnLmpAtv "Left Turn Lamp Active";
BA_ "SignalType" SG_ 321 LftTrnLmpAtv "ENM";
BA_ "GenSigSendType" SG_ 321 LftTrnLmpAtv 1;
BA_ "GenSigSendOnInit" SG_ 321 LftTrnLmpAtv 1;
BA_ "SignalLongName" SG_ 321 LowBmAct "Low Beam Active";
BA_ "SignalType" SG_ 321 LowBmAct "BLN";
BA_ "GenSigSendType" SG_ 321 LowBmAct 1;
BA_ "SignalLongName" SG_ 321 MainLghtSw "Main Light Switch";
BA_ "SignalType" SG_ 321 MainLghtSw "ENM";
BA_ "GenSigSendType" SG_ 321 MainLghtSw 1;
BA_ "SignalLongName" SG_ 321 OtsdAmbtLtLvlStat "Outside Ambient Light Level Status";
BA_ "SignalType" SG_ 321 OtsdAmbtLtLvlStat "ENM";
BA_ "GenSigSendType" SG_ 321 OtsdAmbtLtLvlStat 1;
BA_ "SignalLongName" SG_ 321 OtsdAmbtLtLvlStatV "Outside Ambient Light Level Status Validity";
BA_ "SignalType" SG_ 321 OtsdAmbtLtLvlStatV "ENM";
BA_ "GenSigSendType" SG_ 321 OtsdAmbtLtLvlStatV 1;
BA_ "SignalLongName" SG_ 321 PrkLtIO "Park Light Indication On";
BA_ "SignalType" SG_ 321 PrkLtIO "BLN";
BA_ "GenSigSendType" SG_ 321 PrkLtIO 1;
BA_ "SignalLongName" SG_ 321 RrFogLmpsAct "Rear Fog Lamps Active";
BA_ "SignalType" SG_ 321 RrFogLmpsAct "BLN";
BA_ "GenSigSendType" SG_ 321 RrFogLmpsAct 1;
BA_ "SignalLongName" SG_ 321 RrFgLtIO "Rear Fog Light Indication On";
BA_ "SignalType" SG_ 321 RrFgLtIO "BLN";
BA_ "GenSigSendType" SG_ 321 RrFgLtIO 1;
BA_ "SignalLongName" SG_ 321 RtTrnLmpAtv "Right Turn Lamp Active";
BA_ "SignalType" SG_ 321 RtTrnLmpAtv "ENM";
BA_ "GenSigSendType" SG_ 321 RtTrnLmpAtv 1;
BA_ "GenSigSendOnInit" SG_ 321 RtTrnLmpAtv 1;
BA_ "SignalLongName" SG_ 321 TrnSwAct "Turn Switch Activation";
BA_ "SignalType" SG_ 321 TrnSwAct "ENM";
BA_ "GenSigSendType" SG_ 321 TrnSwAct 1;
BA_ "SignalLongName" SG_ 321 AutoLtsActIO "Automatic Lights Active Indication On";
BA_ "SignalType" SG_ 321 AutoLtsActIO "BLN";
BA_ "GenSigSendType" SG_ 321 AutoLtsActIO 1;
BA_ "SignalLongName" SG_ 321 PrkLtRightIO "Park Light Right Indication On";
BA_ "SignalType" SG_ 321 PrkLtRightIO "BLN";
BA_ "GenSigSendType" SG_ 321 PrkLtRightIO 1;
BA_ "GenSigSendOnInit" SG_ 321 PrkLtRightIO 1;
BA_ "SignalLongName" SG_ 321 PrkLtLeftIO "Park Light Left Indication On";
BA_ "SignalType" SG_ 321 PrkLtLeftIO "BLN";
BA_ "GenSigSendType" SG_ 321 PrkLtLeftIO 1;
BA_ "GenSigSendOnInit" SG_ 321 PrkLtLeftIO 1;
BA_ "SignalLongName" SG_ 321 IntDimNtPnlAtv "Interior Dimming Night Panel Active";
BA_ "SignalType" SG_ 321 IntDimNtPnlAtv "BLN";
BA_ "GenSigSendType" SG_ 321 IntDimNtPnlAtv 1;
BA_ "SignalLongName" SG_ 321 AutoLtsInactIO "Automatic Lights Inactive Indication On";
BA_ "SignalType" SG_ 321 AutoLtsInactIO "BLN";
BA_ "GenSigSendType" SG_ 321 AutoLtsInactIO 1;
BA_ "SignalLongName" SG_ 321 AutoBmSlctAllwd "Automatic Beam Select Allowed";
BA_ "SignalType" SG_ 321 AutoBmSlctAllwd "BLN";
BA_ "GenSigSendType" SG_ 321 AutoBmSlctAllwd 1;
BA_ "GenSigSendOnInit" SG_ 321 AutoBmSlctAllwd 1;
BA_ "SignalLongName" SG_ 321 HiBmReqd "High Beam Requested";
BA_ "SignalType" SG_ 321 HiBmReqd "BLN";
BA_ "GenSigSendType" SG_ 321 HiBmReqd 1;
BA_ "SignalLongName" SG_ 321 RevLmpAtv "Reversing Lamp";
BA_ "SignalType" SG_ 321 RevLmpAtv "BLN";
BA_ "GenSigSendType" SG_ 321 RevLmpAtv 1;
BA_ "GenSigSendOnInit" SG_ 321 RevLmpAtv 1;
BA_ "SignalLongName" SG_ 900 HmdtySnsrGlssTemp "Humidity Sensor Glass Temperature";
BA_ "SignalType" SG_ 900 HmdtySnsrGlssTemp "UNM";
BA_ "GenSigDeltaValue" SG_ 900 HmdtySnsrGlssTemp 1;
BA_ "GenSigSendType" SG_ 900 HmdtySnsrGlssTemp 1;
BA_ "SignalLongName" SG_ 900 HmdtySnsrRltvHmdty "Humidity Sensor Relative Humidity";
BA_ "SignalType" SG_ 900 HmdtySnsrRltvHmdty "UNM";
BA_ "GenSigDeltaValue" SG_ 900 HmdtySnsrRltvHmdty 1;
BA_ "GenSigSendType" SG_ 900 HmdtySnsrRltvHmdty 1;
BA_ "SignalLongName" SG_ 900 HmdtySnsrTemp "Humidity Sensor Temperature";
BA_ "SignalType" SG_ 900 HmdtySnsrTemp "UNM";
BA_ "GenSigDeltaValue" SG_ 900 HmdtySnsrTemp 1;
BA_ "GenSigSendType" SG_ 900 HmdtySnsrTemp 1;
BA_ "SignalLongName" SG_ 352 ImoId "Immobilizer Identifier";
BA_ "SignalType" SG_ 352 ImoId "UNM";
BA_ "GenSigSendOnInit" SG_ 352 ImoId 1;
BA_ "SignalLongName" SG_ 352 ImoIdSt "Immobilizer Identifier Status";
BA_ "SignalType" SG_ 352 ImoIdSt "ENM";
BA_ "GenSigSendOnInit" SG_ 352 ImoIdSt 1;
BA_ "SignalLongName" SG_ 352 LrnEnvId "Learn Environment Identification";
BA_ "SignalType" SG_ 352 LrnEnvId "UNM";
BA_ "GenSigSendOnInit" SG_ 352 LrnEnvId 1;
BA_ "SignalLongName" SG_ 352 LrnEnvIdSt "Learn Environment Identification Status";
BA_ "SignalType" SG_ 352 LrnEnvIdSt "ENM";
BA_ "GenSigSendOnInit" SG_ 352 LrnEnvIdSt 1;
BA_ "SignalLongName" SG_ 352 AVHSwtchStats "Auto Vehicle Hold Switch Status";
BA_ "SignalType" SG_ 352 AVHSwtchStats "ENM";
BA_ "SignalLongName" SG_ 1009 ACCmEngRunReq "Air Conditioning Compressor Engine Run Request";
BA_ "SignalType" SG_ 1009 ACCmEngRunReq "ENM";
BA_ "SignalLongName" SG_ 1009 ClmtCtrlHtrEngRunRq "Climate Control Heater Engine Run Request";
BA_ "SignalType" SG_ 1009 ClmtCtrlHtrEngRunRq "ENM";
BA_ "SignalLongName" SG_ 1009 EngOffTmExtRng "Engine Off Time Extended Range";
BA_ "SignalType" SG_ 1009 EngOffTmExtRng "UNM";
BA_ "SignalLongName" SG_ 1009 EngOffTmExtRngV "Engine Off Time Extended Range Validity";
BA_ "SignalType" SG_ 1009 EngOffTmExtRngV "ENM";
BA_ "SignalLongName" SG_ 1009 GenRgSPDtyCycRq "Generator Regulator Setpoint Duty Cycle Request";
BA_ "SignalType" SG_ 1009 GenRgSPDtyCycRq "UNM";
BA_ "SignalLongName" SG_ 1009 PF_MinIdlBstLvlReq "Platform Minimum Idle Boost Level Request";
BA_ "SignalType" SG_ 1009 PF_MinIdlBstLvlReq "ENM";
BA_ "SignalLongName" SG_ 1009 VehTopSpdLmtReq "Vehicle Top Speed Limit Request";
BA_ "SignalType" SG_ 1009 VehTopSpdLmtReq "UNM";
BA_ "SignalLongName" SG_ 1009 RstrctdPTOpModeReqd "Restricted Powertrain Operation Mode Requested";
BA_ "SignalType" SG_ 1009 RstrctdPTOpModeReqd "BLN";
BA_ "SignalLongName" SG_ 497 ImmblzrPreRelPswrd "Immobilizer Pre Release Password";
BA_ "SignalType" SG_ 497 ImmblzrPreRelPswrd "UNM";
BA_ "GenSigDeltaValue" SG_ 497 ImmblzrPreRelPswrd 1;
BA_ "GenSigSendType" SG_ 497 ImmblzrPreRelPswrd 1;
BA_ "SignalLongName" SG_ 497 ImmblzrPreRelPswdStat "Immobilizer Pre Release Password Status";
BA_ "SignalType" SG_ 497 ImmblzrPreRelPswdStat "ENM";
BA_ "GenSigSendType" SG_ 497 ImmblzrPreRelPswdStat 1;
BA_ "SignalLongName" SG_ 497 PrkBrkSwAtv "Park Brake Switch Active";
BA_ "SignalType" SG_ 497 PrkBrkSwAtv "BLN";
BA_ "GenSigSendType" SG_ 497 PrkBrkSwAtv 1;
BA_ "SignalLongName" SG_ 497 PMMAccTrmSt "Power Mode Master Accessory Terminal Status";
BA_ "SignalType" SG_ 497 PMMAccTrmSt "ENM";
BA_ "GenSigSendType" SG_ 497 PMMAccTrmSt 1;
BA_ "SignalLongName" SG_ 497 PMMRunCrkTrmSt "Power Mode Master Run Crank Terminal Status";
BA_ "SignalType" SG_ 497 PMMRunCrkTrmSt "ENM";
BA_ "GenSigSendType" SG_ 497 PMMRunCrkTrmSt 1;
BA_ "SignalLongName" SG_ 497 RemStrtSt "Remote Start Status";
BA_ "SignalType" SG_ 497 RemStrtSt "ENM";
BA_ "GenSigSendType" SG_ 497 RemStrtSt 1;
BA_ "GenSigSendOnInit" SG_ 497 RemStrtSt 1;
BA_ "SignalLongName" SG_ 497 RmVehStrRq "Remote Vehicle Start Request";
BA_ "SignalType" SG_ 497 RmVehStrRq "ENM";
BA_ "GenSigSendType" SG_ 497 RmVehStrRq 1;
BA_ "SignalLongName" SG_ 497 SysPwrMd "System Power Mode";
BA_ "SignalType" SG_ 497 SysPwrMd "ENM";
BA_ "GenSigSendType" SG_ 497 SysPwrMd 1;
BA_ "SignalLongName" SG_ 497 SysPwrMdV "System Power Mode Validity";
BA_ "SignalType" SG_ 497 SysPwrMdV "ENM";
BA_ "GenSigSendType" SG_ 497 SysPwrMdV 1;
BA_ "GenSigSendOnInit" SG_ 497 SysPwrMdV 1;
BA_ "SignalLongName" SG_ 497 TrStLgMdAtv "Transport Storage Logistic Mode Active";
BA_ "SignalType" SG_ 497 TrStLgMdAtv "BLN";
BA_ "GenSigSendType" SG_ 497 TrStLgMdAtv 1;
BA_ "SignalLongName" SG_ 497 ThrtlPrgrsnReq "Throttle Progression Request";
BA_ "SignalType" SG_ 497 ThrtlPrgrsnReq "ENM";
BA_ "GenSigSendType" SG_ 497 ThrtlPrgrsnReq 1;
BA_ "SignalLongName" SG_ 1249 VehIdNmDig10_17 "Vehicle Identification Number Digits 10-17";
BA_ "SignalType" SG_ 1249 VehIdNmDig10_17 "ASC";
BA_ "SignalLongName" SG_ 837 RrWndDfgInhRq "Rear Window Defog Inhibit Request";
BA_ "SignalType" SG_ 837 RrWndDfgInhRq "ENM";
BA_ "GenSigSendType" SG_ 837 RrWndDfgInhRq 1;
BA_ "GenSigSendOnInit" SG_ 837 RrWndDfgInhRq 1;
BA_ "SignalLongName" SG_ 837 RrWndDfgSwAtv "Rear Window Defog Switch Active";
BA_ "SignalType" SG_ 837 RrWndDfgSwAtv "BLN";
BA_ "GenSigSendType" SG_ 837 RrWndDfgSwAtv 1;
BA_ "SignalLongName" SG_ 1300 VehIdNmDig2_9 "Vehicle Identification Number Digits 2-9";
BA_ "SignalType" SG_ 1300 VehIdNmDig2_9 "ASC";
BA_ "SignalLongName" SG_ 201 AccActPos "Accelerator Actual Position";
BA_ "SignalType" SG_ 201 AccActPos "UNM";
BA_ "SignalLongName" SG_ 201 AccActPosV "Accelerator Actual Position Validity";
BA_ "SignalType" SG_ 201 AccActPosV "ENM";
BA_ "SignalLongName" SG_ 201 CrsCntAtv "Cruise Control Active";
BA_ "SignalType" SG_ 201 CrsCntAtv "BLN";
BA_ "SignalLongName" SG_ 201 CrsCntEnbld "Cruise Control Enabled";
BA_ "SignalType" SG_ 201 CrsCntEnbld "BLN";
BA_ "SignalLongName" SG_ 201 Eng12vStrtrMtrCmmdOn "Engine 12 Volt Starter Motor Commanded On";
BA_ "SignalType" SG_ 201 Eng12vStrtrMtrCmmdOn "BLN";
BA_ "SignalLongName" SG_ 201 EngIdlAtv "Engine Idle Active";
BA_ "SignalType" SG_ 201 EngIdlAtv "BLN";
BA_ "SignalLongName" SG_ 201 EngAirIntBstPr "Engine Intake Air Boost Pressure";
BA_ "SignalType" SG_ 201 EngAirIntBstPr "SNM";
BA_ "SignalLongName" SG_ 201 EngAirIntBstPrV "Engine Intake Air Boost Pressure Validity";
BA_ "SignalType" SG_ 201 EngAirIntBstPrV "ENM";
BA_ "SignalLongName" SG_ 201 EngRunAtv "Engine Run Active";
BA_ "SignalType" SG_ 201 EngRunAtv "BLN";
BA_ "SignalLongName" SG_ 201 EngSpd "Engine Speed";
BA_ "SignalType" SG_ 201 EngSpd "UNM";
BA_ "SignalLongName" SG_ 201 EngSpdStat "Engine Speed Status";
BA_ "SignalType" SG_ 201 EngSpdStat "ENM";
BA_ "SignalLongName" SG_ 201 PT_BrkPedDscrtInpStat "Powertrain Brake Pedal Discrete Input Status";
BA_ "SignalType" SG_ 201 PT_BrkPedDscrtInpStat "ENM";
BA_ "SignalLongName" SG_ 201 PT_BrkPedDscrtInpStatV "Powertrain Brake Pedal Discrete Input Status Validity";
BA_ "SignalType" SG_ 201 PT_BrkPedDscrtInpStatV "ENM";
BA_ "SignalLongName" SG_ 201 PTCrnkAbrted "Powertrain Crank Aborted";
BA_ "SignalType" SG_ 201 PTCrnkAbrted "BLN";
BA_ "SignalLongName" SG_ 201 PT_CrnkAct "Powertrain Crank Active";
BA_ "SignalType" SG_ 201 PT_CrnkAct "BLN";
BA_ "SignalLongName" SG_ 201 PTRunAbrt "Powertrain Run Aborted";
BA_ "SignalType" SG_ 201 PTRunAbrt "BLN";
BA_ "SignalLongName" SG_ 201 RmVhStrtEngRng "Remote Vehicle Start Engine Running";
BA_ "SignalType" SG_ 201 RmVhStrtEngRng "BLN";
BA_ "SignalLongName" SG_ 201 SpdLmtrSpdWrngEnbld "Speed Limiter/Speed Warning Enabled";
BA_ "SignalType" SG_ 201 SpdLmtrSpdWrngEnbld "BLN";
BA_ "SignalLongName" SG_ 201 EngCntrlRunCrnkTrmSt "Engine Controller Run Crank Terminal Status";
BA_ "SignalType" SG_ 201 EngCntrlRunCrnkTrmSt "ENM";
BA_ "SignalLongName" SG_ 290 SysBkUpPwrMd "System Backup Power Mode";
BA_ "SignalType" SG_ 290 SysBkUpPwrMd "ENM";
BA_ "GenSigSendType" SG_ 290 SysBkUpPwrMd 1;
BA_ "GenSigSendOnInit" SG_ 290 SysBkUpPwrMd 1;
BA_ "SignalLongName" SG_ 290 SysBkupPwrMdEn "System Backup Power Mode Enabled";
BA_ "SignalType" SG_ 290 SysBkupPwrMdEn "BLN";
BA_ "GenSigSendType" SG_ 290 SysBkupPwrMdEn 1;
BA_ "GenSigSendOnInit" SG_ 290 SysBkupPwrMdEn 1;
BA_ "SignalLongName" SG_ 290 SysBkUpPwrMdV "System Backup Power Mode Validity";
BA_ "SignalType" SG_ 290 SysBkUpPwrMdV "ENM";
BA_ "GenSigSendType" SG_ 290 SysBkUpPwrMdV 1;
BA_ "SignalLongName" SG_ 290 BkUpPwrMdRnCrnkOutSt "Backup Power Mode RUN Crank Output State";
BA_ "SignalType" SG_ 290 BkUpPwrMdRnCrnkOutSt "ENM";
BA_ "GenSigSendType" SG_ 290 BkUpPwrMdRnCrnkOutSt 1;
BA_ "SignalLongName" SG_ 290 ElecPwrStrSlctdMd "Electrical Power Steering Selected Mode";
BA_ "SignalType" SG_ 290 ElecPwrStrSlctdMd "ENM";
BA_ "SignalLongName" SG_ 387 EnvIdRsp2 "Environment Identification Response 2";
BA_ "SignalType" SG_ 387 EnvIdRsp2 "UNM";
BA_ "GenSigDeltaValue" SG_ 387 EnvIdRsp2 1;
BA_ "GenSigSendType" SG_ 387 EnvIdRsp2 1;
BA_ "SignalLongName" SG_ 387 EnvIdRspSt2 "Environment Identification Response Status 2";
BA_ "SignalType" SG_ 387 EnvIdRspSt2 "ENM";
BA_ "GenSigSendType" SG_ 387 EnvIdRspSt2 1;
BA_ "SignalLongName" SG_ 400 SIRDpl "Airbag Deployed";
BA_ "SignalType" SG_ 400 SIRDpl "BLN";
BA_ "GenSigSendType" SG_ 400 SIRDpl 1;
BA_ "GenSigSendOnInit" SG_ 400 SIRDpl 1;
BA_ "SignalLongName" SG_ 400 NotDrvSeatStat "Notification Driver Seatbelt Status";
BA_ "SignalType" SG_ 400 NotDrvSeatStat "ENM";
BA_ "GenSigSendType" SG_ 400 NotDrvSeatStat 1;
BA_ "SignalLongName" SG_ 400 NotiEventCount "Notification Event Counter";
BA_ "SignalType" SG_ 400 NotiEventCount "UNM";
BA_ "GenSigDeltaValue" SG_ 400 NotiEventCount 1;
BA_ "GenSigSendType" SG_ 400 NotiEventCount 1;
BA_ "SignalLongName" SG_ 400 NEDLSDrFrSt1De "Notification Event Deployed Loop Status : Driver Front Stage 1 Deployed";
BA_ "SignalType" SG_ 400 NEDLSDrFrSt1De "BLN";
BA_ "GenSigSendType" SG_ 400 NEDLSDrFrSt1De 1;
BA_ "SignalLongName" SG_ 400 NEDLSDrFrSt2De "Notification Event Deployed Loop Status : Driver Front Stage 2 Deployed";
BA_ "SignalType" SG_ 400 NEDLSDrFrSt2De "BLN";
BA_ "GenSigSendType" SG_ 400 NEDLSDrFrSt2De 1;
BA_ "SignalLongName" SG_ 400 NEDLSLtSdArbgDld "Notification Event Deployed Loop Status : Left Side Airbag Deployed";
BA_ "SignalType" SG_ 400 NEDLSLtSdArbgDld "BLN";
BA_ "GenSigSendType" SG_ 400 NEDLSLtSdArbgDld 1;
BA_ "SignalLongName" SG_ 400 NEDLSPaFrSt1De "Notification Event Deployed Loop Status : Passenger Front Stage 1 Deployed";
BA_ "SignalType" SG_ 400 NEDLSPaFrSt1De "BLN";
BA_ "GenSigSendType" SG_ 400 NEDLSPaFrSt1De 1;
BA_ "SignalLongName" SG_ 400 NEDLSPaFrSt2De "Notification Event Deployed Loop Status : Passenger Front Stage 2 Deployed";
BA_ "SignalType" SG_ 400 NEDLSPaFrSt2De "BLN";
BA_ "GenSigSendType" SG_ 400 NEDLSPaFrSt2De 1;
BA_ "SignalLongName" SG_ 400 NEDLSRtSdArbgDld "Notification Event Deployed Loop Status : Right Side Airbag Deployed";
BA_ "SignalType" SG_ 400 NEDLSRtSdArbgDld "BLN";
BA_ "GenSigSendType" SG_ 400 NEDLSRtSdArbgDld 1;
BA_ "SignalLongName" SG_ 400 NEDLSSdCrtnArbgDpld "Notification Event Deployed Loop Status : Side Curtain Airbag Deployed";
BA_ "SignalType" SG_ 400 NEDLSSdCrtnArbgDpld "BLN";
BA_ "GenSigSendType" SG_ 400 NEDLSSdCrtnArbgDpld 1;
BA_ "SignalLongName" SG_ 400 NESSFrImpPreSevSt "Notification Event Severity Status : Frontal Impact Pretensioner Severity Achieved";
BA_ "SignalType" SG_ 400 NESSFrImpPreSevSt "BLN";
BA_ "GenSigSendType" SG_ 400 NESSFrImpPreSevSt 1;
BA_ "SignalLongName" SG_ 400 NESSFrImpSt1SevSt "Notification Event Severity Status : Frontal Impact Stage 1 Severity Achieved";
BA_ "SignalType" SG_ 400 NESSFrImpSt1SevSt "BLN";
BA_ "GenSigSendType" SG_ 400 NESSFrImpSt1SevSt 1;
BA_ "SignalLongName" SG_ 400 NESSFrImpSt2SevSt "Notification Event Severity Status : Frontal Impact Stage 2 Severity Achieved";
BA_ "SignalType" SG_ 400 NESSFrImpSt2SevSt "BLN";
BA_ "GenSigSendType" SG_ 400 NESSFrImpSt2SevSt 1;
BA_ "SignalLongName" SG_ 400 NESSLeSiSevSt "Notification Event Severity Status : Left Side Severity Achieved";
BA_ "SignalType" SG_ 400 NESSLeSiSevSt "BLN";
BA_ "GenSigSendType" SG_ 400 NESSLeSiSevSt 1;
BA_ "SignalLongName" SG_ 400 NESSReImpSevSt "Notification Event Severity Status : Rear Impact Severity Achieved";
BA_ "SignalType" SG_ 400 NESSReImpSevSt "BLN";
BA_ "GenSigSendType" SG_ 400 NESSReImpSevSt 1;
BA_ "SignalLongName" SG_ 400 NESSRiSiSevSt "Notification Event Severity Status : Right Side Severity Achieved";
BA_ "SignalType" SG_ 400 NESSRiSiSevSt "BLN";
BA_ "GenSigSendType" SG_ 400 NESSRiSiSevSt 1;
BA_ "SignalLongName" SG_ 400 NESSRoSevSt "Notification Event Severity Status : Rollover Severity Achieved";
BA_ "SignalType" SG_ 400 NESSRoSevSt "BLN";
BA_ "GenSigSendType" SG_ 400 NESSRoSevSt 1;
BA_ "SignalLongName" SG_ 400 NotEventStat "Notification Event Status";
BA_ "SignalType" SG_ 400 NotEventStat "ENM";
BA_ "GenSigSendType" SG_ 400 NotEventStat 1;
BA_ "SignalLongName" SG_ 400 NotiFrntPasSeatOccSta "Notification Front Passenger Seat Occupancy Status";
BA_ "SignalType" SG_ 400 NotiFrntPasSeatOccSta "ENM";
BA_ "GenSigSendType" SG_ 400 NotiFrntPasSeatOccSta 1;
BA_ "SignalLongName" SG_ 400 NotPsSeatStat "Notification Passenger Seatbelt Status";
BA_ "SignalType" SG_ 400 NotPsSeatStat "ENM";
BA_ "GenSigSendType" SG_ 400 NotPsSeatStat 1;
BA_ "SignalLongName" SG_ 400 NotSecRowCtSeaOccStat "Notification Second Row Center Seat Occupancy Status";
BA_ "SignalType" SG_ 400 NotSecRowCtSeaOccStat "ENM";
BA_ "GenSigSendType" SG_ 400 NotSecRowCtSeaOccStat 1;
BA_ "SignalLongName" SG_ 400 NotSecRowLeSeaOccStat "Notification Second Row Left Seat Occupancy Status";
BA_ "SignalType" SG_ 400 NotSecRowLeSeaOccStat "ENM";
BA_ "GenSigSendType" SG_ 400 NotSecRowLeSeaOccStat 1;
BA_ "SignalLongName" SG_ 400 NotSndRwLtSeatStat "Notification Second Row Left Seatbelt Status";
BA_ "SignalType" SG_ 400 NotSndRwLtSeatStat "ENM";
BA_ "GenSigSendType" SG_ 400 NotSndRwLtSeatStat 1;
BA_ "SignalLongName" SG_ 400 NotSndRwMdlSeatStat "Notification Second Row Middle Seatbelt Status";
BA_ "SignalType" SG_ 400 NotSndRwMdlSeatStat "ENM";
BA_ "GenSigSendType" SG_ 400 NotSndRwMdlSeatStat 1;
BA_ "SignalLongName" SG_ 400 NotSecRowRtSeaOccStat "Notification Second Row Right Seat Occupancy Status";
BA_ "SignalType" SG_ 400 NotSecRowRtSeaOccStat "ENM";
BA_ "GenSigSendType" SG_ 400 NotSecRowRtSeaOccStat 1;
BA_ "SignalLongName" SG_ 400 NotSndRwRtSeatStat "Notification Second Row Right Seatbelt Status";
BA_ "SignalType" SG_ 400 NotSndRwRtSeatStat "ENM";
BA_ "GenSigSendType" SG_ 400 NotSndRwRtSeatStat 1;
BA_ "SignalLongName" SG_ 448 RrWndDfgOn "Rear Window Defog On";
BA_ "SignalType" SG_ 448 RrWndDfgOn "BLN";
BA_ "GenSigSendType" SG_ 448 RrWndDfgOn 1;
BA_ "GenSigSendOnInit" SG_ 448 RrWndDfgOn 1;
BA_ "SignalLongName" SG_ 544 A2ERRAlrmReq "Alarm 2 Extended Range Request : Alarm Request";
BA_ "SignalType" SG_ 544 A2ERRAlrmReq "ENM";
BA_ "GenSigSendType" SG_ 544 A2ERRAlrmReq 1;
BA_ "SignalLongName" SG_ 544 A2ERRAlrmTime "Alarm 2 Extended Range Request : Alarm Time";
BA_ "SignalType" SG_ 544 A2ERRAlrmTime "UNM";
BA_ "GenSigDeltaValue" SG_ 544 A2ERRAlrmTime 1;
BA_ "GenSigSendType" SG_ 544 A2ERRAlrmTime 1;
BA_ "SignalLongName" SG_ 544 EstBulkIntAirTmp "Estimated Bulk Interior Air Temperature";
BA_ "SignalType" SG_ 544 EstBulkIntAirTmp "UNM";
BA_ "GenSigDeltaValue" SG_ 544 EstBulkIntAirTmp 1;
BA_ "GenSigSendType" SG_ 544 EstBulkIntAirTmp 1;
BA_ "SignalLongName" SG_ 544 EstBulkIntAirTmpV "Estimated Bulk Interior Air Temperature Validity";
BA_ "SignalType" SG_ 544 EstBulkIntAirTmpV "ENM";
BA_ "GenSigSendType" SG_ 544 EstBulkIntAirTmpV 1;
BA_ "SignalLongName" SG_ 544 EstIntRfSrfcTmp "Estimated Interior Roof Surface Temperature";
BA_ "SignalType" SG_ 544 EstIntRfSrfcTmp "UNM";
BA_ "GenSigDeltaValue" SG_ 544 EstIntRfSrfcTmp 1;
BA_ "GenSigSendType" SG_ 544 EstIntRfSrfcTmp 1;
BA_ "SignalLongName" SG_ 544 EstIntRfSrfcTmpV "Estimated Interior Roof Surface Temperature Validity";
BA_ "SignalType" SG_ 544 EstIntRfSrfcTmpV "ENM";
BA_ "GenSigSendType" SG_ 544 EstIntRfSrfcTmpV 1;
BA_ "SignalLongName" SG_ 786 ClntHtrElecPwrRatV "Coolant Heater Electrical Power Rationalized Validity";
BA_ "SignalType" SG_ 786 ClntHtrElecPwrRatV "ENM";
BA_ "GenSigSendType" SG_ 786 ClntHtrElecPwrRatV 1;
BA_ "SignalLongName" SG_ 786 HtrVlvRqstdPstn "Heater Valve Requested Position";
BA_ "SignalType" SG_ 786 HtrVlvRqstdPstn "ENM";
BA_ "GenSigSendType" SG_ 786 HtrVlvRqstdPstn 1;
BA_ "SignalLongName" SG_ 786 ClmtCtrlHtrEngRunRq "Climate Control Heater Engine Run Request";
BA_ "SignalType" SG_ 786 ClmtCtrlHtrEngRunRq "ENM";
BA_ "GenSigSendType" SG_ 786 ClmtCtrlHtrEngRunRq 1;
BA_ "SignalLongName" SG_ 786 ClimCtrlVoltBstModReq "Climate Control Voltage Boost Mode Requested";
BA_ "SignalType" SG_ 786 ClimCtrlVoltBstModReq "BLN";
BA_ "GenSigSendType" SG_ 786 ClimCtrlVoltBstModReq 1;
BA_ "GenSigSendOnInit" SG_ 786 ClimCtrlVoltBstModReq 1;
BA_ "SignalLongName" SG_ 786 ClntHtrElecPwrRat "Coolant Heater Electrical Power Rationalized";
BA_ "SignalType" SG_ 786 ClntHtrElecPwrRat "UNM";
BA_ "GenSigDeltaValue" SG_ 786 ClntHtrElecPwrRat 1;
BA_ "GenSigSendType" SG_ 786 ClntHtrElecPwrRat 1;
BA_ "SignalLongName" SG_ 786 ClmCtrHiVltPwrRqtd "Climate Control High Voltage Power Requested";
BA_ "SignalType" SG_ 786 ClmCtrHiVltPwrRqtd "UNM";
BA_ "GenSigDeltaValue" SG_ 786 ClmCtrHiVltPwrRqtd 1;
BA_ "GenSigSendType" SG_ 786 ClmCtrHiVltPwrRqtd 1;
BA_ "GenSigSendOnInit" SG_ 786 ClmCtrHiVltPwrRqtd 1;
BA_ "SignalLongName" SG_ 977 ACCompCmnd "Air Conditioning Compressor Command";
BA_ "SignalType" SG_ 977 ACCompCmnd "ENM";
BA_ "SignalLongName" SG_ 977 ACCmpNrmLdGrdAld "Air Conditioning Compressor Normalized Load Gradient Allowed";
BA_ "SignalType" SG_ 977 ACCmpNrmLdGrdAld "UNM";
BA_ "SignalLongName" SG_ 977 CrsSpdLmtrDrvSelSpd "Cruise and Speed Limiter Driver Selected Speed";
BA_ "SignalType" SG_ 977 CrsSpdLmtrDrvSelSpd "UNM";
BA_ "SignalLongName" SG_ 977 CrsCntlDrSelSpdAct "Cruise Control Driver Selected Speed Active";
BA_ "SignalType" SG_ 977 CrsCntlDrSelSpdAct "BLN";
BA_ "SignalLongName" SG_ 977 EngBstPrsInd "Engine Boost Pressure Indication";
BA_ "SignalType" SG_ 977 EngBstPrsInd "UNM";
BA_ "SignalLongName" SG_ 977 EngBstPrsIndV "Engine Boost Pressure Indication Validity";
BA_ "SignalType" SG_ 977 EngBstPrsIndV "ENM";
BA_ "SignalLongName" SG_ 977 EngCstFlCutAct "Engine Coast Fuel Cut Off Active";
BA_ "SignalType" SG_ 977 EngCstFlCutAct "BLN";
BA_ "SignalLongName" SG_ 977 EngEmsRelMalfIndReq "Engine Emissions Related Malfunction Indication Request";
BA_ "SignalType" SG_ 977 EngEmsRelMalfIndReq "ENM";
BA_ "SignalLongName" SG_ 977 EngNEmsnsRelMalfAct "Engine Non Emissions Related Malfunction Active";
BA_ "SignalType" SG_ 977 EngNEmsnsRelMalfAct "BLN";
BA_ "SignalLongName" SG_ 977 EngOilLifRstPerf "Engine Oil Life Reset Performed";
BA_ "SignalType" SG_ 977 EngOilLifRstPerf "BLN";
BA_ "SignalLongName" SG_ 977 EngOilStrvtnIO "Engine Oil Starvation Indication On";
BA_ "SignalType" SG_ 977 EngOilStrvtnIO "BLN";
BA_ "SignalLongName" SG_ 977 FuelFltLifRstPerf "Fuel Filter Life Reset Performed";
BA_ "SignalType" SG_ 977 FuelFltLifRstPerf "BLN";
BA_ "SignalLongName" SG_ 977 InstFuelConsmpRate "Instantaneous Fuel Consumption Rate";
BA_ "SignalType" SG_ 977 InstFuelConsmpRate "UNM";
BA_ "SignalLongName" SG_ 977 SpdLmtrSpdWrngAct "Speed Limiter/Speed Warning Active";
BA_ "SignalType" SG_ 977 SpdLmtrSpdWrngAct "BLN";
BA_ "SignalLongName" SG_ 977 ThrPos "Throttle Position";
BA_ "SignalType" SG_ 977 ThrPos "UNM";
BA_ "SignalLongName" SG_ 977 ThrPosV "Throttle Position Validity";
BA_ "SignalType" SG_ 977 ThrPosV "ENM";
BA_ "SignalLongName" SG_ 977 AutoMdSpdLmtStat "Auto Mode Speed Limit Status";
BA_ "SignalType" SG_ 977 AutoMdSpdLmtStat "ENM";
BA_ "SignalLongName" SG_ 1001 DistRollCntAvgDrvn "Distance Rolling Count Average Driven";
BA_ "SignalType" SG_ 1001 DistRollCntAvgDrvn "UNM";
BA_ "SignalLongName" SG_ 1001 DstRolCntAvgDrnRstOc "Distance Rolling Count Average Driven Reset Occurred";
BA_ "SignalType" SG_ 1001 DstRolCntAvgDrnRstOc "BLN";
BA_ "SignalLongName" SG_ 1001 DistRollCntAvgDrvnSrc "Distance Rolling Count Average Driven Source";
BA_ "SignalType" SG_ 1001 DistRollCntAvgDrvnSrc "ENM";
BA_ "SignalLongName" SG_ 1001 DistRollCntAvgDrvnV "Distance Rolling Count Average Driven Validity";
BA_ "SignalType" SG_ 1001 DistRollCntAvgDrvnV "ENM";
BA_ "SignalLongName" SG_ 1001 DstRolCntAvgNonDrvn "Distance Rolling Count Average Non Driven";
BA_ "SignalType" SG_ 1001 DstRolCntAvgNonDrvn "UNM";
BA_ "SignalLongName" SG_ 1001 DstRolCntAvNDrRstOc "Distance Rolling Count Average Non Driven Reset Occurred";
BA_ "SignalType" SG_ 1001 DstRolCntAvNDrRstOc "BLN";
BA_ "SignalLongName" SG_ 1001 DstRolCntAvgNonDrvnV "Distance Rolling Count Average Non Driven Validity";
BA_ "SignalType" SG_ 1001 DstRolCntAvgNonDrvnV "ENM";
BA_ "SignalLongName" SG_ 1001 VehSpdAvgDrvn "Vehicle Speed Average Driven";
BA_ "SignalType" SG_ 1001 VehSpdAvgDrvn "UNM";
BA_ "SignalLongName" SG_ 1001 VehSpdAvgDrvnSrc "Vehicle Speed Average Driven Source";
BA_ "SignalType" SG_ 1001 VehSpdAvgDrvnSrc "ENM";
BA_ "SignalLongName" SG_ 1001 VehSpdAvgDrvnV "Vehicle Speed Average Driven Validity";
BA_ "SignalType" SG_ 1001 VehSpdAvgDrvnV "ENM";
BA_ "SignalLongName" SG_ 1001 VehSpdAvgNDrvn "Vehicle Speed Average Non Driven";
BA_ "SignalType" SG_ 1001 VehSpdAvgNDrvn "UNM";
BA_ "SignalLongName" SG_ 1001 VehSpdAvgNDrvnV "Vehicle Speed Average Non Driven Validity";
BA_ "SignalType" SG_ 1001 VehSpdAvgNDrvnV "ENM";
BA_ "SignalLongName" SG_ 1017 ACRfHiSdFldPrs "Air Conditioning Refrigerant High Side Fluid Pressure";
BA_ "SignalType" SG_ 1017 ACRfHiSdFldPrs "UNM";
BA_ "SignalLongName" SG_ 1017 ACRfHiSdFldPrsV "Air Conditioning Refrigerant High Side Fluid Pressure Validity";
BA_ "SignalType" SG_ 1017 ACRfHiSdFldPrsV "ENM";
BA_ "SignalLongName" SG_ 1017 EngCoolFanSpd "Engine Cooling Fan Speed";
BA_ "SignalType" SG_ 1017 EngCoolFanSpd "UNM";
BA_ "SignalLongName" SG_ 1017 EngOilRmnLf "Engine Oil Remaining Life";
BA_ "SignalType" SG_ 1017 EngOilRmnLf "UNM";
BA_ "SignalLongName" SG_ 1017 EngSpdLmtnMdAct "Engine Speed Limitation Mode Active";
BA_ "SignalType" SG_ 1017 EngSpdLmtnMdAct "BLN";
BA_ "SignalLongName" SG_ 1017 FlInjRlCt "Fuel Injected Rolling Count";
BA_ "SignalType" SG_ 1017 FlInjRlCt "UNM";
BA_ "SignalLongName" SG_ 1017 FlInjRlCtRstOcc "Fuel Injected Rolling Count Reset Occurred";
BA_ "SignalType" SG_ 1017 FlInjRlCtRstOcc "BLN";
BA_ "SignalLongName" SG_ 1017 GenFld "Generator Failed";
BA_ "SignalType" SG_ 1017 GenFld "BLN";
BA_ "SignalLongName" SG_ 1017 GenFldDutCyc "Generator Field Duty Cycle";
BA_ "SignalType" SG_ 1017 GenFldDutCyc "UNM";
BA_ "SignalLongName" SG_ 1017 GenFldDutCycV "Generator Field Duty Cycle Validity";
BA_ "SignalType" SG_ 1017 GenFldDutCycV "ENM";
BA_ "SignalLongName" SG_ 1017 GenStptDtCycPtOvrAct "Generator Setpoint Duty Cycle Powertrain Override Active";
BA_ "SignalType" SG_ 1017 GenStptDtCycPtOvrAct "BLN";
BA_ "SignalLongName" SG_ 1017 VehTopSpdLmtArbVal "Vehicle Top Speed Limit Arbitrated Value";
BA_ "SignalType" SG_ 1017 VehTopSpdLmtArbVal "UNM";
BA_ "SignalLongName" SG_ 1017 VehTopSpdLmtMdAct "Vehicle Top Speed Limit Mode Active";
BA_ "SignalType" SG_ 1017 VehTopSpdLmtMdAct "BLN";
BA_ "SignalLongName" SG_ 1034 AirCndActIO "Air Conditioning Active Indication On";
BA_ "SignalType" SG_ 1034 AirCndActIO "BLN";
BA_ "GenSigSendType" SG_ 1034 AirCndActIO 1;
BA_ "GenSigSendOnInit" SG_ 1034 AirCndActIO 1;
BA_ "SignalLongName" SG_ 1034 ACHtIdleBstLevReq_36A "Air Conditioning and Heating Idle Boost Level Request";
BA_ "SignalType" SG_ 1034 ACHtIdleBstLevReq_36A "ENM";
BA_ "GenSigSendType" SG_ 1034 ACHtIdleBstLevReq_36A 1;
BA_ "GenSigSendOnInit" SG_ 1034 ACHtIdleBstLevReq_36A 1;
BA_ "SignalLongName" SG_ 1034 AirCndCmptLdEst "Air Conditioning Compartment Load Estimated";
BA_ "SignalType" SG_ 1034 AirCndCmptLdEst "UNM";
BA_ "GenSigDeltaValue" SG_ 1034 AirCndCmptLdEst 1;
BA_ "GenSigSendType" SG_ 1034 AirCndCmptLdEst 1;
BA_ "GenSigSendOnInit" SG_ 1034 AirCndCmptLdEst 1;
BA_ "SignalLongName" SG_ 1034 ClmCntlExtDefActIO "Climate Control Extended Defrost Active Indication On";
BA_ "SignalType" SG_ 1034 ClmCntlExtDefActIO "BLN";
BA_ "GenSigSendType" SG_ 1034 ClmCntlExtDefActIO 1;
BA_ "GenSigSendOnInit" SG_ 1034 ClmCntlExtDefActIO 1;
BA_ "SignalLongName" SG_ 1034 ClmCntFrBlwFnSp "Climate Control Front Blower Fan Speed";
BA_ "SignalType" SG_ 1034 ClmCntFrBlwFnSp "UNM";
BA_ "GenSigDeltaValue" SG_ 1034 ClmCntFrBlwFnSp 13;
BA_ "GenSigSendType" SG_ 1034 ClmCntFrBlwFnSp 1;
BA_ "GenSigSendOnInit" SG_ 1034 ClmCntFrBlwFnSp 1;
BA_ "SignalLongName" SG_ 1034 ClntCircPmpRq "Coolant Circulation Pump Request";
BA_ "SignalType" SG_ 1034 ClntCircPmpRq "ENM";
BA_ "GenSigSendType" SG_ 1034 ClntCircPmpRq 1;
BA_ "GenSigSendOnInit" SG_ 1034 ClntCircPmpRq 1;
BA_ "SignalLongName" SG_ 1034 SrvACSysIO "Service Air Conditioning System Indication On";
BA_ "SignalType" SG_ 1034 SrvACSysIO "BLN";
BA_ "GenSigSendType" SG_ 1034 SrvACSysIO 1;
BA_ "SignalLongName" SG_ 1217 BarPrsAbs "Barometric Pressure Absolute";
BA_ "SignalType" SG_ 1217 BarPrsAbs "UNM";
BA_ "SignalLongName" SG_ 1217 BarPrsAbsV "Barometric Pressure Absolute Validity";
BA_ "SignalType" SG_ 1217 BarPrsAbsV "ENM";
BA_ "SignalLongName" SG_ 1217 EngCltTmp "Engine Coolant Temperature";
BA_ "SignalType" SG_ 1217 EngCltTmp "UNM";
BA_ "SignalLongName" SG_ 1217 EngCltTmpV "Engine Coolant Temperature Validity";
BA_ "SignalType" SG_ 1217 EngCltTmpV "ENM";
BA_ "SignalLongName" SG_ 1217 EngIntAirTmp "Engine Intake Air Temperature";
BA_ "SignalType" SG_ 1217 EngIntAirTmp "UNM";
BA_ "SignalLongName" SG_ 1217 EngIntAirTmpV "Engine Intake Air Temperature Validity";
BA_ "SignalType" SG_ 1217 EngIntAirTmpV "ENM";
BA_ "SignalLongName" SG_ 1217 EngOilHotIO "Engine Oil Hot Indication On";
BA_ "SignalType" SG_ 1217 EngOilHotIO "BLN";
BA_ "SignalLongName" SG_ 1217 LegDiagStndCndMet "Legislated Diagnostics Standard Conditions Met";
BA_ "SignalType" SG_ 1217 LegDiagStndCndMet "BLN";
BA_ "SignalLongName" SG_ 1217 OAT_PT_Est "Outside Air Temperature Powertrain Estimated";
BA_ "SignalType" SG_ 1217 OAT_PT_Est "UNM";
BA_ "SignalLongName" SG_ 1217 OAT_PT_EstM "Outside Air Temperature Powertrain Estimated Mask";
BA_ "SignalType" SG_ 1217 OAT_PT_EstM "ENM";
BA_ "SignalLongName" SG_ 1217 OAT_PT_EstV "Outside Air Temperature Powertrain Estimated Validity";
BA_ "SignalType" SG_ 1217 OAT_PT_EstV "ENM";
BA_ "SignalLongName" SG_ 1217 LegPstDTCClrDrvCyCm "Legislated Post DTC Clear Drive Cycle Complete";
BA_ "SignalType" SG_ 1217 LegPstDTCClrDrvCyCm "BLN";
BA_ "SignalLongName" SG_ 1217 EngWrmUpAch "Engine Warm Up Cycle Achieved";
BA_ "SignalType" SG_ 1217 EngWrmUpAch "BLN";
BA_ "SignalLongName" SG_ 1233 AirCndOffIO "Air Conditioning Off Indication On";
BA_ "SignalType" SG_ 1233 AirCndOffIO "BLN";
BA_ "SignalLongName" SG_ 1233 CkFlFilrCapIO "Check Fuel Filler Cap Indication On";
BA_ "SignalType" SG_ 1233 CkFlFilrCapIO "BLN";
BA_ "SignalLongName" SG_ 1233 DslGlwPlgIO "Diesel Glow Plug Indication On";
BA_ "SignalType" SG_ 1233 DslGlwPlgIO "BLN";
BA_ "SignalLongName" SG_ 1233 EngHt_StpEngIO "Engine Hot / Stop Engine Indication On";
BA_ "SignalType" SG_ 1233 EngHt_StpEngIO "BLN";
BA_ "SignalLongName" SG_ 1233 EngHotFuelEnrchmntIO "Engine Hot Fuel Enrichment Indication On";
BA_ "SignalType" SG_ 1233 EngHotFuelEnrchmntIO "BLN";
BA_ "SignalLongName" SG_ 1233 EngOilChngIO "Engine Oil Change Indication On";
BA_ "SignalType" SG_ 1233 EngOilChngIO "BLN";
BA_ "SignalLongName" SG_ 1233 EngOilLvlLwIO "Engine Oil Level Low Indication On";
BA_ "SignalType" SG_ 1233 EngOilLvlLwIO "BLN";
BA_ "SignalLongName" SG_ 1233 EngOilPrs "Engine Oil Pressure";
BA_ "SignalType" SG_ 1233 EngOilPrs "UNM";
BA_ "SignalLongName" SG_ 1233 EngOilPrsLwIO "Engine Oil Pressure Low Indication On";
BA_ "SignalType" SG_ 1233 EngOilPrsLwIO "BLN";
BA_ "SignalLongName" SG_ 1233 EngOilPrsV "Engine Oil Pressure Validity";
BA_ "SignalType" SG_ 1233 EngOilPrsV "ENM";
BA_ "SignalLongName" SG_ 1233 EngOilTmp "Engine Oil Temperature";
BA_ "SignalType" SG_ 1233 EngOilTmp "UNM";
BA_ "SignalLongName" SG_ 1233 EngOilTmpV "Engine Oil Temperature Validity";
BA_ "SignalType" SG_ 1233 EngOilTmpV "ENM";
BA_ "SignalLongName" SG_ 1233 EngShtdwnPndgIO "Engine Shutdown Pending Indication On";
BA_ "SignalType" SG_ 1233 EngShtdwnPndgIO "BLN";
BA_ "SignalLongName" SG_ 1233 EngWtrInFlIO "Engine Water In Fuel Indication On";
BA_ "SignalType" SG_ 1233 EngWtrInFlIO "BLN";
BA_ "SignalLongName" SG_ 1233 FuelFltChgNwIO "Fuel Filter Change Now Indication On";
BA_ "SignalType" SG_ 1233 FuelFltChgNwIO "BLN";
BA_ "SignalLongName" SG_ 1233 FlLvlPct "Fuel Level Percent";
BA_ "SignalType" SG_ 1233 FlLvlPct "UNM";
BA_ "SignalLongName" SG_ 1233 FlLvlPctV "Fuel Level Percent Validity";
BA_ "SignalType" SG_ 1233 FlLvlPctV "ENM";
BA_ "SignalLongName" SG_ 1233 FuelTotCap "Fuel Total Capacity";
BA_ "SignalType" SG_ 1233 FuelTotCap "UNM";
BA_ "SignalLongName" SG_ 1233 PTExPrtclFltrWrn2IO "Powertrain Exhaust Particle Filter Warning 2 Indication On";
BA_ "SignalType" SG_ 1233 PTExPrtclFltrWrn2IO "BLN";
BA_ "SignalLongName" SG_ 1233 PTExPrtclFltrWrnIO "Powertrain Exhaust Particle Filter Warning Indication On";
BA_ "SignalType" SG_ 1233 PTExPrtclFltrWrnIO "BLN";
BA_ "SignalLongName" SG_ 1233 PTHiElecLdReqd "Powertrain High Electrical Load Requested";
BA_ "SignalType" SG_ 1233 PTHiElecLdReqd "BLN";
BA_ "SignalLongName" SG_ 1233 RdcdPwrIO "Reduced Power Indication On";
BA_ "SignalType" SG_ 1233 RdcdPwrIO "BLN";
BA_ "SignalLongName" SG_ 1387 ODIAC_ActnID "Open Display Interface Action Centerstack : Action ID";
BA_ "SignalType" SG_ 1387 ODIAC_ActnID "UNM";
BA_ "GenSigDeltaValue" SG_ 1387 ODIAC_ActnID 1;
BA_ "GenSigSendType" SG_ 1387 ODIAC_ActnID 1;
BA_ "SignalLongName" SG_ 1387 ODIAC_ActnVal "Open Display Interface Action Centerstack : Action Value";
BA_ "SignalType" SG_ 1387 ODIAC_ActnVal "UNM";
BA_ "GenSigDeltaValue" SG_ 1387 ODIAC_ActnVal 1;
BA_ "GenSigSendType" SG_ 1387 ODIAC_ActnVal 1;
BA_ "SignalLongName" SG_ 1387 ODIAC_DaTy "Open Display Interface Action Centerstack : DataType";
BA_ "SignalType" SG_ 1387 ODIAC_DaTy "ENM";
BA_ "GenSigSendType" SG_ 1387 ODIAC_DaTy 1;
BA_ "SignalLongName" SG_ 1387 ODIAC_DspMID "Open Display Interface Action Centerstack : Display Mask ID";
BA_ "SignalType" SG_ 1387 ODIAC_DspMID "ENM";
BA_ "GenSigSendType" SG_ 1387 ODIAC_DspMID 1;
BA_ "SignalLongName" SG_ 1387 ODIAC_FUCID "Open Display Interface Action Centerstack : FU Class ID";
BA_ "SignalType" SG_ 1387 ODIAC_FUCID "UNM";
BA_ "GenSigDeltaValue" SG_ 1387 ODIAC_FUCID 1;
BA_ "GenSigSendType" SG_ 1387 ODIAC_FUCID 1;
BA_ "SignalLongName" SG_ 1388 ODIAI_ActnID "Open Display Interface Action IPC : Action ID";
BA_ "SignalType" SG_ 1388 ODIAI_ActnID "UNM";
BA_ "GenSigDeltaValue" SG_ 1388 ODIAI_ActnID 1;
BA_ "GenSigSendType" SG_ 1388 ODIAI_ActnID 1;
BA_ "SignalLongName" SG_ 1388 ODIAI_ActnVal "Open Display Interface Action IPC : Action Value";
BA_ "SignalType" SG_ 1388 ODIAI_ActnVal "UNM";
BA_ "GenSigDeltaValue" SG_ 1388 ODIAI_ActnVal 1;
BA_ "GenSigSendType" SG_ 1388 ODIAI_ActnVal 1;
BA_ "SignalLongName" SG_ 1388 ODIAI_DaTy "Open Display Interface Action IPC : DataType";
BA_ "SignalType" SG_ 1388 ODIAI_DaTy "ENM";
BA_ "GenSigSendType" SG_ 1388 ODIAI_DaTy 1;
BA_ "SignalLongName" SG_ 1388 ODIAI_DspMID "Open Display Interface Action IPC : Display Mask ID";
BA_ "SignalType" SG_ 1388 ODIAI_DspMID "ENM";
BA_ "GenSigSendType" SG_ 1388 ODIAI_DspMID 1;
BA_ "SignalLongName" SG_ 1388 ODIAI_FUCID "Open Display Interface Action IPC : FU Class ID";
BA_ "SignalType" SG_ 1388 ODIAI_FUCID "UNM";
BA_ "GenSigDeltaValue" SG_ 1388 ODIAI_FUCID 1;
BA_ "GenSigSendType" SG_ 1388 ODIAI_FUCID 1;
BA_ "SignalLongName" SG_ 1395 ODDMA_DataID5 "Open Display Interface Dynamic Data Multi Request Centerstack : Data ID Five";
BA_ "SignalType" SG_ 1395 ODDMA_DataID5 "UNM";
BA_ "GenSigDeltaValue" SG_ 1395 ODDMA_DataID5 1;
BA_ "GenSigSendType" SG_ 1395 ODDMA_DataID5 1;
BA_ "SignalLongName" SG_ 1395 ODDMA_DataID5Vld "Open Display Interface Dynamic Data Multi Request Centerstack : Data ID Five Valid";
BA_ "SignalType" SG_ 1395 ODDMA_DataID5Vld "BLN";
BA_ "GenSigSendType" SG_ 1395 ODDMA_DataID5Vld 1;
BA_ "SignalLongName" SG_ 1395 ODDMA_DataID4 "Open Display Interface Dynamic Data Multi Request Centerstack : Data ID Four";
BA_ "SignalType" SG_ 1395 ODDMA_DataID4 "UNM";
BA_ "GenSigDeltaValue" SG_ 1395 ODDMA_DataID4 1;
BA_ "GenSigSendType" SG_ 1395 ODDMA_DataID4 1;
BA_ "SignalLongName" SG_ 1395 ODDMA_DataID4Vld "Open Display Interface Dynamic Data Multi Request Centerstack : Data ID Four Valid";
BA_ "SignalType" SG_ 1395 ODDMA_DataID4Vld "BLN";
BA_ "GenSigSendType" SG_ 1395 ODDMA_DataID4Vld 1;
BA_ "SignalLongName" SG_ 1395 ODDMA_DataID1 "Open Display Interface Dynamic Data Multi Request Centerstack : Data ID One";
BA_ "SignalType" SG_ 1395 ODDMA_DataID1 "UNM";
BA_ "GenSigDeltaValue" SG_ 1395 ODDMA_DataID1 1;
BA_ "GenSigSendType" SG_ 1395 ODDMA_DataID1 1;
BA_ "SignalLongName" SG_ 1395 ODDMA_DataID3 "Open Display Interface Dynamic Data Multi Request Centerstack : Data ID Three";
BA_ "SignalType" SG_ 1395 ODDMA_DataID3 "UNM";
BA_ "GenSigDeltaValue" SG_ 1395 ODDMA_DataID3 1;
BA_ "GenSigSendType" SG_ 1395 ODDMA_DataID3 1;
BA_ "SignalLongName" SG_ 1395 ODDMA_DataID3Vld "Open Display Interface Dynamic Data Multi Request Centerstack : Data ID Three Valid";
BA_ "SignalType" SG_ 1395 ODDMA_DataID3Vld "BLN";
BA_ "GenSigSendType" SG_ 1395 ODDMA_DataID3Vld 1;
BA_ "SignalLongName" SG_ 1395 ODDMA_DataID2 "Open Display Interface Dynamic Data Multi Request Centerstack : Data ID Two";
BA_ "SignalType" SG_ 1395 ODDMA_DataID2 "UNM";
BA_ "GenSigDeltaValue" SG_ 1395 ODDMA_DataID2 1;
BA_ "GenSigSendType" SG_ 1395 ODDMA_DataID2 1;
BA_ "SignalLongName" SG_ 1395 ODDMA_DataID2Vld "Open Display Interface Dynamic Data Multi Request Centerstack : Data ID Two Valid";
BA_ "SignalType" SG_ 1395 ODDMA_DataID2Vld "BLN";
BA_ "GenSigSendType" SG_ 1395 ODDMA_DataID2Vld 1;
BA_ "SignalLongName" SG_ 1395 ODDMA_DispMID "Open Display Interface Dynamic Data Multi Request Centerstack : Display Mask Id";
BA_ "SignalType" SG_ 1395 ODDMA_DispMID "ENM";
BA_ "GenSigSendType" SG_ 1395 ODDMA_DispMID 1;
BA_ "SignalLongName" SG_ 1395 ODDMA_FUCID "Open Display Interface Dynamic Data Multi Request Centerstack : Functional Unit Class ID";
BA_ "SignalType" SG_ 1395 ODDMA_FUCID "UNM";
BA_ "GenSigDeltaValue" SG_ 1395 ODDMA_FUCID 1;
BA_ "GenSigSendType" SG_ 1395 ODDMA_FUCID 1;
BA_ "SignalLongName" SG_ 1395 ODDMA_ReqType "Open Display Interface Dynamic Data Multi Request Centerstack : Request Type";
BA_ "SignalType" SG_ 1395 ODDMA_ReqType "ENM";
BA_ "GenSigSendType" SG_ 1395 ODDMA_ReqType 1;
BA_ "SignalLongName" SG_ 1396 ODDMI_DataID5 "Open Display Interface Dynamic Data Multi Request IPC : Data ID Five";
BA_ "SignalType" SG_ 1396 ODDMI_DataID5 "UNM";
BA_ "GenSigDeltaValue" SG_ 1396 ODDMI_DataID5 1;
BA_ "GenSigSendType" SG_ 1396 ODDMI_DataID5 1;
BA_ "SignalLongName" SG_ 1396 ODDMI_DataID5Vld "Open Display Interface Dynamic Data Multi Request IPC : Data ID Five Valid";
BA_ "SignalType" SG_ 1396 ODDMI_DataID5Vld "BLN";
BA_ "GenSigSendType" SG_ 1396 ODDMI_DataID5Vld 1;
BA_ "SignalLongName" SG_ 1396 ODDMI_DataID4 "Open Display Interface Dynamic Data Multi Request IPC : Data ID Four";
BA_ "SignalType" SG_ 1396 ODDMI_DataID4 "UNM";
BA_ "GenSigDeltaValue" SG_ 1396 ODDMI_DataID4 1;
BA_ "GenSigSendType" SG_ 1396 ODDMI_DataID4 1;
BA_ "SignalLongName" SG_ 1396 ODDMI_DataID4Vld "Open Display Interface Dynamic Data Multi Request IPC : Data ID Four Valid";
BA_ "SignalType" SG_ 1396 ODDMI_DataID4Vld "BLN";
BA_ "GenSigSendType" SG_ 1396 ODDMI_DataID4Vld 1;
BA_ "SignalLongName" SG_ 1396 ODDMI_DataID1 "Open Display Interface Dynamic Data Multi Request IPC : Data ID One";
BA_ "SignalType" SG_ 1396 ODDMI_DataID1 "UNM";
BA_ "GenSigDeltaValue" SG_ 1396 ODDMI_DataID1 1;
BA_ "GenSigSendType" SG_ 1396 ODDMI_DataID1 1;
BA_ "SignalLongName" SG_ 1396 ODDMI_DataID3 "Open Display Interface Dynamic Data Multi Request IPC : Data ID Three";
BA_ "SignalType" SG_ 1396 ODDMI_DataID3 "UNM";
BA_ "GenSigSendType" SG_ 1396 ODDMI_DataID3 1;
BA_ "SignalLongName" SG_ 1396 ODDMI_DataID3Vld "Open Display Interface Dynamic Data Multi Request IPC : Data ID Three Valid";
BA_ "SignalType" SG_ 1396 ODDMI_DataID3Vld "BLN";
BA_ "GenSigSendType" SG_ 1396 ODDMI_DataID3Vld 1;
BA_ "SignalLongName" SG_ 1396 ODDMI_DataID2 "Open Display Interface Dynamic Data Multi Request IPC : Data ID Two";
BA_ "SignalType" SG_ 1396 ODDMI_DataID2 "UNM";
BA_ "GenSigDeltaValue" SG_ 1396 ODDMI_DataID2 1;
BA_ "GenSigSendType" SG_ 1396 ODDMI_DataID2 1;
BA_ "SignalLongName" SG_ 1396 ODDMI_DataID2Vld "Open Display Interface Dynamic Data Multi Request IPC : Data ID Two Valid";
BA_ "SignalType" SG_ 1396 ODDMI_DataID2Vld "BLN";
BA_ "GenSigSendType" SG_ 1396 ODDMI_DataID2Vld 1;
BA_ "SignalLongName" SG_ 1396 ODDMI_DispMID "Open Display Interface Dynamic Data Multi Request IPC : Display Mask Id";
BA_ "SignalType" SG_ 1396 ODDMI_DispMID "ENM";
BA_ "GenSigSendType" SG_ 1396 ODDMI_DispMID 1;
BA_ "SignalLongName" SG_ 1396 ODDMI_FUCID "Open Display Interface Dynamic Data Multi Request IPC : Functional Unit Class ID";
BA_ "SignalType" SG_ 1396 ODDMI_FUCID "UNM";
BA_ "GenSigDeltaValue" SG_ 1396 ODDMI_FUCID 1;
BA_ "GenSigSendType" SG_ 1396 ODDMI_FUCID 1;
BA_ "SignalLongName" SG_ 1396 ODDMI_ReqType "Open Display Interface Dynamic Data Multi Request IPC : Request Type";
BA_ "SignalType" SG_ 1396 ODDMI_ReqType "ENM";
BA_ "GenSigSendType" SG_ 1396 ODDMI_ReqType 1;
BA_ "SignalLongName" SG_ 849 CldrYr_154 "Calendar Year";
BA_ "SignalType" SG_ 849 CldrYr_154 "UNM";
BA_ "GenSigDeltaValue" SG_ 849 CldrYr_154 1;
BA_ "GenSigSendType" SG_ 849 CldrYr_154 1;
BA_ "GenSigSendOnInit" SG_ 849 CldrYr_154 1;
BA_ "SignalLongName" SG_ 849 CldrMth_154 "Calendar Month";
BA_ "SignalType" SG_ 849 CldrMth_154 "ENM";
BA_ "GenSigSendType" SG_ 849 CldrMth_154 1;
BA_ "GenSigSendOnInit" SG_ 849 CldrMth_154 1;
BA_ "SignalLongName" SG_ 849 CldrDay_154 "Calendar Day";
BA_ "SignalType" SG_ 849 CldrDay_154 "UNM";
BA_ "GenSigDeltaValue" SG_ 849 CldrDay_154 1;
BA_ "GenSigSendType" SG_ 849 CldrDay_154 1;
BA_ "GenSigSendOnInit" SG_ 849 CldrDay_154 1;
BA_ "SignalLongName" SG_ 849 HrsV "Hours Validity";
BA_ "SignalType" SG_ 849 HrsV "ENM";
BA_ "GenSigSendType" SG_ 849 HrsV 1;
BA_ "GenSigSendOnInit" SG_ 849 HrsV 1;
BA_ "SignalLongName" SG_ 849 Hrs "Hours";
BA_ "SignalType" SG_ 849 Hrs "UNM";
BA_ "GenSigDeltaValue" SG_ 849 Hrs 1;
BA_ "GenSigSendType" SG_ 849 Hrs 1;
BA_ "GenSigSendOnInit" SG_ 849 Hrs 1;
BA_ "SignalLongName" SG_ 849 MinsV "Minutes Validity";
BA_ "SignalType" SG_ 849 MinsV "ENM";
BA_ "GenSigSendType" SG_ 849 MinsV 1;
BA_ "GenSigSendOnInit" SG_ 849 MinsV 1;
BA_ "SignalLongName" SG_ 849 Mins "Minutes";
BA_ "SignalType" SG_ 849 Mins "UNM";
BA_ "GenSigDeltaValue" SG_ 849 Mins 1;
BA_ "GenSigSendType" SG_ 849 Mins 1;
BA_ "GenSigSendOnInit" SG_ 849 Mins 1;
BA_ "SignalLongName" SG_ 849 SecV "Seconds Validity";
BA_ "SignalType" SG_ 849 SecV "ENM";
BA_ "GenSigSendType" SG_ 849 SecV 1;
BA_ "GenSigSendOnInit" SG_ 849 SecV 1;
BA_ "SignalLongName" SG_ 849 Sec "Seconds";
BA_ "SignalType" SG_ 849 Sec "UNM";
BA_ "GenSigDeltaValue" SG_ 849 Sec 1;
BA_ "GenSigSendType" SG_ 849 Sec 1;
BA_ "GenSigSendOnInit" SG_ 849 Sec 1;
BA_ "SignalLongName" SG_ 500 DrvSelMd1Stat "Driver Selected Mode 1 Status";
BA_ "SignalType" SG_ 500 DrvSelMd1Stat "ENM";
BA_ "SignalLongName" SG_ 500 DrvSelMd1ReqDnd "Driver Selected Mode 1 Request Denied";
BA_ "SignalType" SG_ 500 DrvSelMd1ReqDnd "BLN";
BA_ "SignalLongName" SG_ 500 DrvSelMd2Stat "Driver Selected Mode 2 Status";
BA_ "SignalType" SG_ 500 DrvSelMd2Stat "ENM";
BA_ "SignalLongName" SG_ 500 DrvSelMd2ReqDnd "Driver Selected Mode 2 Request Denied";
BA_ "SignalType" SG_ 500 DrvSelMd2ReqDnd "BLN";
BA_ "SignalLongName" SG_ 500 DrvSelMd3Stat "Driver Selected Mode 3 Status";
BA_ "SignalType" SG_ 500 DrvSelMd3Stat "ENM";
BA_ "SignalLongName" SG_ 500 DrvSelMd3ReqDnd "Driver Selected Mode 3 Request Denied";
BA_ "SignalType" SG_ 500 DrvSelMd3ReqDnd "BLN";
BA_ "SignalLongName" SG_ 500 DrvSelMd4Stat "Driver Selected Mode 4 Status";
BA_ "SignalType" SG_ 500 DrvSelMd4Stat "ENM";
BA_ "SignalLongName" SG_ 500 DrvSelMd4ReqDnd "Driver Selected Mode 4 Request Denied";
BA_ "SignalType" SG_ 500 DrvSelMd4ReqDnd "BLN";
BA_ "SignalLongName" SG_ 500 DrvSelMd5Stat "Driver Selected Mode 5 Status";
BA_ "SignalType" SG_ 500 DrvSelMd5Stat "ENM";
BA_ "SignalLongName" SG_ 500 DrvSelMd5ReqDnd "Driver Selected Mode 5 Request Denied";
BA_ "SignalType" SG_ 500 DrvSelMd5ReqDnd "BLN";
BA_ "SignalLongName" SG_ 500 DrvSelMd6Stat "Driver Selected Mode 6 Status";
BA_ "SignalType" SG_ 500 DrvSelMd6Stat "ENM";
BA_ "SignalLongName" SG_ 500 DrvSelMd6ReqDnd "Driver Selected Mode 6 Request Denied";
BA_ "SignalType" SG_ 500 DrvSelMd6ReqDnd "BLN";
BA_ "SignalLongName" SG_ 500 DrvSelMd7Stat "Driver Selected Mode 7 Status";
BA_ "SignalType" SG_ 500 DrvSelMd7Stat "ENM";
BA_ "SignalLongName" SG_ 500 DrvSelMd7ReqDnd "Driver Selected Mode 7 Request Denied";
BA_ "SignalType" SG_ 500 DrvSelMd7ReqDnd "BLN";
BA_ "SignalLongName" SG_ 500 DrvSelMd8Stat "Driver Selected Mode 8 Status";
BA_ "SignalType" SG_ 500 DrvSelMd8Stat "ENM";
BA_ "SignalLongName" SG_ 500 DrvSelMd8ReqDnd "Driver Selected Mode 8 Request Denied";
BA_ "SignalType" SG_ 500 DrvSelMd8ReqDnd "BLN";
BA_ "SignalLongName" SG_ 500 DSMSS_DrvSelMd1Un "Driver Selected Mode Selection Status : Driver Selected Mode 1 Unavailable";
BA_ "SignalType" SG_ 500 DSMSS_DrvSelMd1Un "BLN";
BA_ "SignalLongName" SG_ 500 DSMSS_DrvSelMd2Un "Driver Selected Mode Selection Status : Driver Selected Mode 2 Unavailable";
BA_ "SignalType" SG_ 500 DSMSS_DrvSelMd2Un "BLN";
BA_ "SignalLongName" SG_ 500 DSMSS_DrvSelMd3Un "Driver Selected Mode Selection Status : Driver Selected Mode 3 Unavailable";
BA_ "SignalType" SG_ 500 DSMSS_DrvSelMd3Un "BLN";
BA_ "SignalLongName" SG_ 500 DSMSS_DrvSelMd4Un "Driver Selected Mode Selection Status : Driver Selected Mode 4 Unavailable";
BA_ "SignalType" SG_ 500 DSMSS_DrvSelMd4Un "BLN";
BA_ "SignalLongName" SG_ 500 DSMSS_DrvSelMd5Un "Driver Selected Mode Selection Status : Driver Selected Mode 5 Unavailable";
BA_ "SignalType" SG_ 500 DSMSS_DrvSelMd5Un "BLN";
BA_ "SignalLongName" SG_ 500 DSMSS_DrvSelMd6Un "Driver Selected Mode Selection Status : Driver Selected Mode 6 Unavailable";
BA_ "SignalType" SG_ 500 DSMSS_DrvSelMd6Un "BLN";
BA_ "SignalLongName" SG_ 500 DSMSS_DrvSelMd7Un "Driver Selected Mode Selection Status : Driver Selected Mode 7 Unavailable";
BA_ "SignalType" SG_ 500 DSMSS_DrvSelMd7Un "BLN";
BA_ "SignalLongName" SG_ 500 DSMSS_DrvSelMd8Un "Driver Selected Mode Selection Status : Driver Selected Mode 8 Unavailable";
BA_ "SignalType" SG_ 500 DSMSS_DrvSelMd8Un "BLN";
BA_ "SignalLongName" SG_ 500 DSMSS_DrvSelMd1Pn "Driver Selected Mode Selection Status : Driver Selected Mode 1 Pending";
BA_ "SignalType" SG_ 500 DSMSS_DrvSelMd1Pn "BLN";
BA_ "SignalLongName" SG_ 500 DSMSS_DrvSelMd2Pn "Driver Selected Mode Selection Status : Driver Selected Mode 2 Pending";
BA_ "SignalType" SG_ 500 DSMSS_DrvSelMd2Pn "BLN";
BA_ "SignalLongName" SG_ 500 DSMSS_DrvSelMd3Pn "Driver Selected Mode Selection Status : Driver Selected Mode 3 Pending";
BA_ "SignalType" SG_ 500 DSMSS_DrvSelMd3Pn "BLN";
BA_ "SignalLongName" SG_ 500 DSMSS_DrvSelMd4Pn "Driver Selected Mode Selection Status : Driver Selected Mode 4 Pending";
BA_ "SignalType" SG_ 500 DSMSS_DrvSelMd4Pn "BLN";
BA_ "SignalLongName" SG_ 500 DSMSS_DrvSelMd5Pn "Driver Selected Mode Selection Status : Driver Selected Mode 5 Pending";
BA_ "SignalType" SG_ 500 DSMSS_DrvSelMd5Pn "BLN";
BA_ "SignalLongName" SG_ 500 DSMSS_DrvSelMd6Pn "Driver Selected Mode Selection Status : Driver Selected Mode 6 Pending";
BA_ "SignalType" SG_ 500 DSMSS_DrvSelMd6Pn "BLN";
BA_ "SignalLongName" SG_ 500 DSMSS_DrvSelMd7Pn "Driver Selected Mode Selection Status : Driver Selected Mode 7 Pending";
BA_ "SignalType" SG_ 500 DSMSS_DrvSelMd7Pn "BLN";
BA_ "SignalLongName" SG_ 500 DSMSS_DrvSelMd8Pn "Driver Selected Mode Selection Status : Driver Selected Mode 8 Pending";
BA_ "SignalType" SG_ 500 DSMSS_DrvSelMd8Pn "BLN";
BA_ "SignalLongName" SG_ 500 DSMSS_DrvSelMd0Pn "Driver Selected Mode Selection Status : Driver Selected Mode 0 Pending";
BA_ "SignalType" SG_ 500 DSMSS_DrvSelMd0Pn "BLN";
BA_ "SignalLongName" SG_ 1569 SrcNodeID "Source Node Identifier";
BA_ "SignalType" SG_ 1569 SrcNodeID "UNM";
BA_ "SignalLongName" SG_ 1569 UDat "User Data";
BA_ "SignalType" SG_ 1569 UDat "UNM";
BA_ "SignalLongName" SG_ 1580 SrcNodeID "Source Node Identifier";
BA_ "SignalType" SG_ 1580 SrcNodeID "UNM";
BA_ "SignalLongName" SG_ 1580 UDat "User Data";
BA_ "SignalType" SG_ 1580 UDat "UNM";
BA_ "SignalLongName" SG_ 1584 SrcNodeID "Source Node Identifier";
BA_ "SignalType" SG_ 1584 SrcNodeID "UNM";
BA_ "SignalLongName" SG_ 1584 UDat "User Data";
BA_ "SignalType" SG_ 1584 UDat "UNM";
BA_ "SignalLongName" SG_ 1586 SrcNodeID "Source Node Identifier";
BA_ "SignalType" SG_ 1586 SrcNodeID "UNM";
BA_ "SignalLongName" SG_ 1586 UDat "User Data";
BA_ "SignalType" SG_ 1586 UDat "UNM";
BA_ "SignalLongName" SG_ 1594 SrcNodeID "Source Node Identifier";
BA_ "SignalType" SG_ 1594 SrcNodeID "UNM";
BA_ "SignalLongName" SG_ 1594 UDat "User Data";
BA_ "SignalType" SG_ 1594 UDat "UNM";
BA_ "SignalLongName" SG_ 1585 SrcNodeID "Source Node Identifier";
BA_ "SignalType" SG_ 1585 SrcNodeID "UNM";
BA_ "SignalLongName" SG_ 1585 UDat "User Data";
BA_ "SignalType" SG_ 1585 UDat "UNM";
BA_ "SignalLongName" SG_ 1600 SrcNodeID "Source Node Identifier";
BA_ "SignalType" SG_ 1600 SrcNodeID "UNM";
BA_ "SignalLongName" SG_ 1600 UDat "User Data";
BA_ "SignalType" SG_ 1600 UDat "UNM";
BA_ "SignalLongName" SG_ 1595 SrcNodeID "Source Node Identifier";
BA_ "SignalType" SG_ 1595 SrcNodeID "UNM";
BA_ "SignalLongName" SG_ 1595 UDat "User Data";
BA_ "SignalType" SG_ 1595 UDat "UNM";
BA_ "SignalLongName" SG_ 1596 SrcNodeID "Source Node Identifier";
BA_ "SignalType" SG_ 1596 SrcNodeID "UNM";
BA_ "SignalLongName" SG_ 1596 UDat "User Data";
BA_ "SignalType" SG_ 1596 UDat "UNM";
BA_ "SignalLongName" SG_ 1589 SrcNodeID "Source Node Identifier";
BA_ "SignalType" SG_ 1589 SrcNodeID "UNM";
BA_ "SignalLongName" SG_ 1589 UDat "User Data";
BA_ "SignalType" SG_ 1589 UDat "UNM";
BA_ "SignalLongName" SG_ 1598 SrcNodeID "Source Node Identifier";
BA_ "SignalType" SG_ 1598 SrcNodeID "UNM";
BA_ "SignalLongName" SG_ 1598 UDat "User Data";
BA_ "SignalType" SG_ 1598 UDat "UNM";
BA_ "SignalLongName" SG_ 1572 SrcNodeID "Source Node Identifier";
BA_ "SignalType" SG_ 1572 SrcNodeID "UNM";
BA_ "SignalLongName" SG_ 1572 UDat "User Data";
BA_ "SignalType" SG_ 1572 UDat "UNM";
BA_ "SignalLongName" SG_ 1593 SrcNodeID "Source Node Identifier";
BA_ "SignalType" SG_ 1593 SrcNodeID "UNM";
BA_ "SignalLongName" SG_ 1593 UDat "User Data";
BA_ "SignalType" SG_ 1593 UDat "UNM";
BA_ "SignalLongName" SG_ 1576 SrcNodeID "Source Node Identifier";
BA_ "SignalType" SG_ 1576 SrcNodeID "UNM";
BA_ "SignalLongName" SG_ 1576 UDat "User Data";
BA_ "SignalType" SG_ 1576 UDat "UNM";
BA_ "SignalLongName" SG_ 1599 SrcNodeID "Source Node Identifier";
BA_ "SignalType" SG_ 1599 SrcNodeID "UNM";
BA_ "SignalLongName" SG_ 1599 UDat "User Data";
BA_ "SignalType" SG_ 1599 UDat "UNM";
BA_ "SignalLongName" SG_ 1020 OtsAirTmp "Outside Air Temperature";
BA_ "SignalType" SG_ 1020 OtsAirTmp "UNM";
BA_ "SignalLongName" SG_ 1020 OtsAirTmpV "Outside Air Temperature Validity";
BA_ "SignalType" SG_ 1020 OtsAirTmpV "ENM";
BA_ "SignalLongName" SG_ 1020 OtsAirTmpCrValV "Outside Air Temperature Corrected Value Validity";
BA_ "SignalType" SG_ 1020 OtsAirTmpCrValV "ENM";
BA_ "SignalLongName" SG_ 1020 OtsAirTmpCrValMsk "Outside Air Temperature Corrected Value Mask";
BA_ "SignalType" SG_ 1020 OtsAirTmpCrValMsk "ENM";
BA_ "SignalLongName" SG_ 1020 OtsAirTmpCrVal "Outside Air Temperature Corrected Value";
BA_ "SignalType" SG_ 1020 OtsAirTmpCrVal "UNM";
BA_ "SignalLongName" SG_ 1225 TrnOilTmpV "Transmission Oil Temperature Validity";
BA_ "SignalType" SG_ 1225 TrnOilTmpV "ENM";
BA_ "SignalLongName" SG_ 1225 TransOilTempSensPres "Transmission Oil Temperature Sensor Present";
BA_ "SignalType" SG_ 1225 TransOilTempSensPres "BLN";
BA_ "SignalLongName" SG_ 1225 TrnEmsMlfAtv "Transmission Emissions Related Malfunction Active";
BA_ "SignalType" SG_ 1225 TrnEmsMlfAtv "BLN";
BA_ "SignalLongName" SG_ 1225 TrnsNEmsRltMalfActv "Transmission Non Emissions Related Malfunction Active";
BA_ "SignalType" SG_ 1225 TrnsNEmsRltMalfActv "BLN";
BA_ "SignalLongName" SG_ 1225 TrnsEmisRlFrzFrmStrSt "Transmission Emission Related Freeze Frame Storage Status";
BA_ "SignalType" SG_ 1225 TrnsEmisRlFrzFrmStrSt "ENM";
BA_ "SignalLongName" SG_ 1225 TrnsThrmlMngmntStat "Transmission Thermal Management Status";
BA_ "SignalType" SG_ 1225 TrnsThrmlMngmntStat "ENM";
BA_ "SignalLongName" SG_ 1225 TrnOilTmp "Transmission Oil Temperature";
BA_ "SignalType" SG_ 1225 TrnOilTmp "UNM";
BA_ "SignalLongName" SG_ 1225 TERDTC_SysDes "Transmission Emissions Related DTC : System Designator";
BA_ "SignalType" SG_ 1225 TERDTC_SysDes "ENM";
BA_ "SignalLongName" SG_ 1225 TERDTC_CdNum "Transmission Emissions Related DTC : Code Number";
BA_ "SignalType" SG_ 1225 TERDTC_CdNum "UNM";
BA_ "SignalLongName" SG_ 1225 GrdBrkgAct "Grade Braking Active";
BA_ "SignalType" SG_ 1225 GrdBrkgAct "BLN";
BA_ "SignalLongName" SG_ 917 HVHtrFldIO "High Voltage Heater Failed Indication On";
BA_ "SignalType" SG_ 917 HVHtrFldIO "BLN";
BA_ "GenSigSendType" SG_ 917 HVHtrFldIO 1;
BA_ "SignalLongName" SG_ 917 HVHtrOvrTmpIndOn "High Voltage Heater Over Temperature Indication On";
BA_ "SignalType" SG_ 917 HVHtrOvrTmpIndOn "BLN";
BA_ "GenSigSendType" SG_ 917 HVHtrOvrTmpIndOn 1;
BA_ "SignalLongName" SG_ 922 ACCompModReq "Air Conditioning Compressor Mode Request";
BA_ "SignalType" SG_ 922 ACCompModReq "ENM";
BA_ "GenSigSendType" SG_ 922 ACCompModReq 1;
BA_ "GenSigSendOnInit" SG_ 922 ACCompModReq 1;
BA_ "SignalLongName" SG_ 922 ACCmpsrFldOn "Air Conditioning Compressor Failed On";
BA_ "SignalType" SG_ 922 ACCmpsrFldOn "BLN";
BA_ "GenSigSendType" SG_ 922 ACCmpsrFldOn 1;
BA_ "SignalLongName" SG_ 922 ACCmEngRunReq "Air Conditioning Compressor Engine Run Request";
BA_ "SignalType" SG_ 922 ACCmEngRunReq "ENM";
BA_ "GenSigSendType" SG_ 922 ACCmEngRunReq 1;
BA_ "SignalLongName" SG_ 922 ACCompNormLdV "Air Conditioning Compressor Normalized Load Validity";
BA_ "SignalType" SG_ 922 ACCompNormLdV "ENM";
BA_ "GenSigSendType" SG_ 922 ACCompNormLdV 1;
BA_ "GenSigSendOnInit" SG_ 922 ACCompNormLdV 1;
BA_ "SignalLongName" SG_ 922 ACCompNormLd "Air Conditioning Compressor Normalized Load";
BA_ "SignalType" SG_ 922 ACCompNormLd "UNM";
BA_ "GenSigDeltaValue" SG_ 922 ACCompNormLd 1;
BA_ "GenSigSendType" SG_ 922 ACCompNormLd 1;
BA_ "GenSigSendOnInit" SG_ 922 ACCompNormLd 1;
BA_ "SignalLongName" SG_ 922 ClmtCtrlTrgtTemp "Climate Control Target Temperature";
BA_ "SignalType" SG_ 922 ClmtCtrlTrgtTemp "UNM";
BA_ "GenSigDeltaValue" SG_ 922 ClmtCtrlTrgtTemp 1;
BA_ "GenSigSendType" SG_ 922 ClmtCtrlTrgtTemp 1;
BA_ "SignalLongName" SG_ 1036 ClmCntBatSaverIO "Climate Control Battery Saver Indication On";
BA_ "SignalType" SG_ 1036 ClmCntBatSaverIO "BLN";
BA_ "GenSigSendType" SG_ 1036 ClmCntBatSaverIO 1;
BA_ "SignalLongName" SG_ 1376 ODIE_EvID "Open Display Interface Event Packet ECC : Event ID";
BA_ "SignalType" SG_ 1376 ODIE_EvID "UNM";
BA_ "GenSigDeltaValue" SG_ 1376 ODIE_EvID 1;
BA_ "GenSigSendType" SG_ 1376 ODIE_EvID 1;
BA_ "SignalLongName" SG_ 1376 ODIE_FUCID "Open Display Interface Event Packet ECC : Functional Unit Class ID";
BA_ "SignalType" SG_ 1376 ODIE_FUCID "UNM";
BA_ "GenSigDeltaValue" SG_ 1376 ODIE_FUCID 1;
BA_ "GenSigSendType" SG_ 1376 ODIE_FUCID 1;
BA_ "SignalLongName" SG_ 1376 ODIE_MultiFrRetCh "Open Display Interface Event Packet ECC : MultiFrameReturnChannel";
BA_ "SignalType" SG_ 1376 ODIE_MultiFrRetCh "UNM";
BA_ "GenSigDeltaValue" SG_ 1376 ODIE_MultiFrRetCh 1;
BA_ "GenSigSendType" SG_ 1376 ODIE_MultiFrRetCh 1;
BA_ "SignalLongName" SG_ 1384 ODII_FUCID "Open Display Interface Indication ECC : Functional Unit Class ID";
BA_ "SignalType" SG_ 1384 ODII_FUCID "UNM";
BA_ "GenSigDeltaValue" SG_ 1384 ODII_FUCID 1;
BA_ "GenSigSendType" SG_ 1384 ODII_FUCID 1;
BA_ "GenSigSendOnInit" SG_ 1384 ODII_FUCID 1;
BA_ "SignalLongName" SG_ 1384 ODII_ODIInd1 "Open Display Interface Indication ECC : Open Display Interface Indication 1";
BA_ "SignalType" SG_ 1384 ODII_ODIInd1 "BLN";
BA_ "GenSigSendType" SG_ 1384 ODII_ODIInd1 1;
BA_ "GenSigSendOnInit" SG_ 1384 ODII_ODIInd1 1;
BA_ "SignalLongName" SG_ 1384 ODII_ODIInd2 "Open Display Interface Indication ECC : Open Display Interface Indication 2";
BA_ "SignalType" SG_ 1384 ODII_ODIInd2 "BLN";
BA_ "GenSigSendType" SG_ 1384 ODII_ODIInd2 1;
BA_ "GenSigSendOnInit" SG_ 1384 ODII_ODIInd2 1;
BA_ "SignalLongName" SG_ 1384 ODII_ODIInd3 "Open Display Interface Indication ECC : Open Display Interface Indication 3";
BA_ "SignalType" SG_ 1384 ODII_ODIInd3 "BLN";
BA_ "GenSigSendType" SG_ 1384 ODII_ODIInd3 1;
BA_ "GenSigSendOnInit" SG_ 1384 ODII_ODIInd3 1;
BA_ "SignalLongName" SG_ 1384 ODII_ODIInd4 "Open Display Interface Indication ECC : Open Display Interface Indication 4";
BA_ "SignalType" SG_ 1384 ODII_ODIInd4 "BLN";
BA_ "GenSigSendType" SG_ 1384 ODII_ODIInd4 1;
BA_ "GenSigSendOnInit" SG_ 1384 ODII_ODIInd4 1;
BA_ "SignalLongName" SG_ 1384 ODII_ODIInd5 "Open Display Interface Indication ECC : Open Display Interface Indication 5";
BA_ "SignalType" SG_ 1384 ODII_ODIInd5 "BLN";
BA_ "GenSigSendType" SG_ 1384 ODII_ODIInd5 1;
BA_ "GenSigSendOnInit" SG_ 1384 ODII_ODIInd5 1;
BA_ "SignalLongName" SG_ 1384 ODII_ODIInd6 "Open Display Interface Indication ECC : Open Display Interface Indication 6";
BA_ "SignalType" SG_ 1384 ODII_ODIInd6 "BLN";
BA_ "GenSigSendType" SG_ 1384 ODII_ODIInd6 1;
BA_ "GenSigSendOnInit" SG_ 1384 ODII_ODIInd6 1;
BA_ "SignalLongName" SG_ 1384 ODII_ODIInd7 "Open Display Interface Indication ECC : Open Display Interface Indication 7";
BA_ "SignalType" SG_ 1384 ODII_ODIInd7 "BLN";
BA_ "GenSigSendType" SG_ 1384 ODII_ODIInd7 1;
BA_ "GenSigSendOnInit" SG_ 1384 ODII_ODIInd7 1;
BA_ "SignalLongName" SG_ 1384 ODII_ODIInd8 "Open Display Interface Indication ECC : Open Display Interface Indication 8";
BA_ "SignalType" SG_ 1384 ODII_ODIInd8 "BLN";
BA_ "GenSigSendType" SG_ 1384 ODII_ODIInd8 1;
BA_ "GenSigSendOnInit" SG_ 1384 ODII_ODIInd8 1;
BA_ "SignalLongName" SG_ 1384 ODII_ODIInd9 "Open Display Interface Indication ECC : Open Display Interface Indication 9";
BA_ "SignalType" SG_ 1384 ODII_ODIInd9 "BLN";
BA_ "GenSigSendType" SG_ 1384 ODII_ODIInd9 1;
BA_ "GenSigSendOnInit" SG_ 1384 ODII_ODIInd9 1;
BA_ "SignalLongName" SG_ 1384 ODII_ODIInd10 "Open Display Interface Indication ECC : Open Display Interface Indication 10";
BA_ "SignalType" SG_ 1384 ODII_ODIInd10 "BLN";
BA_ "GenSigSendType" SG_ 1384 ODII_ODIInd10 1;
BA_ "GenSigSendOnInit" SG_ 1384 ODII_ODIInd10 1;
BA_ "SignalLongName" SG_ 1384 ODII_ODIInd11 "Open Display Interface Indication ECC : Open Display Interface Indication 11";
BA_ "SignalType" SG_ 1384 ODII_ODIInd11 "BLN";
BA_ "GenSigSendType" SG_ 1384 ODII_ODIInd11 1;
BA_ "GenSigSendOnInit" SG_ 1384 ODII_ODIInd11 1;
BA_ "SignalLongName" SG_ 1384 ODII_ODIInd12 "Open Display Interface Indication ECC : Open Display Interface Indication 12";
BA_ "SignalType" SG_ 1384 ODII_ODIInd12 "BLN";
BA_ "GenSigSendType" SG_ 1384 ODII_ODIInd12 1;
BA_ "GenSigSendOnInit" SG_ 1384 ODII_ODIInd12 1;
BA_ "SignalLongName" SG_ 1384 ODII_ODIInd13 "Open Display Interface Indication ECC : Open Display Interface Indication 13";
BA_ "SignalType" SG_ 1384 ODII_ODIInd13 "BLN";
BA_ "GenSigSendType" SG_ 1384 ODII_ODIInd13 1;
BA_ "GenSigSendOnInit" SG_ 1384 ODII_ODIInd13 1;
BA_ "SignalLongName" SG_ 1384 ODII_ODIInd14 "Open Display Interface Indication ECC : Open Display Interface Indication 14";
BA_ "SignalType" SG_ 1384 ODII_ODIInd14 "BLN";
BA_ "GenSigSendType" SG_ 1384 ODII_ODIInd14 1;
BA_ "GenSigSendOnInit" SG_ 1384 ODII_ODIInd14 1;
BA_ "SignalLongName" SG_ 1384 ODII_ODIInd15 "Open Display Interface Indication ECC : Open Display Interface Indication 15";
BA_ "SignalType" SG_ 1384 ODII_ODIInd15 "BLN";
BA_ "GenSigSendType" SG_ 1384 ODII_ODIInd15 1;
BA_ "GenSigSendOnInit" SG_ 1384 ODII_ODIInd15 1;
BA_ "SignalLongName" SG_ 1384 ODII_ODIInd16 "Open Display Interface Indication ECC : Open Display Interface Indication 16";
BA_ "SignalType" SG_ 1384 ODII_ODIInd16 "BLN";
BA_ "GenSigSendType" SG_ 1384 ODII_ODIInd16 1;
BA_ "GenSigSendOnInit" SG_ 1384 ODII_ODIInd16 1;
BA_ "SignalLongName" SG_ 1384 ODII_ODIInd17 "Open Display Interface Indication ECC : Open Display Interface Indication 17";
BA_ "SignalType" SG_ 1384 ODII_ODIInd17 "BLN";
BA_ "GenSigSendType" SG_ 1384 ODII_ODIInd17 1;
BA_ "GenSigSendOnInit" SG_ 1384 ODII_ODIInd17 1;
BA_ "SignalLongName" SG_ 1384 ODII_ODIInd18 "Open Display Interface Indication ECC : Open Display Interface Indication 18";
BA_ "SignalType" SG_ 1384 ODII_ODIInd18 "BLN";
BA_ "GenSigSendType" SG_ 1384 ODII_ODIInd18 1;
BA_ "GenSigSendOnInit" SG_ 1384 ODII_ODIInd18 1;
BA_ "SignalLongName" SG_ 1384 ODII_ODIInd19 "Open Display Interface Indication ECC : Open Display Interface Indication 19";
BA_ "SignalType" SG_ 1384 ODII_ODIInd19 "BLN";
BA_ "GenSigSendType" SG_ 1384 ODII_ODIInd19 1;
BA_ "GenSigSendOnInit" SG_ 1384 ODII_ODIInd19 1;
BA_ "SignalLongName" SG_ 1384 ODII_ODIInd20 "Open Display Interface Indication ECC : Open Display Interface Indication 20";
BA_ "SignalType" SG_ 1384 ODII_ODIInd20 "BLN";
BA_ "GenSigSendType" SG_ 1384 ODII_ODIInd20 1;
BA_ "GenSigSendOnInit" SG_ 1384 ODII_ODIInd20 1;
BA_ "SignalLongName" SG_ 1384 ODII_ODIInd21 "Open Display Interface Indication ECC : Open Display Interface Indication 21";
BA_ "SignalType" SG_ 1384 ODII_ODIInd21 "BLN";
BA_ "GenSigSendType" SG_ 1384 ODII_ODIInd21 1;
BA_ "GenSigSendOnInit" SG_ 1384 ODII_ODIInd21 1;
BA_ "SignalLongName" SG_ 1384 ODII_ODIInd22 "Open Display Interface Indication ECC : Open Display Interface Indication 22";
BA_ "SignalType" SG_ 1384 ODII_ODIInd22 "BLN";
BA_ "GenSigSendType" SG_ 1384 ODII_ODIInd22 1;
BA_ "GenSigSendOnInit" SG_ 1384 ODII_ODIInd22 1;
BA_ "SignalLongName" SG_ 1384 ODII_ODIInd23 "Open Display Interface Indication ECC : Open Display Interface Indication 23";
BA_ "SignalType" SG_ 1384 ODII_ODIInd23 "BLN";
BA_ "GenSigSendType" SG_ 1384 ODII_ODIInd23 1;
BA_ "GenSigSendOnInit" SG_ 1384 ODII_ODIInd23 1;
BA_ "SignalLongName" SG_ 1384 ODII_ODIInd24 "Open Display Interface Indication ECC : Open Display Interface Indication 24";
BA_ "SignalType" SG_ 1384 ODII_ODIInd24 "BLN";
BA_ "GenSigSendType" SG_ 1384 ODII_ODIInd24 1;
BA_ "GenSigSendOnInit" SG_ 1384 ODII_ODIInd24 1;
BA_ "SignalLongName" SG_ 1384 ODII_ODIInd25 "Open Display Interface Indication ECC : Open Display Interface Indication 25";
BA_ "SignalType" SG_ 1384 ODII_ODIInd25 "BLN";
BA_ "GenSigSendType" SG_ 1384 ODII_ODIInd25 1;
BA_ "GenSigSendOnInit" SG_ 1384 ODII_ODIInd25 1;
BA_ "SignalLongName" SG_ 1384 ODII_ODIInd26 "Open Display Interface Indication ECC : Open Display Interface Indication 26";
BA_ "SignalType" SG_ 1384 ODII_ODIInd26 "BLN";
BA_ "GenSigSendType" SG_ 1384 ODII_ODIInd26 1;
BA_ "GenSigSendOnInit" SG_ 1384 ODII_ODIInd26 1;
BA_ "SignalLongName" SG_ 1384 ODII_ODIInd27 "Open Display Interface Indication ECC : Open Display Interface Indication 27";
BA_ "SignalType" SG_ 1384 ODII_ODIInd27 "BLN";
BA_ "GenSigSendType" SG_ 1384 ODII_ODIInd27 1;
BA_ "GenSigSendOnInit" SG_ 1384 ODII_ODIInd27 1;
BA_ "SignalLongName" SG_ 1384 ODII_ODIInd28 "Open Display Interface Indication ECC : Open Display Interface Indication 28";
BA_ "SignalType" SG_ 1384 ODII_ODIInd28 "BLN";
BA_ "GenSigSendType" SG_ 1384 ODII_ODIInd28 1;
BA_ "GenSigSendOnInit" SG_ 1384 ODII_ODIInd28 1;
BA_ "SignalLongName" SG_ 1384 ODII_ODIInd29 "Open Display Interface Indication ECC : Open Display Interface Indication 29";
BA_ "SignalType" SG_ 1384 ODII_ODIInd29 "BLN";
BA_ "GenSigSendType" SG_ 1384 ODII_ODIInd29 1;
BA_ "GenSigSendOnInit" SG_ 1384 ODII_ODIInd29 1;
BA_ "SignalLongName" SG_ 1384 ODII_ODIInd30 "Open Display Interface Indication ECC : Open Display Interface Indication 30";
BA_ "SignalType" SG_ 1384 ODII_ODIInd30 "BLN";
BA_ "GenSigSendType" SG_ 1384 ODII_ODIInd30 1;
BA_ "GenSigSendOnInit" SG_ 1384 ODII_ODIInd30 1;
BA_ "SignalLongName" SG_ 1384 ODII_ODIInd31 "Open Display Interface Indication ECC : Open Display Interface Indication 31";
BA_ "SignalType" SG_ 1384 ODII_ODIInd31 "BLN";
BA_ "GenSigSendType" SG_ 1384 ODII_ODIInd31 1;
BA_ "GenSigSendOnInit" SG_ 1384 ODII_ODIInd31 1;
BA_ "SignalLongName" SG_ 1384 ODII_ODIInd32 "Open Display Interface Indication ECC : Open Display Interface Indication 32";
BA_ "SignalType" SG_ 1384 ODII_ODIInd32 "BLN";
BA_ "GenSigSendType" SG_ 1384 ODII_ODIInd32 1;
BA_ "GenSigSendOnInit" SG_ 1384 ODII_ODIInd32 1;
BA_ "SignalLongName" SG_ 1384 ODII_ODIInd33 "Open Display Interface Indication ECC : Open Display Interface Indication 33";
BA_ "SignalType" SG_ 1384 ODII_ODIInd33 "BLN";
BA_ "GenSigSendType" SG_ 1384 ODII_ODIInd33 1;
BA_ "GenSigSendOnInit" SG_ 1384 ODII_ODIInd33 1;
BA_ "SignalLongName" SG_ 1384 ODII_ODIInd34 "Open Display Interface Indication ECC : Open Display Interface Indication 34";
BA_ "SignalType" SG_ 1384 ODII_ODIInd34 "BLN";
BA_ "GenSigSendType" SG_ 1384 ODII_ODIInd34 1;
BA_ "GenSigSendOnInit" SG_ 1384 ODII_ODIInd34 1;
BA_ "SignalLongName" SG_ 1384 ODII_ODIInd35 "Open Display Interface Indication ECC : Open Display Interface Indication 35";
BA_ "SignalType" SG_ 1384 ODII_ODIInd35 "BLN";
BA_ "GenSigSendType" SG_ 1384 ODII_ODIInd35 1;
BA_ "GenSigSendOnInit" SG_ 1384 ODII_ODIInd35 1;
BA_ "SignalLongName" SG_ 1384 ODII_ODIInd36 "Open Display Interface Indication ECC : Open Display Interface Indication 36";
BA_ "SignalType" SG_ 1384 ODII_ODIInd36 "BLN";
BA_ "GenSigSendType" SG_ 1384 ODII_ODIInd36 1;
BA_ "GenSigSendOnInit" SG_ 1384 ODII_ODIInd36 1;
BA_ "SignalLongName" SG_ 1384 ODII_ODIInd37 "Open Display Interface Indication ECC : Open Display Interface Indication 37";
BA_ "SignalType" SG_ 1384 ODII_ODIInd37 "BLN";
BA_ "GenSigSendType" SG_ 1384 ODII_ODIInd37 1;
BA_ "GenSigSendOnInit" SG_ 1384 ODII_ODIInd37 1;
BA_ "SignalLongName" SG_ 1384 ODII_ODIInd38 "Open Display Interface Indication ECC : Open Display Interface Indication 38";
BA_ "SignalType" SG_ 1384 ODII_ODIInd38 "BLN";
BA_ "GenSigSendType" SG_ 1384 ODII_ODIInd38 1;
BA_ "GenSigSendOnInit" SG_ 1384 ODII_ODIInd38 1;
BA_ "SignalLongName" SG_ 1384 ODII_ODIInd39 "Open Display Interface Indication ECC : Open Display Interface Indication 39";
BA_ "SignalType" SG_ 1384 ODII_ODIInd39 "BLN";
BA_ "GenSigSendType" SG_ 1384 ODII_ODIInd39 1;
BA_ "GenSigSendOnInit" SG_ 1384 ODII_ODIInd39 1;
BA_ "SignalLongName" SG_ 1384 ODII_ODIInd40 "Open Display Interface Indication ECC : Open Display Interface Indication 40";
BA_ "SignalType" SG_ 1384 ODII_ODIInd40 "BLN";
BA_ "GenSigSendType" SG_ 1384 ODII_ODIInd40 1;
BA_ "GenSigSendOnInit" SG_ 1384 ODII_ODIInd40 1;
BA_ "SignalLongName" SG_ 1384 ODII_ODIInd41 "Open Display Interface Indication ECC : Open Display Interface Indication 41";
BA_ "SignalType" SG_ 1384 ODII_ODIInd41 "BLN";
BA_ "GenSigSendType" SG_ 1384 ODII_ODIInd41 1;
BA_ "GenSigSendOnInit" SG_ 1384 ODII_ODIInd41 1;
BA_ "SignalLongName" SG_ 1384 ODII_ODIInd42 "Open Display Interface Indication ECC : Open Display Interface Indication 42";
BA_ "SignalType" SG_ 1384 ODII_ODIInd42 "BLN";
BA_ "GenSigSendType" SG_ 1384 ODII_ODIInd42 1;
BA_ "GenSigSendOnInit" SG_ 1384 ODII_ODIInd42 1;
BA_ "SignalLongName" SG_ 1384 ODII_ODIInd43 "Open Display Interface Indication ECC : Open Display Interface Indication 43";
BA_ "SignalType" SG_ 1384 ODII_ODIInd43 "BLN";
BA_ "GenSigSendType" SG_ 1384 ODII_ODIInd43 1;
BA_ "GenSigSendOnInit" SG_ 1384 ODII_ODIInd43 1;
BA_ "SignalLongName" SG_ 1384 ODII_ODIInd44 "Open Display Interface Indication ECC : Open Display Interface Indication 44";
BA_ "SignalType" SG_ 1384 ODII_ODIInd44 "BLN";
BA_ "GenSigSendType" SG_ 1384 ODII_ODIInd44 1;
BA_ "GenSigSendOnInit" SG_ 1384 ODII_ODIInd44 1;
BA_ "SignalLongName" SG_ 1384 ODII_ODIInd45 "Open Display Interface Indication ECC : Open Display Interface Indication 45";
BA_ "SignalType" SG_ 1384 ODII_ODIInd45 "BLN";
BA_ "GenSigSendType" SG_ 1384 ODII_ODIInd45 1;
BA_ "GenSigSendOnInit" SG_ 1384 ODII_ODIInd45 1;
BA_ "SignalLongName" SG_ 1384 ODII_ODIInd46 "Open Display Interface Indication ECC : Open Display Interface Indication 46";
BA_ "SignalType" SG_ 1384 ODII_ODIInd46 "BLN";
BA_ "GenSigSendType" SG_ 1384 ODII_ODIInd46 1;
BA_ "GenSigSendOnInit" SG_ 1384 ODII_ODIInd46 1;
BA_ "SignalLongName" SG_ 1384 ODII_ODIInd47 "Open Display Interface Indication ECC : Open Display Interface Indication 47";
BA_ "SignalType" SG_ 1384 ODII_ODIInd47 "BLN";
BA_ "GenSigSendType" SG_ 1384 ODII_ODIInd47 1;
BA_ "GenSigSendOnInit" SG_ 1384 ODII_ODIInd47 1;
BA_ "SignalLongName" SG_ 1384 ODII_ODIInd48 "Open Display Interface Indication ECC : Open Display Interface Indication 48";
BA_ "SignalType" SG_ 1384 ODII_ODIInd48 "BLN";
BA_ "GenSigSendType" SG_ 1384 ODII_ODIInd48 1;
BA_ "GenSigSendOnInit" SG_ 1384 ODII_ODIInd48 1;
BA_ "SignalLongName" SG_ 1384 ODII_ODIInd49 "Open Display Interface Indication ECC : Open Display Interface Indication 49";
BA_ "SignalType" SG_ 1384 ODII_ODIInd49 "BLN";
BA_ "GenSigSendType" SG_ 1384 ODII_ODIInd49 1;
BA_ "GenSigSendOnInit" SG_ 1384 ODII_ODIInd49 1;
BA_ "SignalLongName" SG_ 1384 ODII_ODIInd50 "Open Display Interface Indication ECC : Open Display Interface Indication 50";
BA_ "SignalType" SG_ 1384 ODII_ODIInd50 "BLN";
BA_ "GenSigSendType" SG_ 1384 ODII_ODIInd50 1;
BA_ "GenSigSendOnInit" SG_ 1384 ODII_ODIInd50 1;
BA_ "SignalLongName" SG_ 1384 ODII_ODIInd51 "Open Display Interface Indication ECC : Open Display Interface Indication 51";
BA_ "SignalType" SG_ 1384 ODII_ODIInd51 "BLN";
BA_ "GenSigSendType" SG_ 1384 ODII_ODIInd51 1;
BA_ "GenSigSendOnInit" SG_ 1384 ODII_ODIInd51 1;
BA_ "SignalLongName" SG_ 1384 ODII_ODIInd52 "Open Display Interface Indication ECC : Open Display Interface Indication 52";
BA_ "SignalType" SG_ 1384 ODII_ODIInd52 "BLN";
BA_ "GenSigSendType" SG_ 1384 ODII_ODIInd52 1;
BA_ "GenSigSendOnInit" SG_ 1384 ODII_ODIInd52 1;
BA_ "SignalLongName" SG_ 1384 ODII_ODIInd53 "Open Display Interface Indication ECC : Open Display Interface Indication 53";
BA_ "SignalType" SG_ 1384 ODII_ODIInd53 "BLN";
BA_ "GenSigSendType" SG_ 1384 ODII_ODIInd53 1;
BA_ "GenSigSendOnInit" SG_ 1384 ODII_ODIInd53 1;
BA_ "SignalLongName" SG_ 1384 ODII_ODIInd54 "Open Display Interface Indication ECC : Open Display Interface Indication 54";
BA_ "SignalType" SG_ 1384 ODII_ODIInd54 "BLN";
BA_ "GenSigSendType" SG_ 1384 ODII_ODIInd54 1;
BA_ "GenSigSendOnInit" SG_ 1384 ODII_ODIInd54 1;
BA_ "SignalLongName" SG_ 1384 ODII_ODIInd55 "Open Display Interface Indication ECC : Open Display Interface Indication 55";
BA_ "SignalType" SG_ 1384 ODII_ODIInd55 "BLN";
BA_ "GenSigSendType" SG_ 1384 ODII_ODIInd55 1;
BA_ "GenSigSendOnInit" SG_ 1384 ODII_ODIInd55 1;
BA_ "SignalLongName" SG_ 1384 ODII_ODIInd56 "Open Display Interface Indication ECC : Open Display Interface Indication 56";
BA_ "SignalType" SG_ 1384 ODII_ODIInd56 "BLN";
BA_ "GenSigSendType" SG_ 1384 ODII_ODIInd56 1;
BA_ "GenSigSendOnInit" SG_ 1384 ODII_ODIInd56 1;
BA_ "SignalLongName" SG_ 1419 ODIEDD_Data1Value "Open Display Interface Enum Dynamic Data ECC : Data ID 1";
BA_ "SignalType" SG_ 1419 ODIEDD_Data1Value "UNM";
BA_ "GenSigDeltaValue" SG_ 1419 ODIEDD_Data1Value 1;
BA_ "GenSigSendType" SG_ 1419 ODIEDD_Data1Value 1;
BA_ "GenSigSendOnInit" SG_ 1419 ODIEDD_Data1Value 1;
BA_ "SignalLongName" SG_ 1419 ODIEDD_Data2Value "Open Display Interface Enum Dynamic Data ECC : Data ID 2";
BA_ "SignalType" SG_ 1419 ODIEDD_Data2Value "UNM";
BA_ "GenSigDeltaValue" SG_ 1419 ODIEDD_Data2Value 1;
BA_ "GenSigSendType" SG_ 1419 ODIEDD_Data2Value 1;
BA_ "GenSigSendOnInit" SG_ 1419 ODIEDD_Data2Value 1;
BA_ "SignalLongName" SG_ 1419 ODIEDD_Data3Value "Open Display Interface Enum Dynamic Data ECC : Data ID 3";
BA_ "SignalType" SG_ 1419 ODIEDD_Data3Value "UNM";
BA_ "GenSigDeltaValue" SG_ 1419 ODIEDD_Data3Value 1;
BA_ "GenSigSendType" SG_ 1419 ODIEDD_Data3Value 1;
BA_ "GenSigSendOnInit" SG_ 1419 ODIEDD_Data3Value 1;
BA_ "SignalLongName" SG_ 1419 ODIEDD_Data4Value "Open Display Interface Enum Dynamic Data ECC : Data ID 4";
BA_ "SignalType" SG_ 1419 ODIEDD_Data4Value "UNM";
BA_ "GenSigDeltaValue" SG_ 1419 ODIEDD_Data4Value 1;
BA_ "GenSigSendType" SG_ 1419 ODIEDD_Data4Value 1;
BA_ "GenSigSendOnInit" SG_ 1419 ODIEDD_Data4Value 1;
BA_ "SignalLongName" SG_ 1419 ODIEDD_Data5Value "Open Display Interface Enum Dynamic Data ECC : Data ID 5";
BA_ "SignalType" SG_ 1419 ODIEDD_Data5Value "UNM";
BA_ "GenSigDeltaValue" SG_ 1419 ODIEDD_Data5Value 1;
BA_ "GenSigSendType" SG_ 1419 ODIEDD_Data5Value 1;
BA_ "GenSigSendOnInit" SG_ 1419 ODIEDD_Data5Value 1;
BA_ "SignalLongName" SG_ 1419 ODIEDD_Data6Value "Open Display Interface Enum Dynamic Data ECC : Data ID 6";
BA_ "SignalType" SG_ 1419 ODIEDD_Data6Value "UNM";
BA_ "GenSigDeltaValue" SG_ 1419 ODIEDD_Data6Value 1;
BA_ "GenSigSendType" SG_ 1419 ODIEDD_Data6Value 1;
BA_ "GenSigSendOnInit" SG_ 1419 ODIEDD_Data6Value 1;
BA_ "SignalLongName" SG_ 1419 ODIEDD_Data7Value "Open Display Interface Enum Dynamic Data ECC : Data ID 7";
BA_ "SignalType" SG_ 1419 ODIEDD_Data7Value "UNM";
BA_ "GenSigDeltaValue" SG_ 1419 ODIEDD_Data7Value 1;
BA_ "GenSigSendType" SG_ 1419 ODIEDD_Data7Value 1;
BA_ "GenSigSendOnInit" SG_ 1419 ODIEDD_Data7Value 1;
BA_ "SignalLongName" SG_ 1419 ODIEDD_Data8Value "Open Display Interface Enum Dynamic Data ECC : Data ID 8";
BA_ "SignalType" SG_ 1419 ODIEDD_Data8Value "UNM";
BA_ "GenSigDeltaValue" SG_ 1419 ODIEDD_Data8Value 1;
BA_ "GenSigSendType" SG_ 1419 ODIEDD_Data8Value 1;
BA_ "GenSigSendOnInit" SG_ 1419 ODIEDD_Data8Value 1;
BA_ "SignalLongName" SG_ 1419 ODIEDD_Data9Value "Open Display Interface Enum Dynamic Data ECC : Data ID 9";
BA_ "SignalType" SG_ 1419 ODIEDD_Data9Value "UNM";
BA_ "GenSigDeltaValue" SG_ 1419 ODIEDD_Data9Value 1;
BA_ "GenSigSendType" SG_ 1419 ODIEDD_Data9Value 1;
BA_ "GenSigSendOnInit" SG_ 1419 ODIEDD_Data9Value 1;
BA_ "SignalLongName" SG_ 1419 ODIEDD_Data10Value "Open Display Interface Enum Dynamic Data ECC : Data ID 10";
BA_ "SignalType" SG_ 1419 ODIEDD_Data10Value "UNM";
BA_ "GenSigDeltaValue" SG_ 1419 ODIEDD_Data10Value 1;
BA_ "GenSigSendType" SG_ 1419 ODIEDD_Data10Value 1;
BA_ "GenSigSendOnInit" SG_ 1419 ODIEDD_Data10Value 1;
BA_ "SignalLongName" SG_ 1419 ODIEDD_Data11Value "Open Display Interface Enum Dynamic Data ECC : Data ID 11";
BA_ "SignalType" SG_ 1419 ODIEDD_Data11Value "UNM";
BA_ "GenSigDeltaValue" SG_ 1419 ODIEDD_Data11Value 1;
BA_ "GenSigSendType" SG_ 1419 ODIEDD_Data11Value 1;
BA_ "GenSigSendOnInit" SG_ 1419 ODIEDD_Data11Value 1;
BA_ "SignalLongName" SG_ 1419 ODIEDD_Data12Value "Open Display Interface Enum Dynamic Data ECC : Data ID 12";
BA_ "SignalType" SG_ 1419 ODIEDD_Data12Value "UNM";
BA_ "GenSigDeltaValue" SG_ 1419 ODIEDD_Data12Value 1;
BA_ "GenSigSendType" SG_ 1419 ODIEDD_Data12Value 1;
BA_ "GenSigSendOnInit" SG_ 1419 ODIEDD_Data12Value 1;
BA_ "SignalLongName" SG_ 1419 ODIEDD_Data13Value "Open Display Interface Enum Dynamic Data ECC : Data ID 13";
BA_ "SignalType" SG_ 1419 ODIEDD_Data13Value "UNM";
BA_ "GenSigDeltaValue" SG_ 1419 ODIEDD_Data13Value 1;
BA_ "GenSigSendType" SG_ 1419 ODIEDD_Data13Value 1;
BA_ "GenSigSendOnInit" SG_ 1419 ODIEDD_Data13Value 1;
BA_ "SignalLongName" SG_ 1419 ODIEDD_Data14Value "Open Display Interface Enum Dynamic Data ECC : Data ID 14";
BA_ "SignalType" SG_ 1419 ODIEDD_Data14Value "UNM";
BA_ "GenSigDeltaValue" SG_ 1419 ODIEDD_Data14Value 1;
BA_ "GenSigSendType" SG_ 1419 ODIEDD_Data14Value 1;
BA_ "GenSigSendOnInit" SG_ 1419 ODIEDD_Data14Value 1;
BA_ "SignalLongName" SG_ 1419 ODIEDD_Data15Value "Open Display Interface Enum Dynamic Data ECC : Data ID 15";
BA_ "SignalType" SG_ 1419 ODIEDD_Data15Value "UNM";
BA_ "GenSigDeltaValue" SG_ 1419 ODIEDD_Data15Value 1;
BA_ "GenSigSendType" SG_ 1419 ODIEDD_Data15Value 1;
BA_ "GenSigSendOnInit" SG_ 1419 ODIEDD_Data15Value 1;
BA_ "SignalLongName" SG_ 1419 ODIEDD_Data16Value "Open Display Interface Enum Dynamic Data ECC : Data ID 16";
BA_ "SignalType" SG_ 1419 ODIEDD_Data16Value "UNM";
BA_ "GenSigDeltaValue" SG_ 1419 ODIEDD_Data16Value 1;
BA_ "GenSigSendType" SG_ 1419 ODIEDD_Data16Value 1;
BA_ "GenSigSendOnInit" SG_ 1419 ODIEDD_Data16Value 1;
BA_ "SignalLongName" SG_ 1419 ODIEDD_Data17Value "Open Display Interface Enum Dynamic Data ECC : Data ID 17";
BA_ "SignalType" SG_ 1419 ODIEDD_Data17Value "UNM";
BA_ "GenSigDeltaValue" SG_ 1419 ODIEDD_Data17Value 1;
BA_ "GenSigSendType" SG_ 1419 ODIEDD_Data17Value 1;
BA_ "GenSigSendOnInit" SG_ 1419 ODIEDD_Data17Value 1;
BA_ "SignalLongName" SG_ 1419 ODIEDD_Data18Value "Open Display Interface Enum Dynamic Data ECC : Data ID 18";
BA_ "SignalType" SG_ 1419 ODIEDD_Data18Value "UNM";
BA_ "GenSigDeltaValue" SG_ 1419 ODIEDD_Data18Value 1;
BA_ "GenSigSendType" SG_ 1419 ODIEDD_Data18Value 1;
BA_ "GenSigSendOnInit" SG_ 1419 ODIEDD_Data18Value 1;
BA_ "SignalLongName" SG_ 1419 ODIEDD_FUCID "Open Display Interface Enum Dynamic Data ECC : Functional Unit Class ID";
BA_ "SignalType" SG_ 1419 ODIEDD_FUCID "UNM";
BA_ "GenSigDeltaValue" SG_ 1419 ODIEDD_FUCID 1;
BA_ "GenSigSendType" SG_ 1419 ODIEDD_FUCID 1;
BA_ "GenSigSendOnInit" SG_ 1419 ODIEDD_FUCID 1;
BA_ "SignalLongName" SG_ 1415 ODD_DataType "Open Display Interface Dynamic Data ECC : Data Type";
BA_ "SignalType" SG_ 1415 ODD_DataType "ENM";
BA_ "GenSigSendType" SG_ 1415 ODD_DataType 1;
BA_ "SignalLongName" SG_ 1415 ODD_InvldData "Open Display Interface Dynamic Data ECC : Invalid Data";
BA_ "SignalType" SG_ 1415 ODD_InvldData "BLN";
BA_ "GenSigSendType" SG_ 1415 ODD_InvldData 1;
BA_ "SignalLongName" SG_ 1415 ODD_FUCID "Open Display Interface Dynamic Data ECC : Functional Unit Class ID";
BA_ "SignalType" SG_ 1415 ODD_FUCID "UNM";
BA_ "GenSigDeltaValue" SG_ 1415 ODD_FUCID 1;
BA_ "GenSigSendType" SG_ 1415 ODD_FUCID 1;
BA_ "SignalLongName" SG_ 1415 ODD_DataId "Open Display Interface Dynamic Data ECC : Data ID";
BA_ "SignalType" SG_ 1415 ODD_DataId "UNM";
BA_ "GenSigDeltaValue" SG_ 1415 ODD_DataId 1;
BA_ "GenSigSendType" SG_ 1415 ODD_DataId 1;
BA_ "SignalLongName" SG_ 1415 ODD_DataVal "Open Display Interface Dynamic Data ECC : Data Value";
BA_ "SignalType" SG_ 1415 ODD_DataVal "UNM";
BA_ "GenSigDeltaValue" SG_ 1415 ODD_DataVal 1;
BA_ "GenSigSendType" SG_ 1415 ODD_DataVal 1;
BA_REL_ "GenSigTimeoutMsg" BU_SG_REL_ ECC_PB SG_ 292 BatVlt 292;
BA_REL_ "GenSigSuprvResp" BU_SG_REL_ ECC_PB SG_ 292 BatVlt 1;
BA_REL_ "GenSigTimeoutTime" BU_SG_REL_ ECC_PB SG_ 292 BatVlt 3000;
BA_REL_ "GenSigVBitResp" BU_SG_REL_ ECC_PB SG_ 292 BatVlt 1;
BA_REL_ "GenSigVBitRespComment" BU_SG_REL_ ECC_PB SG_ 292 BatVlt "BatVltV";
BA_REL_ "GenSigTimeoutMsg" BU_SG_REL_ ECC_PB SG_ 292 EnrgMgtLdShdRq 292;
BA_REL_ "GenSigSuprvResp" BU_SG_REL_ ECC_PB SG_ 292 EnrgMgtLdShdRq 1;
BA_REL_ "GenSigTimeoutTime" BU_SG_REL_ ECC_PB SG_ 292 EnrgMgtLdShdRq 3000;
BA_REL_ "GenSigTimeoutMsg" BU_SG_REL_ ECC_PB SG_ 292 BattCrntFltrd 292;
BA_REL_ "GenSigSuprvResp" BU_SG_REL_ ECC_PB SG_ 292 BattCrntFltrd 1;
BA_REL_ "GenSigTimeoutTime" BU_SG_REL_ ECC_PB SG_ 292 BattCrntFltrd 3000;
BA_REL_ "GenSigTimeoutMsg" BU_SG_REL_ ECC_PB SG_ 321 IntDimDspLvl 321;
BA_REL_ "GenSigSuprvResp" BU_SG_REL_ ECC_PB SG_ 321 IntDimDspLvl 1;
BA_REL_ "GenSigTimeoutTime" BU_SG_REL_ ECC_PB SG_ 321 IntDimDspLvl 3000;
BA_REL_ "GenSigTimeoutMsg" BU_SG_REL_ ECC_PB SG_ 321 IntDimLvl 321;
BA_REL_ "GenSigSuprvResp" BU_SG_REL_ ECC_PB SG_ 321 IntDimLvl 1;
BA_REL_ "GenSigTimeoutTime" BU_SG_REL_ ECC_PB SG_ 321 IntDimLvl 3000;
BA_REL_ "GenSigTimeoutMsg" BU_SG_REL_ ECC_PB SG_ 497 RemStrtSt 497;
BA_REL_ "GenSigSuprvResp" BU_SG_REL_ ECC_PB SG_ 497 RemStrtSt 1;
BA_REL_ "GenSigTimeoutTime" BU_SG_REL_ ECC_PB SG_ 497 RemStrtSt 3000;
BA_REL_ "GenSigTimeoutMsg" BU_SG_REL_ ECC_PB SG_ 497 SysPwrMd 497;
BA_REL_ "GenSigSuprvResp" BU_SG_REL_ ECC_PB SG_ 497 SysPwrMd 1;
BA_REL_ "GenSigTimeoutTime" BU_SG_REL_ ECC_PB SG_ 497 SysPwrMd 3000;
BA_REL_ "GenSigVBitResp" BU_SG_REL_ ECC_PB SG_ 497 SysPwrMd 1;
BA_REL_ "GenSigVBitRespComment" BU_SG_REL_ ECC_PB SG_ 497 SysPwrMd "SysPwrMdV";
BA_REL_ "GenSigRxStartValue" BU_SG_REL_ ECC_PB SG_ 497 SysPwrMdV "1";
BA_REL_ "GenSigTimeoutMsg" BU_SG_REL_ ECC_PB SG_ 837 RrWndDfgSwAtv 837;
BA_REL_ "GenSigSuprvResp" BU_SG_REL_ ECC_PB SG_ 837 RrWndDfgSwAtv 1;
BA_REL_ "GenSigTimeoutTime" BU_SG_REL_ ECC_PB SG_ 837 RrWndDfgSwAtv 3000;
BA_REL_ "GenSigTimeoutMsg" BU_SG_REL_ ECC_PB SG_ 290 SysBkUpPwrMd 290;
BA_REL_ "GenSigSuprvResp" BU_SG_REL_ ECC_PB SG_ 290 SysBkUpPwrMd 1;
BA_REL_ "GenSigTimeoutTime" BU_SG_REL_ ECC_PB SG_ 290 SysBkUpPwrMd 3000;
BA_REL_ "GenSigVBitResp" BU_SG_REL_ ECC_PB SG_ 290 SysBkUpPwrMd 1;
BA_REL_ "GenSigVBitRespComment" BU_SG_REL_ ECC_PB SG_ 290 SysBkUpPwrMd "SysBkUpPwrMdV";
BA_REL_ "GenSigRxStartValue" BU_SG_REL_ ECC_PB SG_ 290 SysBkupPwrMdEn "0";
BA_REL_ "GenSigTimeoutMsg" BU_SG_REL_ ECC_PB SG_ 290 SysBkupPwrMdEn 290;
BA_REL_ "GenSigSuprvResp" BU_SG_REL_ ECC_PB SG_ 290 SysBkupPwrMdEn 1;
BA_REL_ "GenSigTimeoutTime" BU_SG_REL_ ECC_PB SG_ 290 SysBkupPwrMdEn 3000;
BA_REL_ "GenSigRxStartValue" BU_SG_REL_ ECC_PB SG_ 290 SysBkUpPwrMdV "1";
BA_REL_ "GenSigTimeoutMsg" BU_SG_REL_ ECC_PB SG_ 400 SIRDpl 400;
BA_REL_ "GenSigSuprvResp" BU_SG_REL_ ECC_PB SG_ 400 SIRDpl 1;
BA_REL_ "GenSigTimeoutTime" BU_SG_REL_ ECC_PB SG_ 400 SIRDpl 3000;
BA_REL_ "GenSigTimeoutMsg" BU_SG_REL_ IPC_PB SG_ 448 RrWndDfgOn 448;
BA_REL_ "GenSigSuprvResp" BU_SG_REL_ IPC_PB SG_ 448 RrWndDfgOn 1;
BA_REL_ "GenSigTimeoutTime" BU_SG_REL_ IPC_PB SG_ 448 RrWndDfgOn 3000;
BA_REL_ "GenSigTimeoutMsg" BU_SG_REL_ CGM_PB SG_ 786 HtrVlvRqstdPstn 786;
BA_REL_ "GenSigSuprvResp" BU_SG_REL_ CGM_PB SG_ 786 HtrVlvRqstdPstn 1;
BA_REL_ "GenSigTimeoutTime" BU_SG_REL_ CGM_PB SG_ 786 HtrVlvRqstdPstn 3000;
BA_REL_ "GenSigTimeoutMsg" BU_SG_REL_ CGM_PB SG_ 786 ClntHtrElecPwrRat 786;
BA_REL_ "GenSigSuprvResp" BU_SG_REL_ CGM_PB SG_ 786 ClntHtrElecPwrRat 1;
BA_REL_ "GenSigTimeoutTime" BU_SG_REL_ CGM_PB SG_ 786 ClntHtrElecPwrRat 3000;
BA_REL_ "GenSigTimeoutMsg" BU_SG_REL_ CGM_PB SG_ 786 ClmCtrHiVltPwrRqtd 786;
BA_REL_ "GenSigSuprvResp" BU_SG_REL_ CGM_PB SG_ 786 ClmCtrHiVltPwrRqtd 1;
BA_REL_ "GenSigTimeoutTime" BU_SG_REL_ CGM_PB SG_ 786 ClmCtrHiVltPwrRqtd 3000;
BA_REL_ "GenSigTimeoutMsg" BU_SG_REL_ BCM_PB SG_ 1034 ACHtIdleBstLevReq_36A 1034;
BA_REL_ "GenSigSuprvResp" BU_SG_REL_ BCM_PB SG_ 1034 ACHtIdleBstLevReq_36A 1;
BA_REL_ "GenSigTimeoutTime" BU_SG_REL_ BCM_PB SG_ 1034 ACHtIdleBstLevReq_36A 6250;
BA_REL_ "GenSigTimeoutMsg" BU_SG_REL_ IPC_PB SG_ 1034 ClmCntFrBlwFnSp 1034;
BA_REL_ "GenSigSuprvResp" BU_SG_REL_ IPC_PB SG_ 1034 ClmCntFrBlwFnSp 1;
BA_REL_ "GenSigTimeoutTime" BU_SG_REL_ IPC_PB SG_ 1034 ClmCntFrBlwFnSp 3000;
BA_REL_ "GenSigTimeoutMsg" BU_SG_REL_ ECC_PB SG_ 1217 EngCltTmp 1217;
BA_REL_ "GenSigSuprvResp" BU_SG_REL_ ECC_PB SG_ 1217 EngCltTmp 1;
BA_REL_ "GenSigTimeoutTime" BU_SG_REL_ ECC_PB SG_ 1217 EngCltTmp 3000;
BA_REL_ "GenSigTimeoutMsg" BU_SG_REL_ ECC_PB SG_ 500 DrvSelMd1Stat 500;
BA_REL_ "GenSigSuprvResp" BU_SG_REL_ ECC_PB SG_ 500 DrvSelMd1Stat 1;
BA_REL_ "GenSigTimeoutTime" BU_SG_REL_ ECC_PB SG_ 500 DrvSelMd1Stat 3000;
BA_REL_ "GenSigTimeoutMsg" BU_SG_REL_ ECC_PB SG_ 500 DrvSelMd2Stat 500;
BA_REL_ "GenSigSuprvResp" BU_SG_REL_ ECC_PB SG_ 500 DrvSelMd2Stat 1;
BA_REL_ "GenSigTimeoutTime" BU_SG_REL_ ECC_PB SG_ 500 DrvSelMd2Stat 3000;
BA_REL_ "GenSigTimeoutMsg" BU_SG_REL_ ECC_PB SG_ 500 DrvSelMd3Stat 500;
BA_REL_ "GenSigSuprvResp" BU_SG_REL_ ECC_PB SG_ 500 DrvSelMd3Stat 1;
BA_REL_ "GenSigTimeoutTime" BU_SG_REL_ ECC_PB SG_ 500 DrvSelMd3Stat 3000;
BA_REL_ "GenSigTimeoutMsg" BU_SG_REL_ ECC_PB SG_ 500 DrvSelMd4Stat 500;
BA_REL_ "GenSigSuprvResp" BU_SG_REL_ ECC_PB SG_ 500 DrvSelMd4Stat 1;
BA_REL_ "GenSigTimeoutTime" BU_SG_REL_ ECC_PB SG_ 500 DrvSelMd4Stat 3000;
BA_REL_ "GenSigTimeoutMsg" BU_SG_REL_ ECC_PB SG_ 500 DrvSelMd5Stat 500;
BA_REL_ "GenSigSuprvResp" BU_SG_REL_ ECC_PB SG_ 500 DrvSelMd5Stat 1;
BA_REL_ "GenSigTimeoutTime" BU_SG_REL_ ECC_PB SG_ 500 DrvSelMd5Stat 3000;
BA_REL_ "GenSigTimeoutMsg" BU_SG_REL_ ECC_PB SG_ 500 DrvSelMd6Stat 500;
BA_REL_ "GenSigSuprvResp" BU_SG_REL_ ECC_PB SG_ 500 DrvSelMd6Stat 1;
BA_REL_ "GenSigTimeoutTime" BU_SG_REL_ ECC_PB SG_ 500 DrvSelMd6Stat 3000;
BA_REL_ "GenSigTimeoutMsg" BU_SG_REL_ ECC_PB SG_ 500 DrvSelMd7Stat 500;
BA_REL_ "GenSigSuprvResp" BU_SG_REL_ ECC_PB SG_ 500 DrvSelMd7Stat 1;
BA_REL_ "GenSigTimeoutTime" BU_SG_REL_ ECC_PB SG_ 500 DrvSelMd7Stat 3000;
BA_REL_ "GenSigTimeoutMsg" BU_SG_REL_ ECC_PB SG_ 500 DrvSelMd8Stat 500;
BA_REL_ "GenSigSuprvResp" BU_SG_REL_ ECC_PB SG_ 500 DrvSelMd8Stat 1;
BA_REL_ "GenSigTimeoutTime" BU_SG_REL_ ECC_PB SG_ 500 DrvSelMd8Stat 3000;
BA_REL_ "GenSigTimeoutMsg" BU_SG_REL_ CGM_PB SG_ 922 ACCompModReq 922;
BA_REL_ "GenSigSuprvResp" BU_SG_REL_ CGM_PB SG_ 922 ACCompModReq 1;
BA_REL_ "GenSigTimeoutTime" BU_SG_REL_ CGM_PB SG_ 922 ACCompModReq 1250;
BA_REL_ "GenSigVBitResp" BU_SG_REL_ Firewall_PB SG_ 922 ACCmpsrFldOn 1;
BA_REL_ "GenSigVBitRespComment" BU_SG_REL_ Firewall_PB SG_ 922 ACCmpsrFldOn "no validity bit signal defined";
BA_REL_ "GenSigVBitResp" BU_SG_REL_ ECM_PB SG_ 922 ACCompNormLd 1;
BA_REL_ "GenSigVBitRespComment" BU_SG_REL_ ECM_PB SG_ 922 ACCompNormLd "ACCompNormLdV";
BA_REL_ "GenSigVDAFailResp" BU_SG_REL_ ECM_PB SG_ 922 ACCompNormLd 1;
BA_REL_ "GenSigVDAFailComment" BU_SG_REL_ ECM_PB SG_ 922 ACCompNormLd "Air Conditioning Compressor System VDA";
BA_REL_ "GenSigTimeoutMsg" BU_SG_REL_ IPC_PB SG_ 1036 ClmCntBatSaverIO 1036;
BA_REL_ "GenSigSuprvResp" BU_SG_REL_ IPC_PB SG_ 1036 ClmCntBatSaverIO 1;
BA_REL_ "GenSigTimeoutTime" BU_SG_REL_ IPC_PB SG_ 1036 ClmCntBatSaverIO 3000;
VAL_ 1068 ACSAlarm0 0 "Inactive" 1 "Active" 2 "Expired" ;
VAL_ 1068 ACSAlarm1 0 "Inactive" 1 "Active" 2 "Expired" ;
VAL_ 1068 ACSAlarm10 0 "Inactive" 1 "Active" 2 "Expired" ;
VAL_ 1068 ACSAlarm11 0 "Inactive" 1 "Active" 2 "Expired" ;
VAL_ 1068 ACSAlarm12 0 "Inactive" 1 "Active" 2 "Expired" ;
VAL_ 1068 ACSAlarm13 0 "Inactive" 1 "Active" 2 "Expired" ;
VAL_ 1068 ACSAlarm14 0 "Inactive" 1 "Active" 2 "Expired" ;
VAL_ 1068 ACSAlarm15 0 "Inactive" 1 "Active" 2 "Expired" ;
VAL_ 1068 ACSAlarm2 0 "Inactive" 1 "Active" 2 "Expired" ;
VAL_ 1068 ACSAlarm3 0 "Inactive" 1 "Active" 2 "Expired" ;
VAL_ 1068 ACSAlarm4 0 "Inactive" 1 "Active" 2 "Expired" ;
VAL_ 1068 ACSAlarm5 0 "Inactive" 1 "Active" 2 "Expired" ;
VAL_ 1068 ACSAlarm6 0 "Inactive" 1 "Active" 2 "Expired" ;
VAL_ 1068 ACSAlarm7 0 "Inactive" 1 "Active" 2 "Expired" ;
VAL_ 1068 ACSAlarm8 0 "Inactive" 1 "Active" 2 "Expired" ;
VAL_ 1068 ACSAlarm9 0 "Inactive" 1 "Active" 2 "Expired" ;
VAL_ 292 BattStOfChrgCrtyLow 1 "True" 0 "False" ;
VAL_ 292 BatSOCV 0 "Valid" 1 "Invalid" ;
VAL_ 292 BatVltV 0 "Valid" 1 "Invalid" ;
VAL_ 292 BattVltIRq 0 "Battery Voltage OK" 1 "Battery Voltage Low" 2 "Battery Voltage High" ;
VAL_ 292 EnrgMgtLdShdRq 0 "No Load Shedding" 1 "Load Shed Level 1" 2 "Load Shed Level 2" 3 "Load Shed Level 3" 4 "Load Shed Level 4" ;
VAL_ 292 IntlgntBattSnsFldIO 1 "True" 0 "False" ;
VAL_ 292 SrvBattChrgSysIO 1 "True" 0 "False" ;
VAL_ 292 BatSaverIO 1 "True" 0 "False" ;
VAL_ 292 BattStOfChrgLowIO 1 "True" 0 "False" ;
VAL_ 298 DDAjrSwAtv 1 "True" 0 "False" ;
VAL_ 298 DDAjrSwAtvM 0 "Don't Use Data" 1 "Use Data" ;
VAL_ 298 DrId 0 "Driver #1" 1 "Driver #2" 2 "Driver #3" 3 "Driver #4" 4 "Driver #5" 5 "Driver #6" 6 "Driver #7" 7 "Unknown" ;
VAL_ 298 PDAjrSwAtv 1 "True" 0 "False" ;
VAL_ 298 RLDoorAjarSwAct 1 "True" 0 "False" ;
VAL_ 298 RRDoorAjarSwAct 1 "True" 0 "False" ;
VAL_ 298 VhSecNImmoIndRq 0 "No Indication" 1 "Continuous Indication" 2 "Flashing Indication" ;
VAL_ 298 HillDesCtrlMdSwAct 1 "True" 0 "False" ;
VAL_ 298 HillDesCtrlMdSwActV 0 "Valid" 1 "Invalid" ;
VAL_ 298 RrClosAjarSwAct 1 "True" 0 "False" ;
VAL_ 298 TCSysDisSwAtv 1 "True" 0 "False" ;
VAL_ 298 TCSysDisSwAtvV 0 "Valid" 1 "Invalid" ;
VAL_ 298 VehMovState 0 "Parked" 1 "Neutral" 2 "Forward" 3 "Reverse" 4 "Invalid" ;
VAL_ 298 WSWshSwAtv 1 "True" 0 "False" ;
VAL_ 298 RrClsrSnwLdIO 1 "True" 0 "False" ;
VAL_ 298 WSWprAct 1 "True" 0 "False" ;
VAL_ 298 HdSt 0 "Closed" 1 "Ajar" 2 "Open" ;
VAL_ 298 HdStV 0 "Valid" 1 "Invalid" ;
VAL_ 321 AdvFrntLghtSysEnbld 1 "True" 0 "False" ;
VAL_ 321 AutLghtCtrl 1 "True" 0 "False" ;
VAL_ 321 BrkLtsAtv 1 "True" 0 "False" ;
VAL_ 321 DispNtSchmAtv 1 "True" 0 "False" ;
VAL_ 321 DRLAct 1 "True" 0 "False" ;
VAL_ 321 FlToPsSwAtv 1 "True" 0 "False" ;
VAL_ 321 FrFogLmpsAct 1 "True" 0 "False" ;
VAL_ 321 FrFgLtIO 1 "True" 0 "False" ;
VAL_ 321 HazSwAtv 1 "True" 0 "False" ;
VAL_ 321 HdlmpBmSelectStat 0 "Unknown" 1 "Low Beams" 2 "High Beams" ;
VAL_ 321 HighBmAct 1 "True" 0 "False" ;
VAL_ 321 HiBmIO 1 "True" 0 "False" ;
VAL_ 321 LftTrnLmpAtv 0 "Off" 1 "On without telltale" 2 "On with telltale" ;
VAL_ 321 LowBmAct 1 "True" 0 "False" ;
VAL_ 321 MainLghtSw 0 "AUTO" 1 "OFF" 2 "PARKLAMP" 3 "HEADLAMP" ;
VAL_ 321 OtsdAmbtLtLvlStat 0 "Unknown" 1 "Night" 2 "Day" ;
VAL_ 321 OtsdAmbtLtLvlStatV 0 "Valid" 1 "Invalid" ;
VAL_ 321 PrkLtIO 1 "True" 0 "False" ;
VAL_ 321 RrFogLmpsAct 1 "True" 0 "False" ;
VAL_ 321 RrFgLtIO 1 "True" 0 "False" ;
VAL_ 321 RtTrnLmpAtv 0 "Off" 1 "On without telltale" 2 "On with telltale" ;
VAL_ 321 TrnSwAct 0 "No Activation" 1 "Left" 2 "Right" ;
VAL_ 321 AutoLtsActIO 1 "True" 0 "False" ;
VAL_ 321 PrkLtRightIO 1 "True" 0 "False" ;
VAL_ 321 PrkLtLeftIO 1 "True" 0 "False" ;
VAL_ 321 IntDimNtPnlAtv 1 "True" 0 "False" ;
VAL_ 321 AutoLtsInactIO 1 "True" 0 "False" ;
VAL_ 321 AutoBmSlctAllwd 1 "True" 0 "False" ;
VAL_ 321 HiBmReqd 1 "True" 0 "False" ;
VAL_ 321 RevLmpAtv 1 "True" 0 "False" ;
VAL_ 352 ImoIdSt 0 "No info" 1 "Info valid" ;
VAL_ 352 LrnEnvIdSt 0 "No_info" ;
VAL_ 352 AVHSwtchStats 0 "Not Active" 1 "Active" ;
VAL_ 1009 ACCmEngRunReq 0 "No Action" 1 "Engine Run Requested" ;
VAL_ 1009 ClmtCtrlHtrEngRunRq 0 "No Action" 1 "Engine Run Requested" ;
VAL_ 1009 EngOffTmExtRngV 0 "Valid" 1 "Invalid" ;
VAL_ 1009 PF_MinIdlBstLvlReq 0 "No Boost Requested" 1 "Boost Level 1" 2 "Boost Level 2" 3 "Boost Level 3" ;
VAL_ 1009 RstrctdPTOpModeReqd 1 "True" 0 "False" ;
VAL_ 497 ImmblzrPreRelPswdStat 0 "No Information" 1 "Information Valid" ;
VAL_ 497 PrkBrkSwAtv 1 "True" 0 "False" ;
VAL_ 497 PMMAccTrmSt 0 "Inactive" 1 "Active" ;
VAL_ 497 PMMRunCrkTrmSt 0 "Inactive" 1 "Active" ;
VAL_ 497 RemStrtSt 0 "Inactive" 1 "Active" ;
VAL_ 497 RmVehStrRq 0 "Remote Start Not Requested" 1 "Remote Start Requested" ;
VAL_ 497 SysPwrMd 0 "Off" 1 "Accessory" 2 "Run" 3 "Crank Request" ;
VAL_ 497 SysPwrMdV 0 "Valid" 1 "Invalid" ;
VAL_ 497 TrStLgMdAtv 1 "True" 0 "False" ;
VAL_ 497 ThrtlPrgrsnReq 0 "Map A" 1 "Map B" 2 "Map C" ;
VAL_ 837 RrWndDfgInhRq 0 "Allow rear window defog" 1 "Inhibit rear window defog" ;
VAL_ 837 RrWndDfgSwAtv 1 "True" 0 "False" ;
VAL_ 201 AccActPosV 0 "Valid" 1 "Invalid" ;
VAL_ 201 CrsCntAtv 1 "True" 0 "False" ;
VAL_ 201 CrsCntEnbld 1 "True" 0 "False" ;
VAL_ 201 Eng12vStrtrMtrCmmdOn 1 "True" 0 "False" ;
VAL_ 201 EngIdlAtv 1 "True" 0 "False" ;
VAL_ 201 EngAirIntBstPrV 0 "Valid" 1 "Invalid" ;
VAL_ 201 EngRunAtv 1 "True" 0 "False" ;
VAL_ 201 EngSpdStat 0 "Normal Operation" 1 "Degraded Operation" 3 "Invalid" ;
VAL_ 201 PT_BrkPedDscrtInpStat 0 "Brake Not Applied" 1 "Brake Applied" ;
VAL_ 201 PT_BrkPedDscrtInpStatV 0 "Valid" 1 "Invalid" ;
VAL_ 201 PTCrnkAbrted 1 "True" 0 "False" ;
VAL_ 201 PT_CrnkAct 1 "True" 0 "False" ;
VAL_ 201 PTRunAbrt 1 "True" 0 "False" ;
VAL_ 201 RmVhStrtEngRng 1 "True" 0 "False" ;
VAL_ 201 SpdLmtrSpdWrngEnbld 1 "True" 0 "False" ;
VAL_ 201 EngCntrlRunCrnkTrmSt 0 "Inactive" 1 "Active" ;
VAL_ 290 SysBkUpPwrMd 0 "Off" 1 "Accessory" 2 "Run" 3 "Crank Request" ;
VAL_ 290 SysBkupPwrMdEn 1 "True" 0 "False" ;
VAL_ 290 SysBkUpPwrMdV 0 "Valid" 1 "Invalid" ;
VAL_ 290 BkUpPwrMdRnCrnkOutSt 0 "FALSE" 1 "TRUE" ;
VAL_ 290 ElecPwrStrSlctdMd 0 "Standard" 1 "Comfort" 2 "Reserved" 3 "Reserved" ;
VAL_ 387 EnvIdRspSt2 0 "No_info" 1 "Info_valid" 2 "Incorrect_immo_id" 3 "Environment_id_request" ;
VAL_ 400 SIRDpl 1 "True" 0 "False" ;
VAL_ 400 NotDrvSeatStat 0 "Unknown" 1 "Unfastened" 2 "Fastened" ;
VAL_ 400 NEDLSDrFrSt1De 1 "True" 0 "False" ;
VAL_ 400 NEDLSDrFrSt2De 1 "True" 0 "False" ;
VAL_ 400 NEDLSLtSdArbgDld 1 "True" 0 "False" ;
VAL_ 400 NEDLSPaFrSt1De 1 "True" 0 "False" ;
VAL_ 400 NEDLSPaFrSt2De 1 "True" 0 "False" ;
VAL_ 400 NEDLSRtSdArbgDld 1 "True" 0 "False" ;
VAL_ 400 NEDLSSdCrtnArbgDpld 1 "True" 0 "False" ;
VAL_ 400 NESSFrImpPreSevSt 1 "True" 0 "False" ;
VAL_ 400 NESSFrImpSt1SevSt 1 "True" 0 "False" ;
VAL_ 400 NESSFrImpSt2SevSt 1 "True" 0 "False" ;
VAL_ 400 NESSLeSiSevSt 1 "True" 0 "False" ;
VAL_ 400 NESSReImpSevSt 1 "True" 0 "False" ;
VAL_ 400 NESSRiSiSevSt 1 "True" 0 "False" ;
VAL_ 400 NESSRoSevSt 1 "True" 0 "False" ;
VAL_ 400 NotEventStat 0 "No Event" 1 "Near Deployment Event" 2 "Pretensioner Deployment Event" 3 "Airbag Deployment Event" ;
VAL_ 400 NotiFrntPasSeatOccSta 0 "Unknown" 1 "Empty" 2 "OccupiedUnknown" 3 "OccupiedChildseat" 4 "OccupiedSmall" 5 "OccupiedLarge" ;
VAL_ 400 NotPsSeatStat 0 "Unknown" 1 "Unfastened" 2 "Fastened" ;
VAL_ 400 NotSecRowCtSeaOccStat 0 "Unknown" 1 "Empty" 2 "Occupied" ;
VAL_ 400 NotSecRowLeSeaOccStat 0 "Unknown" 1 "Empty" 2 "Occupied" ;
VAL_ 400 NotSndRwLtSeatStat 0 "Unknown" 1 "Unfastened" 2 "Fastened" ;
VAL_ 400 NotSndRwMdlSeatStat 0 "Unknown" 1 "Unfastened" 2 "Fastened" ;
VAL_ 400 NotSecRowRtSeaOccStat 0 "Unknown" 1 "Empty" 2 "Occupied" ;
VAL_ 400 NotSndRwRtSeatStat 0 "Unknown" 1 "Unfastened" 2 "Fastened" ;
VAL_ 448 RrWndDfgOn 1 "True" 0 "False" ;
VAL_ 544 A2ERRAlrmReq 0 "No Action" 1 "Set Alarm" 2 "Cancel Alarm" ;
VAL_ 544 EstBulkIntAirTmpV 0 "Valid" 1 "Invalid" ;
VAL_ 544 EstIntRfSrfcTmpV 0 "Valid" 1 "Invalid" ;
VAL_ 786 ClntHtrElecPwrRatV 0 "Valid" 1 "Invalid" ;
VAL_ 786 HtrVlvRqstdPstn 0 "No Request" 1 "Engine Bypass" 2 "Engine Link" 3 "Hold Current Position" ;
VAL_ 786 ClmtCtrlHtrEngRunRq 0 "No Action" 1 "Engine Run Requested" ;
VAL_ 786 ClimCtrlVoltBstModReq 1 "True" 0 "False" ;
VAL_ 977 ACCompCmnd 0 "Off" 1 "On" ;
VAL_ 977 CrsCntlDrSelSpdAct 1 "True" 0 "False" ;
VAL_ 977 EngBstPrsIndV 0 "Valid" 1 "Invalid" ;
VAL_ 977 EngCstFlCutAct 1 "True" 0 "False" ;
VAL_ 977 EngEmsRelMalfIndReq 0 "Continuous Indication" 1 "No Indication" 2 "Flashing 1 Hertz Indication" 3 "Flashing 2 Hertz Indication" 4 "Flashing 0.5 Hertz Indication" ;
VAL_ 977 EngNEmsnsRelMalfAct 1 "True" 0 "False" ;
VAL_ 977 EngOilLifRstPerf 1 "True" 0 "False" ;
VAL_ 977 EngOilStrvtnIO 1 "True" 0 "False" ;
VAL_ 977 FuelFltLifRstPerf 1 "True" 0 "False" ;
VAL_ 977 SpdLmtrSpdWrngAct 1 "True" 0 "False" ;
VAL_ 977 ThrPosV 0 "Valid" 1 "Invalid" ;
VAL_ 977 AutoMdSpdLmtStat 0 "No Speed Limit Change" 1 "Proposed Speed Limit Change" 2 "Accepted Speed Limit Change" 3 "Declined Speed Limit Change" ;
VAL_ 1001 DstRolCntAvgDrnRstOc 1 "True" 0 "False" ;
VAL_ 1001 DistRollCntAvgDrvnSrc 0 "Transmission Output Speed" 1 "Wheel Speed" ;
VAL_ 1001 DistRollCntAvgDrvnV 0 "Valid" 1 "Invalid" ;
VAL_ 1001 DstRolCntAvNDrRstOc 1 "True" 0 "False" ;
VAL_ 1001 DstRolCntAvgNonDrvnV 0 "Valid" 1 "Invalid" ;
VAL_ 1001 VehSpdAvgDrvnSrc 0 "Transmission Output Speed" 1 "Wheel Speed" ;
VAL_ 1001 VehSpdAvgDrvnV 0 "Valid" 1 "Invalid" ;
VAL_ 1001 VehSpdAvgNDrvnV 0 "Valid" 1 "Invalid" ;
VAL_ 1017 ACRfHiSdFldPrsV 0 "Valid" 1 "Invalid" ;
VAL_ 1017 EngSpdLmtnMdAct 1 "True" 0 "False" ;
VAL_ 1017 FlInjRlCtRstOcc 1 "True" 0 "False" ;
VAL_ 1017 GenFld 1 "True" 0 "False" ;
VAL_ 1017 GenFldDutCycV 0 "Valid" 1 "Invalid" ;
VAL_ 1017 GenStptDtCycPtOvrAct 1 "True" 0 "False" ;
VAL_ 1017 VehTopSpdLmtMdAct 1 "True" 0 "False" ;
VAL_ 1034 AirCndActIO 1 "True" 0 "False" ;
VAL_ 1034 ACHtIdleBstLevReq_36A 0 "No Boost Requested" 1 "Boost Level 1" 2 "Boost Level 2" 3 "Boost Level 3" ;
VAL_ 1034 ClmCntlExtDefActIO 1 "True" 0 "False" ;
VAL_ 1034 ClntCircPmpRq 0 "Off" 1 "On" ;
VAL_ 1034 SrvACSysIO 1 "True" 0 "False" ;
VAL_ 1217 BarPrsAbsV 0 "Valid" 1 "Invalid" ;
VAL_ 1217 EngCltTmpV 0 "Valid" 1 "Invalid" ;
VAL_ 1217 EngIntAirTmpV 0 "Valid" 1 "Invalid" ;
VAL_ 1217 EngOilHotIO 1 "True" 0 "False" ;
VAL_ 1217 LegDiagStndCndMet 1 "True" 0 "False" ;
VAL_ 1217 OAT_PT_EstM 0 "Don't Use Data" 1 "Use Data" ;
VAL_ 1217 OAT_PT_EstV 0 "Valid" 1 "Invalid" ;
VAL_ 1217 LegPstDTCClrDrvCyCm 1 "True" 0 "False" ;
VAL_ 1217 EngWrmUpAch 1 "True" 0 "False" ;
VAL_ 1233 AirCndOffIO 1 "True" 0 "False" ;
VAL_ 1233 CkFlFilrCapIO 1 "True" 0 "False" ;
VAL_ 1233 DslGlwPlgIO 1 "True" 0 "False" ;
VAL_ 1233 EngHt_StpEngIO 1 "True" 0 "False" ;
VAL_ 1233 EngHotFuelEnrchmntIO 1 "True" 0 "False" ;
VAL_ 1233 EngOilChngIO 1 "True" 0 "False" ;
VAL_ 1233 EngOilLvlLwIO 1 "True" 0 "False" ;
VAL_ 1233 EngOilPrsLwIO 1 "True" 0 "False" ;
VAL_ 1233 EngOilPrsV 0 "Valid" 1 "Invalid" ;
VAL_ 1233 EngOilTmpV 0 "Valid" 1 "Invalid" ;
VAL_ 1233 EngShtdwnPndgIO 1 "True" 0 "False" ;
VAL_ 1233 EngWtrInFlIO 1 "True" 0 "False" ;
VAL_ 1233 FuelFltChgNwIO 1 "True" 0 "False" ;
VAL_ 1233 FlLvlPctV 0 "Valid" 1 "Invalid" ;
VAL_ 1233 PTExPrtclFltrWrn2IO 1 "True" 0 "False" ;
VAL_ 1233 PTExPrtclFltrWrnIO 1 "True" 0 "False" ;
VAL_ 1233 PTHiElecLdReqd 1 "True" 0 "False" ;
VAL_ 1233 RdcdPwrIO 1 "True" 0 "False" ;
VAL_ 1387 ODIAC_DaTy 0 "Speed" 1 "String" 2 "Integer" 3 "EnumerationValue" 4 "Decimal" 5 "Time" 6 "Date" 7 "List" 8 "Pictogram" 9 "TextId" 10 "BitmapId" 11 "DistanceLong" 12 "DistanceShort" 13 "Volume" 14 "Temperature" 15 "Pressure" 16 "Fuel Consumption" 17 "Fuel Consumption Inverted" 18 "Character" 19 "HoursOfDay" 20 "DecimalShort" 21 "Bitmap" ;
VAL_ 1387 ODIAC_DspMID 1 "IPC" 2 "Centerstack" 4 "AuxIP" 8 "RearDisplayOne" 16 "RearDisplayTwo" 32 "ECC" 64 "Info_Faceplate" 128 "ECC_Faceplate" ;
VAL_ 1388 ODIAI_DaTy 0 "Speed" 1 "String" 2 "Integer" 3 "EnumerationValue" 4 "Decimal" 5 "Time" 6 "Date" 7 "List" 8 "Pictogram" 9 "TextId" 10 "BitmapId" 11 "DistanceLong" 12 "DistanceShort" 13 "Volume" 14 "Temperature" 15 "Pressure" 16 "Fuel Consumption" 17 "Fuel Consumption Inverted" 18 "Character" 19 "HoursOfDay" 20 "DecimalShort" 21 "Bitmap" ;
VAL_ 1388 ODIAI_DspMID 1 "IPC" 2 "Centerstack" 4 "AuxIP" 8 "RearDisplayOne" 16 "RearDisplayTwo" 32 "ECC" 64 "Info_Faceplate" 128 "ECC_Faceplate" ;
VAL_ 1395 ODDMA_DataID5Vld 1 "True" 0 "False" ;
VAL_ 1395 ODDMA_DataID4Vld 1 "True" 0 "False" ;
VAL_ 1395 ODDMA_DataID3Vld 1 "True" 0 "False" ;
VAL_ 1395 ODDMA_DataID2Vld 1 "True" 0 "False" ;
VAL_ 1395 ODDMA_DispMID 1 "IPC" 2 "Centerstack" 4 "AuxIP" 8 "RearDisplayOne" 16 "RearDisplayTwo" 32 "OTIM" 64 "Info_Faceplate" 128 "Reserved" ;
VAL_ 1395 ODDMA_ReqType 0 "Subscribe: FU sends DynData back and then on change)" 1 "Unsubscribe: cancel previous Subscribe" ;
VAL_ 1396 ODDMI_DataID5Vld 1 "True" 0 "False" ;
VAL_ 1396 ODDMI_DataID4Vld 1 "True" 0 "False" ;
VAL_ 1396 ODDMI_DataID3Vld 1 "True" 0 "False" ;
VAL_ 1396 ODDMI_DataID2Vld 1 "True" 0 "False" ;
VAL_ 1396 ODDMI_DispMID 1 "IPC" 2 "Centerstack" 4 "AuxIP" 8 "RearDisplayOne" 16 "RearDisplayTwo" 32 "OTIM" 64 "Info_Faceplate" 128 "Reserved" ;
VAL_ 1396 ODDMI_ReqType 0 "Subscribe: FU sends DynData back and then on change)" 1 "Unsubscribe: cancel previous Subscribe" ;
VAL_ 849 CldrMth_154 0 "Unknown" 1 "January" 2 "February" 3 "March" 4 "April" 5 "May" 6 "June" 7 "July" 8 "August" 9 "September" 10 "October" 11 "November" 12 "December" ;
VAL_ 849 HrsV 0 "Valid" 1 "Invalid" ;
VAL_ 849 MinsV 0 "Valid" 1 "Invalid" ;
VAL_ 849 SecV 0 "Valid" 1 "Invalid" ;
VAL_ 500 DrvSelMd1Stat 0 "Inactive" 1 "Active" ;
VAL_ 500 DrvSelMd1ReqDnd 1 "True" 0 "False" ;
VAL_ 500 DrvSelMd2Stat 0 "Inactive" 1 "Active" ;
VAL_ 500 DrvSelMd2ReqDnd 1 "True" 0 "False" ;
VAL_ 500 DrvSelMd3Stat 0 "Inactive" 1 "Active" ;
VAL_ 500 DrvSelMd3ReqDnd 1 "True" 0 "False" ;
VAL_ 500 DrvSelMd4Stat 0 "Inactive" 1 "Active" ;
VAL_ 500 DrvSelMd4ReqDnd 1 "True" 0 "False" ;
VAL_ 500 DrvSelMd5Stat 0 "Inactive" 1 "Active" ;
VAL_ 500 DrvSelMd5ReqDnd 1 "True" 0 "False" ;
VAL_ 500 DrvSelMd6Stat 0 "Inactive" 1 "Active" ;
VAL_ 500 DrvSelMd6ReqDnd 1 "True" 0 "False" ;
VAL_ 500 DrvSelMd7Stat 0 "Inactive" 1 "Active" ;
VAL_ 500 DrvSelMd7ReqDnd 1 "True" 0 "False" ;
VAL_ 500 DrvSelMd8Stat 0 "Inactive" 1 "Active" ;
VAL_ 500 DrvSelMd8ReqDnd 1 "True" 0 "False" ;
VAL_ 500 DSMSS_DrvSelMd1Un 1 "True" 0 "False" ;
VAL_ 500 DSMSS_DrvSelMd2Un 1 "True" 0 "False" ;
VAL_ 500 DSMSS_DrvSelMd3Un 1 "True" 0 "False" ;
VAL_ 500 DSMSS_DrvSelMd4Un 1 "True" 0 "False" ;
VAL_ 500 DSMSS_DrvSelMd5Un 1 "True" 0 "False" ;
VAL_ 500 DSMSS_DrvSelMd6Un 1 "True" 0 "False" ;
VAL_ 500 DSMSS_DrvSelMd7Un 1 "True" 0 "False" ;
VAL_ 500 DSMSS_DrvSelMd8Un 1 "True" 0 "False" ;
VAL_ 500 DSMSS_DrvSelMd1Pn 1 "True" 0 "False" ;
VAL_ 500 DSMSS_DrvSelMd2Pn 1 "True" 0 "False" ;
VAL_ 500 DSMSS_DrvSelMd3Pn 1 "True" 0 "False" ;
VAL_ 500 DSMSS_DrvSelMd4Pn 1 "True" 0 "False" ;
VAL_ 500 DSMSS_DrvSelMd5Pn 1 "True" 0 "False" ;
VAL_ 500 DSMSS_DrvSelMd6Pn 1 "True" 0 "False" ;
VAL_ 500 DSMSS_DrvSelMd7Pn 1 "True" 0 "False" ;
VAL_ 500 DSMSS_DrvSelMd8Pn 1 "True" 0 "False" ;
VAL_ 500 DSMSS_DrvSelMd0Pn 1 "True" 0 "False" ;
VAL_ 1020 OtsAirTmpV 0 "Valid" 1 "Invalid" ;
VAL_ 1020 OtsAirTmpCrValV 0 "Valid" 1 "Invalid" ;
VAL_ 1020 OtsAirTmpCrValMsk 0 "Don't Use Data" 1 "Use Data" ;
VAL_ 1225 TrnOilTmpV 0 "Valid" 1 "Invalid" ;
VAL_ 1225 TransOilTempSensPres 1 "True" 0 "False" ;
VAL_ 1225 TrnEmsMlfAtv 1 "True" 0 "False" ;
VAL_ 1225 TrnsNEmsRltMalfActv 1 "True" 0 "False" ;
VAL_ 1225 TrnsEmisRlFrzFrmStrSt 0 "Empty" 1 "Pending" 2 "Full" 3 "Reserved" ;
VAL_ 1225 TrnsThrmlMngmntStat 0 "Normal" 1 "Countermeasures Active" 2 "Driver Intervention Requested" ;
VAL_ 1225 TERDTC_SysDes 0 "P0-Powertrain Codes SAE Controlled" 1 "P1-Powertrain Codes MFG Controlled" 2 "P2-Powertrain Codes Reserved" 3 "P3-Powertrain Codes Reserved" 4 "C0-Chassis Codes SAE Controlled" 5 "C1-Chassis Codes MFG Controlled" 6 "C2-Chassis Codes Reserved" 7 "C3-Chassis Codes Reserved" 8 "B0-Body Codes SAE Controlled" 9 "B1-Body Codes MFG Controlled" 10 "B2-Body Codes Reserved" 11 "B3-Body Codes Reserved" 12 "U0-Network Codes SAE Controlled" 13 "U1-Network Codes MFG Controlled" 14 "U2-Network Codes Reserved" 15 "U3-Network Codes Reserved" ;
VAL_ 1225 GrdBrkgAct 1 "True" 0 "False" ;
VAL_ 917 HVHtrFldIO 1 "True" 0 "False" ;
VAL_ 917 HVHtrOvrTmpIndOn 1 "True" 0 "False" ;
VAL_ 922 ACCompModReq 0 "Disengage Immediately" 1 "Disengage" 2 "Engage" 3 "No Action" ;
VAL_ 922 ACCmpsrFldOn 1 "True" 0 "False" ;
VAL_ 922 ACCmEngRunReq 0 "No Action" 1 "Engine Run Requested" ;
VAL_ 922 ACCompNormLdV 0 "Valid" 1 "Invalid" ;
VAL_ 1036 ClmCntBatSaverIO 1 "True" 0 "False" ;
VAL_ 1384 ODII_ODIInd1 1 "True" 0 "False" ;
VAL_ 1384 ODII_ODIInd2 1 "True" 0 "False" ;
VAL_ 1384 ODII_ODIInd3 1 "True" 0 "False" ;
VAL_ 1384 ODII_ODIInd4 1 "True" 0 "False" ;
VAL_ 1384 ODII_ODIInd5 1 "True" 0 "False" ;
VAL_ 1384 ODII_ODIInd6 1 "True" 0 "False" ;
VAL_ 1384 ODII_ODIInd7 1 "True" 0 "False" ;
VAL_ 1384 ODII_ODIInd8 1 "True" 0 "False" ;
VAL_ 1384 ODII_ODIInd9 1 "True" 0 "False" ;
VAL_ 1384 ODII_ODIInd10 1 "True" 0 "False" ;
VAL_ 1384 ODII_ODIInd11 1 "True" 0 "False" ;
VAL_ 1384 ODII_ODIInd12 1 "True" 0 "False" ;
VAL_ 1384 ODII_ODIInd13 1 "True" 0 "False" ;
VAL_ 1384 ODII_ODIInd14 1 "True" 0 "False" ;
VAL_ 1384 ODII_ODIInd15 1 "True" 0 "False" ;
VAL_ 1384 ODII_ODIInd16 1 "True" 0 "False" ;
VAL_ 1384 ODII_ODIInd17 1 "True" 0 "False" ;
VAL_ 1384 ODII_ODIInd18 1 "True" 0 "False" ;
VAL_ 1384 ODII_ODIInd19 1 "True" 0 "False" ;
VAL_ 1384 ODII_ODIInd20 1 "True" 0 "False" ;
VAL_ 1384 ODII_ODIInd21 1 "True" 0 "False" ;
VAL_ 1384 ODII_ODIInd22 1 "True" 0 "False" ;
VAL_ 1384 ODII_ODIInd23 1 "True" 0 "False" ;
VAL_ 1384 ODII_ODIInd24 1 "True" 0 "False" ;
VAL_ 1384 ODII_ODIInd25 1 "True" 0 "False" ;
VAL_ 1384 ODII_ODIInd26 1 "True" 0 "False" ;
VAL_ 1384 ODII_ODIInd27 1 "True" 0 "False" ;
VAL_ 1384 ODII_ODIInd28 1 "True" 0 "False" ;
VAL_ 1384 ODII_ODIInd29 1 "True" 0 "False" ;
VAL_ 1384 ODII_ODIInd30 1 "True" 0 "False" ;
VAL_ 1384 ODII_ODIInd31 1 "True" 0 "False" ;
VAL_ 1384 ODII_ODIInd32 1 "True" 0 "False" ;
VAL_ 1384 ODII_ODIInd33 1 "True" 0 "False" ;
VAL_ 1384 ODII_ODIInd34 1 "True" 0 "False" ;
VAL_ 1384 ODII_ODIInd35 1 "True" 0 "False" ;
VAL_ 1384 ODII_ODIInd36 1 "True" 0 "False" ;
VAL_ 1384 ODII_ODIInd37 1 "True" 0 "False" ;
VAL_ 1384 ODII_ODIInd38 1 "True" 0 "False" ;
VAL_ 1384 ODII_ODIInd39 1 "True" 0 "False" ;
VAL_ 1384 ODII_ODIInd40 1 "True" 0 "False" ;
VAL_ 1384 ODII_ODIInd41 1 "True" 0 "False" ;
VAL_ 1384 ODII_ODIInd42 1 "True" 0 "False" ;
VAL_ 1384 ODII_ODIInd43 1 "True" 0 "False" ;
VAL_ 1384 ODII_ODIInd44 1 "True" 0 "False" ;
VAL_ 1384 ODII_ODIInd45 1 "True" 0 "False" ;
VAL_ 1384 ODII_ODIInd46 1 "True" 0 "False" ;
VAL_ 1384 ODII_ODIInd47 1 "True" 0 "False" ;
VAL_ 1384 ODII_ODIInd48 1 "True" 0 "False" ;
VAL_ 1384 ODII_ODIInd49 1 "True" 0 "False" ;
VAL_ 1384 ODII_ODIInd50 1 "True" 0 "False" ;
VAL_ 1384 ODII_ODIInd51 1 "True" 0 "False" ;
VAL_ 1384 ODII_ODIInd52 1 "True" 0 "False" ;
VAL_ 1384 ODII_ODIInd53 1 "True" 0 "False" ;
VAL_ 1384 ODII_ODIInd54 1 "True" 0 "False" ;
VAL_ 1384 ODII_ODIInd55 1 "True" 0 "False" ;
VAL_ 1384 ODII_ODIInd56 1 "True" 0 "False" ;
VAL_ 1415 ODD_DataType 0 "Speed" 1 "String" 2 "Integer" 3 "EnumerationValue" 4 "Decimal" 5 "Time" 6 "Date" 7 "List" 8 "Pictogram" 9 "TextId" 10 "BitmapId" 11 "DistanceLong" 12 "DistanceShort" 13 "Volume" 14 "Temperature" 15 "Pressure" 16 "Fuel Consumption" 17 "Fuel Consumption Inverted" 18 "Character" 19 "HoursOfDay" 20 "DecimalShort" 21 "Bitmap" ;
VAL_ 1415 ODD_InvldData 1 "True" 0 "False" ;
SIG_GROUP_ 1068 AlrmClkStat 1 : ACSAlarm0 ACSAlarm1 ACSAlarm10 ACSAlarm11 ACSAlarm12 ACSAlarm13 ACSAlarm14 ACSAlarm15 ACSAlarm2 ACSAlarm3 ACSAlarm4 ACSAlarm5 ACSAlarm6 ACSAlarm7 ACSAlarm8 ACSAlarm9;
SIG_GROUP_ 400 NoEvDeLoSt 1 : NEDLSDrFrSt1De NEDLSDrFrSt2De NEDLSLtSdArbgDld NEDLSPaFrSt1De NEDLSPaFrSt2De NEDLSRtSdArbgDld NEDLSSdCrtnArbgDpld;
SIG_GROUP_ 400 NoEvSevSt 1 : NESSFrImpPreSevSt NESSFrImpSt1SevSt NESSFrImpSt2SevSt NESSLeSiSevSt NESSReImpSevSt NESSRiSiSevSt NESSRoSevSt;
SIG_GROUP_ 544 Alrm2ExtRngReq 1 : A2ERRAlrmReq A2ERRAlrmTime;
SIG_GROUP_ 1387 ODIActn_CntrStck 1 : ODIAC_ActnID ODIAC_ActnVal ODIAC_DaTy ODIAC_DspMID ODIAC_FUCID;
SIG_GROUP_ 1388 ODIActn_IPC 1 : ODIAI_ActnID ODIAI_ActnVal ODIAI_DaTy ODIAI_DspMID ODIAI_FUCID;
SIG_GROUP_ 1395 ODIDynDataMltRq_CntrStck 1 : ODDMA_DataID5 ODDMA_DataID5Vld ODDMA_DataID4 ODDMA_DataID4Vld ODDMA_DataID1 ODDMA_DataID3 ODDMA_DataID3Vld ODDMA_DataID2 ODDMA_DataID2Vld ODDMA_DispMID ODDMA_FUCID ODDMA_ReqType;
SIG_GROUP_ 1396 ODIDynDataMltRq_IPC 1 : ODDMI_DataID5 ODDMI_DataID5Vld ODDMI_DataID4 ODDMI_DataID4Vld ODDMI_DataID1 ODDMI_DataID3 ODDMI_DataID3Vld ODDMI_DataID2 ODDMI_DataID2Vld ODDMI_DispMID ODDMI_FUCID ODDMI_ReqType;
SIG_GROUP_ 500 DrvSelMdSelnStat 1 : DSMSS_DrvSelMd1Un DSMSS_DrvSelMd2Un DSMSS_DrvSelMd3Un DSMSS_DrvSelMd4Un DSMSS_DrvSelMd5Un DSMSS_DrvSelMd6Un DSMSS_DrvSelMd7Un DSMSS_DrvSelMd8Un DSMSS_DrvSelMd1Pn DSMSS_DrvSelMd2Pn DSMSS_DrvSelMd3Pn DSMSS_DrvSelMd4Pn DSMSS_DrvSelMd5Pn DSMSS_DrvSelMd6Pn DSMSS_DrvSelMd7Pn DSMSS_DrvSelMd8Pn;
SIG_GROUP_ 1225 TransEmsnsRelDTC 1 : TERDTC_SysDes TERDTC_CdNum;
SIG_GROUP_ 1376 ODIEvntPkt 1 : ODIE_EvID ODIE_FUCID ODIE_MultiFrRetCh;
SIG_GROUP_ 1384 ODIInd 1 : ODII_FUCID ODII_ODIInd1 ODII_ODIInd2 ODII_ODIInd3 ODII_ODIInd4 ODII_ODIInd5 ODII_ODIInd6 ODII_ODIInd7 ODII_ODIInd8 ODII_ODIInd9 ODII_ODIInd10 ODII_ODIInd11 ODII_ODIInd12 ODII_ODIInd13 ODII_ODIInd14 ODII_ODIInd15 ODII_ODIInd16 ODII_ODIInd17 ODII_ODIInd18 ODII_ODIInd19 ODII_ODIInd20 ODII_ODIInd21 ODII_ODIInd22 ODII_ODIInd23 ODII_ODIInd24 ODII_ODIInd25 ODII_ODIInd26 ODII_ODIInd27 ODII_ODIInd28 ODII_ODIInd29 ODII_ODIInd30 ODII_ODIInd31 ODII_ODIInd32 ODII_ODIInd33 ODII_ODIInd34 ODII_ODIInd35 ODII_ODIInd36 ODII_ODIInd37 ODII_ODIInd38 ODII_ODIInd39 ODII_ODIInd40 ODII_ODIInd41 ODII_ODIInd42 ODII_ODIInd43 ODII_ODIInd44 ODII_ODIInd45 ODII_ODIInd46 ODII_ODIInd47 ODII_ODIInd48 ODII_ODIInd49 ODII_ODIInd50 ODII_ODIInd51 ODII_ODIInd52 ODII_ODIInd53 ODII_ODIInd54 ODII_ODIInd55 ODII_ODIInd56;
SIG_GROUP_ 1419 ODIEnmDynData 1 : ODIEDD_Data1Value ODIEDD_Data2Value ODIEDD_Data3Value ODIEDD_Data4Value ODIEDD_Data5Value ODIEDD_Data6Value ODIEDD_Data7Value ODIEDD_Data8Value ODIEDD_Data9Value ODIEDD_Data10Value ODIEDD_Data11Value ODIEDD_Data12Value ODIEDD_Data13Value ODIEDD_Data14Value ODIEDD_Data15Value ODIEDD_Data16Value ODIEDD_Data17Value ODIEDD_Data18Value ODIEDD_FUCID;
SIG_GROUP_ 1415 ODIDynData 1 : ODD_DataType ODD_InvldData ODD_FUCID ODD_DataId ODD_DataVal;
